VERSION "created by canmatrix"

NS_ :

BS_:

BU_: Matrix

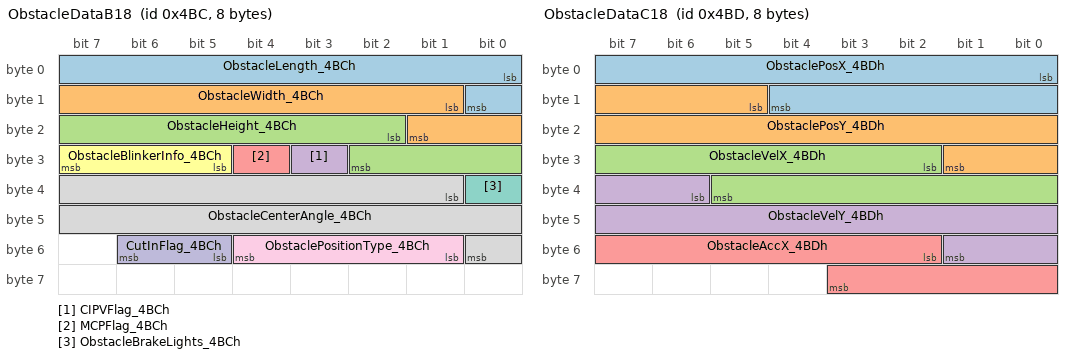
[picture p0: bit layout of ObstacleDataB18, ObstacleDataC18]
BO_ 1212 ObstacleDataB18: 8 Matrix
 SG_ ObstacleLength_4BCh : 0|9@1+ (0.05,0) [0.0|25.6] "m" Vector__XXX
 SG_ ObstacleWidth_4BCh : 9|9@1+ (0.02,0) [0.0|10.24] "m" Vector__XXX
 SG_ ObstacleHeight_4BCh : 18|9@1+ (0.02,0) [0.0|10.24] "m" Vector__XXX
 SG_ CIPVFlag_4BCh : 27|1@1+ (1,0) [0.0|1.0] "bool" Vector__XXX
 SG_ MCPFlag_4BCh : 28|1@1+ (1,0) [0.0|1.0] "bool" Vector__XXX
 SG_ ObstacleBlinkerInfo_4BCh : 29|3@1+ (1,0) [0.0|7.0] "enum" Vector__XXX
 SG_ ObstacleBrakeLights_4BCh : 32|1@1+ (1,0) [0.0|1.0] "bool" Vector__XXX
 SG_ ObstacleCenterAngle_4BCh : 33|16@1+ (0.01,-327.68) [-327.68|327.67] "degree" Vector__XXX
 SG_ ObstaclePositionType_4BCh : 49|4@1+ (1,0) [0.0|15.0] "enum" Vector__XXX
 SG_ CutInFlag_4BCh : 53|2@1+ (1,0) [0.0|3.0] "bool" Vector__XXX

BO_ 1213 ObstacleDataC18: 8 Matrix
 SG_ ObstaclePosX_4BDh : 0|13@1+ (0.0625,-250) [-250.0|250.0] "m" Vector__XXX
 SG_ ObstaclePosY_4BDh : 13|13@1+ (0.0625,-250) [-250.0|250.0] "m" Vector__XXX
 SG_ ObstacleVelX_4BDh : 26|12@1+ (0.05,-102.4) [-102.4|102.35] "m/sec" Vector__XXX
 SG_ ObstacleVelY_4BDh : 38|12@1+ (0.05,-50) [-50.0|50.0] "m/sec" Vector__XXX
 SG_ ObstacleAccX_4BDh : 50|10@1+ (0.03,-14.97) [-14.97|14.97] "m/s^2" Vector__XXX

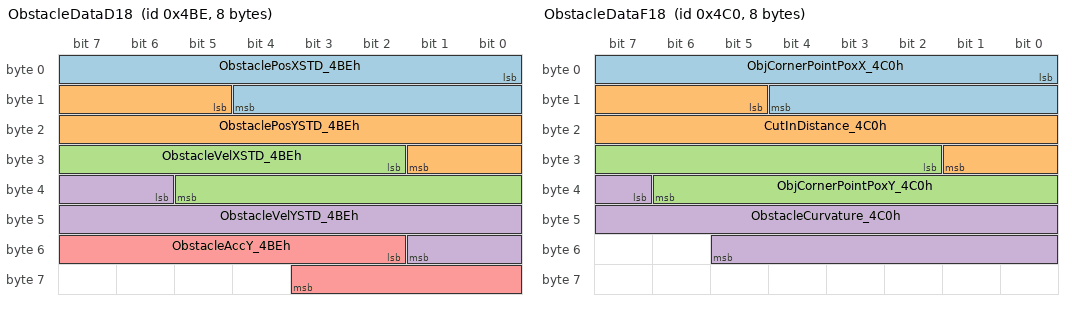
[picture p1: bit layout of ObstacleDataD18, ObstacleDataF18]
BO_ 1214 ObstacleDataD18: 8 Matrix
 SG_ ObstaclePosXSTD_4BEh : 0|13@1+ (0.0625,0) [0.0|250.0] "m" Vector__XXX
 SG_ ObstaclePosYSTD_4BEh : 13|13@1+ (0.0625,0) [0.0|250.0] "m" Vector__XXX
 SG_ ObstacleVelXSTD_4BEh : 26|12@1+ (0.05,0) [0.0|102.35] "m/sec" Vector__XXX
 SG_ ObstacleVelYSTD_4BEh : 38|12@1+ (0.05,0) [0.0|50.0] "m/sec" Vector__XXX
 SG_ ObstacleAccY_4BEh : 50|10@1+ (0.03,-14.97) [-14.97|14.97] "m/s^2" Vector__XXX

BO_ 1215 ObstacleDataE18: 8 Matrix
 SG_ ObstacleAngle_4BFh : 0|16@1+ (0.01,-327.68) [-327.68|327.67] "degree" Vector__XXX
 SG_ ObstacleAngleStd_4BFh : 16|16@1+ (0.01,0) [0.0|327.67] "degree" Vector__XXX
 SG_ ObstacleVelXAbs_4BFh : 32|12@1+ (0.05,-102.4) [-102.4|102.35] "m/sec" Vector__XXX
 SG_ ObstacleVelYAbs_4BFh : 44|12@1+ (0.05,-50) [-50.0|50.0] "m/sec" Vector__XXX

BO_ 1216 ObstacleDataF18: 8 Matrix
 SG_ ObjCornerPointPoxX_4C0h : 0|13@1+ (0.0625,-250) [-250.0|250.0] "m" Vector__XXX
 SG_ CutInDistance_4C0h : 13|13@1+ (0.0625,-250) [-250.0|250.0] "m" Vector__XXX
 SG_ ObjCornerPointPoxY_4C0h : 26|13@1+ (0.0625,-250) [-250.0|250.0] "m" Vector__XXX
 SG_ ObstacleCurvature_4C0h : 39|15@1+ (1,-9999) [-9999.0|9999.0] "m" Vector__XXX

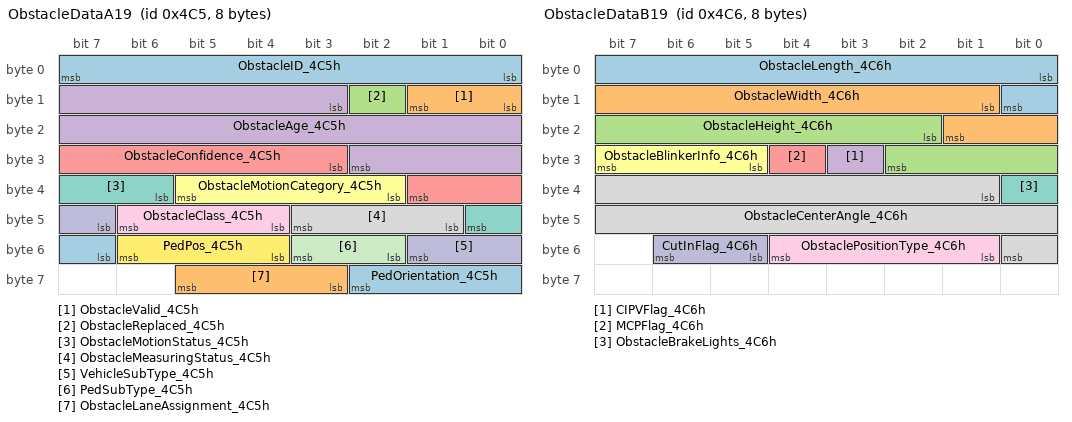
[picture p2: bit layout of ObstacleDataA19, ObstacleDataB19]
BO_ 1221 ObstacleDataA19: 8 Matrix
 SG_ ObstacleID_4C5h : 0|8@1+ (1,0) [0.0|255.0] "NA" Vector__XXX
 SG_ ObstacleValid_4C5h : 8|2@1+ (1,0) [0.0|3.0] "bool" Vector__XXX
 SG_ ObstacleReplaced_4C5h : 10|1@1+ (1,0) [0.0|1.0] "bool" Vector__XXX
 SG_ ObstacleAge_4C5h : 11|16@1+ (1,0) [0.0|65535.0] "NA" Vector__XXX
 SG_ ObstacleConfidence_4C5h : 27|7@1+ (1,0) [0.0|100.0] "NA" Vector__XXX
 SG_ ObstacleMotionCategory_4C5h : 34|4@1+ (1,0) [0.0|15.0] "enum" Vector__XXX
 SG_ ObstacleMotionStatus_4C5h : 38|3@1+ (1,0) [0.0|7.0] "enum" Vector__XXX
 SG_ ObstacleMeasuringStatus_4C5h : 41|3@1+ (1,0) [0.0|7.0] "enum" Vector__XXX
 SG_ ObstacleClass_4C5h : 44|3@1+ (1,0) [0.0|7.0] "enum" Vector__XXX
 SG_ VehicleSubType_4C5h : 47|3@1+ (1,0) [0.0|7.0] "enum" Vector__XXX
 SG_ PedSubType_4C5h : 50|2@1+ (1,0) [0.0|3.0] "enum" Vector__XXX
 SG_ PedPos_4C5h : 52|3@1+ (1,0) [0.0|7.0] "enum" Vector__XXX
 SG_ PedOrientation_4C5h : 55|4@1+ (1,0) [0.0|15.0] "enum" Vector__XXX
 SG_ ObstacleLaneAssignment_4C5h : 59|3@1+ (1,0) [0.0|7.0] "enum" Vector__XXX

BO_ 1222 ObstacleDataB19: 8 Matrix
 SG_ ObstacleLength_4C6h : 0|9@1+ (0.05,0) [0.0|25.6] "m" Vector__XXX
 SG_ ObstacleWidth_4C6h : 9|9@1+ (0.02,0) [0.0|10.24] "m" Vector__XXX
 SG_ ObstacleHeight_4C6h : 18|9@1+ (0.02,0) [0.0|10.24] "m" Vector__XXX
 SG_ CIPVFlag_4C6h : 27|1@1+ (1,0) [0.0|1.0] "bool" Vector__XXX
 SG_ MCPFlag_4C6h : 28|1@1+ (1,0) [0.0|1.0] "bool" Vector__XXX
 SG_ ObstacleBlinkerInfo_4C6h : 29|3@1+ (1,0) [0.0|7.0] "enum" Vector__XXX
 SG_ ObstacleBrakeLights_4C6h : 32|1@1+ (1,0) [0.0|1.0] "bool" Vector__XXX
 SG_ ObstacleCenterAngle_4C6h : 33|16@1+ (0.01,-327.68) [-327.68|327.67] "degree" Vector__XXX
 SG_ ObstaclePositionType_4C6h : 49|4@1+ (1,0) [0.0|15.0] "enum" Vector__XXX
 SG_ CutInFlag_4C6h : 53|2@1+ (1,0) [0.0|3.0] "bool" Vector__XXX

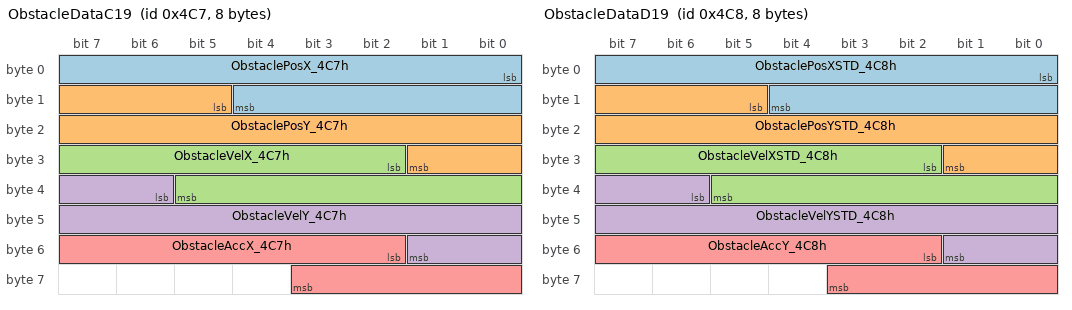
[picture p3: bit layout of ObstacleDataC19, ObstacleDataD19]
BO_ 1223 ObstacleDataC19: 8 Matrix
 SG_ ObstaclePosX_4C7h : 0|13@1+ (0.0625,-250) [-250.0|250.0] "m" Vector__XXX
 SG_ ObstaclePosY_4C7h : 13|13@1+ (0.0625,-250) [-250.0|250.0] "m" Vector__XXX
 SG_ ObstacleVelX_4C7h : 26|12@1+ (0.05,-102.4) [-102.4|102.35] "m/sec" Vector__XXX
 SG_ ObstacleVelY_4C7h : 38|12@1+ (0.05,-50) [-50.0|50.0] "m/sec" Vector__XXX
 SG_ ObstacleAccX_4C7h : 50|10@1+ (0.03,-14.97) [-14.97|14.97] "m/s^2" Vector__XXX

BO_ 1224 ObstacleDataD19: 8 Matrix
 SG_ ObstaclePosXSTD_4C8h : 0|13@1+ (0.0625,0) [0.0|250.0] "m" Vector__XXX
 SG_ ObstaclePosYSTD_4C8h : 13|13@1+ (0.0625,0) [0.0|250.0] "m" Vector__XXX
 SG_ ObstacleVelXSTD_4C8h : 26|12@1+ (0.05,0) [0.0|102.35] "m/sec" Vector__XXX
 SG_ ObstacleVelYSTD_4C8h : 38|12@1+ (0.05,0) [0.0|50.0] "m/sec" Vector__XXX
 SG_ ObstacleAccY_4C8h : 50|10@1+ (0.03,-14.97) [-14.97|14.97] "m/s^2" Vector__XXX

BO_ 1225 ObstacleDataE19: 8 Matrix
 SG_ ObstacleAngle_4C9h : 0|16@1+ (0.01,-327.68) [-327.68|327.67] "degree" Vector__XXX
 SG_ ObstacleAngleStd_4C9h : 16|16@1+ (0.01,0) [0.0|327.67] "degree" Vector__XXX
 SG_ ObstacleVelXAbs_4C9h : 32|12@1+ (0.05,-102.4) [-102.4|102.35] "m/sec" Vector__XXX
 SG_ ObstacleVelYAbs_4C9h : 44|12@1+ (0.05,-50) [-50.0|50.0] "m/sec" Vector__XXX

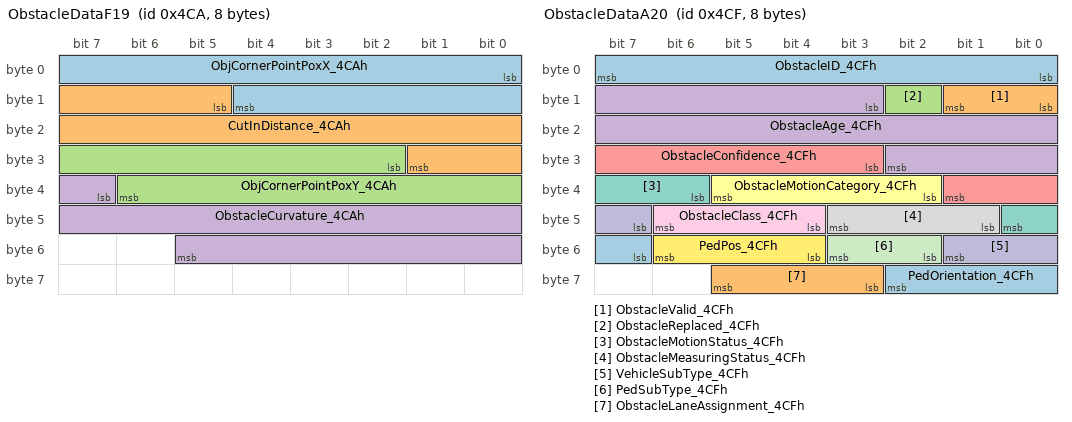
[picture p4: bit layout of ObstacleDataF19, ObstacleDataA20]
BO_ 1226 ObstacleDataF19: 8 Matrix
 SG_ ObjCornerPointPoxX_4CAh : 0|13@1+ (0.0625,-250) [-250.0|250.0] "m" Vector__XXX
 SG_ CutInDistance_4CAh : 13|13@1+ (0.0625,-250) [-250.0|250.0] "m" Vector__XXX
 SG_ ObjCornerPointPoxY_4CAh : 26|13@1+ (0.0625,-250) [-250.0|250.0] "m" Vector__XXX
 SG_ ObstacleCurvature_4CAh : 39|15@1+ (1,-9999) [-9999.0|9999.0] "m" Vector__XXX

BO_ 1231 ObstacleDataA20: 8 Matrix
 SG_ ObstacleID_4CFh : 0|8@1+ (1,0) [0.0|255.0] "NA" Vector__XXX
 SG_ ObstacleValid_4CFh : 8|2@1+ (1,0) [0.0|3.0] "bool" Vector__XXX
 SG_ ObstacleReplaced_4CFh : 10|1@1+ (1,0) [0.0|1.0] "bool" Vector__XXX
 SG_ ObstacleAge_4CFh : 11|16@1+ (1,0) [0.0|65535.0] "NA" Vector__XXX
 SG_ ObstacleConfidence_4CFh : 27|7@1+ (1,0) [0.0|100.0] "NA" Vector__XXX
 SG_ ObstacleMotionCategory_4CFh : 34|4@1+ (1,0) [0.0|15.0] "enum" Vector__XXX
 SG_ ObstacleMotionStatus_4CFh : 38|3@1+ (1,0) [0.0|7.0] "enum" Vector__XXX
 SG_ ObstacleMeasuringStatus_4CFh : 41|3@1+ (1,0) [0.0|7.0] "enum" Vector__XXX
 SG_ ObstacleClass_4CFh : 44|3@1+ (1,0) [0.0|7.0] "enum" Vector__XXX
 SG_ VehicleSubType_4CFh : 47|3@1+ (1,0) [0.0|7.0] "enum" Vector__XXX
 SG_ PedSubType_4CFh : 50|2@1+ (1,0) [0.0|3.0] "enum" Vector__XXX
 SG_ PedPos_4CFh : 52|3@1+ (1,0) [0.0|7.0] "enum" Vector__XXX
 SG_ PedOrientation_4CFh : 55|4@1+ (1,0) [0.0|15.0] "enum" Vector__XXX
 SG_ ObstacleLaneAssignment_4CFh : 59|3@1+ (1,0) [0.0|7.0] "enum" Vector__XXX

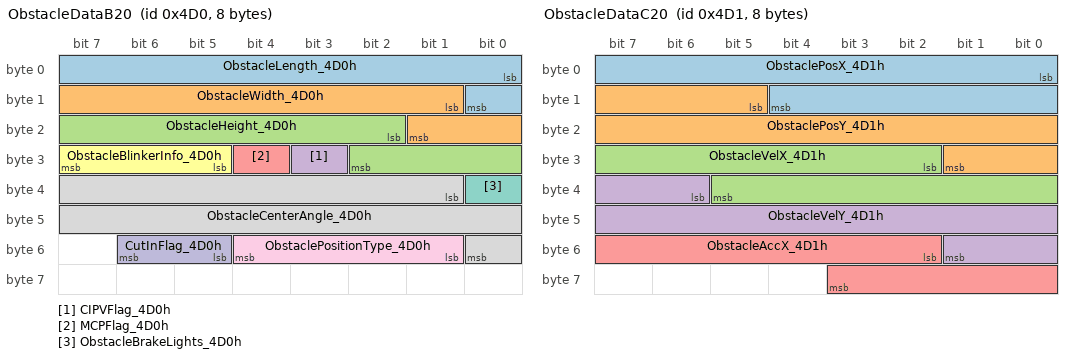
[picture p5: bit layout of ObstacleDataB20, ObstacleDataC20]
BO_ 1232 ObstacleDataB20: 8 Matrix
 SG_ ObstacleLength_4D0h : 0|9@1+ (0.05,0) [0.0|25.6] "m" Vector__XXX
 SG_ ObstacleWidth_4D0h : 9|9@1+ (0.02,0) [0.0|10.24] "m" Vector__XXX
 SG_ ObstacleHeight_4D0h : 18|9@1+ (0.02,0) [0.0|10.24] "m" Vector__XXX
 SG_ CIPVFlag_4D0h : 27|1@1+ (1,0) [0.0|1.0] "bool" Vector__XXX
 SG_ MCPFlag_4D0h : 28|1@1+ (1,0) [0.0|1.0] "bool" Vector__XXX
 SG_ ObstacleBlinkerInfo_4D0h : 29|3@1+ (1,0) [0.0|7.0] "enum" Vector__XXX
 SG_ ObstacleBrakeLights_4D0h : 32|1@1+ (1,0) [0.0|1.0] "bool" Vector__XXX
 SG_ ObstacleCenterAngle_4D0h : 33|16@1+ (0.01,-327.68) [-327.68|327.67] "degree" Vector__XXX
 SG_ ObstaclePositionType_4D0h : 49|4@1+ (1,0) [0.0|15.0] "enum" Vector__XXX
 SG_ CutInFlag_4D0h : 53|2@1+ (1,0) [0.0|3.0] "bool" Vector__XXX

BO_ 1233 ObstacleDataC20: 8 Matrix
 SG_ ObstaclePosX_4D1h : 0|13@1+ (0.0625,-250) [-250.0|250.0] "m" Vector__XXX
 SG_ ObstaclePosY_4D1h : 13|13@1+ (0.0625,-250) [-250.0|250.0] "m" Vector__XXX
 SG_ ObstacleVelX_4D1h : 26|12@1+ (0.05,-102.4) [-102.4|102.35] "m/sec" Vector__XXX
 SG_ ObstacleVelY_4D1h : 38|12@1+ (0.05,-50) [-50.0|50.0] "m/sec" Vector__XXX
 SG_ ObstacleAccX_4D1h : 50|10@1+ (0.03,-14.97) [-14.97|14.97] "m/s^2" Vector__XXX

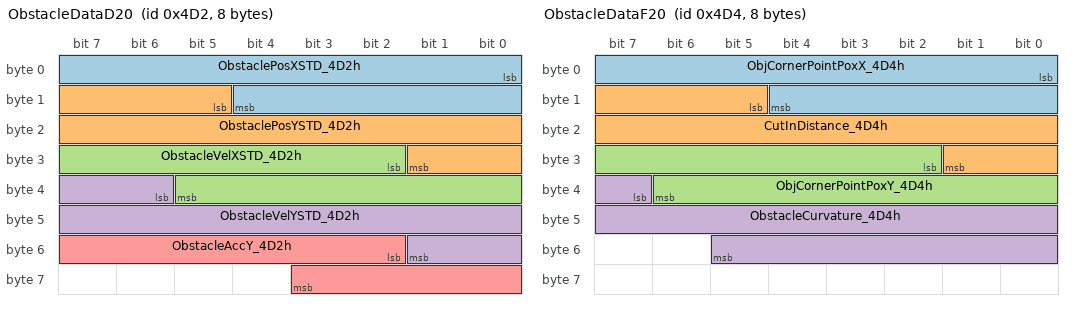
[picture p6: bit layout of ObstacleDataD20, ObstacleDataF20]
BO_ 1234 ObstacleDataD20: 8 Matrix
 SG_ ObstaclePosXSTD_4D2h : 0|13@1+ (0.0625,0) [0.0|250.0] "m" Vector__XXX
 SG_ ObstaclePosYSTD_4D2h : 13|13@1+ (0.0625,0) [0.0|250.0] "m" Vector__XXX
 SG_ ObstacleVelXSTD_4D2h : 26|12@1+ (0.05,0) [0.0|102.35] "m/sec" Vector__XXX
 SG_ ObstacleVelYSTD_4D2h : 38|12@1+ (0.05,0) [0.0|50.0] "m/sec" Vector__XXX
 SG_ ObstacleAccY_4D2h : 50|10@1+ (0.03,-14.97) [-14.97|14.97] "m/s^2" Vector__XXX

BO_ 1235 ObstacleDataE20: 8 Matrix
 SG_ ObstacleAngle_4D3h : 0|16@1+ (0.01,-327.68) [-327.68|327.67] "degree" Vector__XXX
 SG_ ObstacleAngleStd_4D3h : 16|16@1+ (0.01,0) [0.0|327.67] "degree" Vector__XXX
 SG_ ObstacleVelXAbs_4D3h : 32|12@1+ (0.05,-102.4) [-102.4|102.35] "m/sec" Vector__XXX
 SG_ ObstacleVelYAbs_4D3h : 44|12@1+ (0.05,-50) [-50.0|50.0] "m/sec" Vector__XXX

BO_ 1236 ObstacleDataF20: 8 Matrix
 SG_ ObjCornerPointPoxX_4D4h : 0|13@1+ (0.0625,-250) [-250.0|250.0] "m" Vector__XXX
 SG_ CutInDistance_4D4h : 13|13@1+ (0.0625,-250) [-250.0|250.0] "m" Vector__XXX
 SG_ ObjCornerPointPoxY_4D4h : 26|13@1+ (0.0625,-250) [-250.0|250.0] "m" Vector__XXX
 SG_ ObstacleCurvature_4D4h : 39|15@1+ (1,-9999) [-9999.0|9999.0] "m" Vector__XXX

BO_ 1241 ObstacleInternalID12: 8 Matrix
 SG_ Obstacle_Internal_ID1_4D9h : 0|32@1+ (1,0) [0.0|4294970000.0] "NA" Vector__XXX
 SG_ Obstacle_Internal_ID2_4D9h : 32|32@1+ (1,0) [0.0|4294970000.0] "NA" Vector__XXX

BO_ 1242 ObstacleInternalID34: 8 Matrix
 SG_ Obstacle_Internal_ID3_4DAh : 0|32@1+ (1,0) [0.0|4294970000.0] "NA" Vector__XXX
 SG_ Obstacle_Internal_ID4_4DAh : 32|32@1+ (1,0) [0.0|4294970000.0] "NA" Vector__XXX

BO_ 1243 ObstacleInternalID56: 8 Matrix
 SG_ Obstacle_Internal_ID5_4DBh : 0|32@1+ (1,0) [0.0|4294970000.0] "NA" Vector__XXX
 SG_ Obstacle_Internal_ID6_4DBh : 32|32@1+ (1,0) [0.0|4294970000.0] "NA" Vector__XXX

BO_ 1244 ObstacleInternalID78: 8 Matrix
 SG_ Obstacle_Internal_ID7_4DCh : 0|32@1+ (1,0) [0.0|4294970000.0] "NA" Vector__XXX
 SG_ Obstacle_Internal_ID8_4DCh : 32|32@1+ (1,0) [0.0|4294970000.0] "NA" Vector__XXX

BO_ 1245 ObstacleInternalID90: 8 Matrix
 SG_ Obstacle_Internal_ID9_4DDh : 0|32@1+ (1,0) [0.0|4294970000.0] "NA" Vector__XXX
 SG_ Obstacle_Internal_ID10_4DDh : 32|32@1+ (1,0) [0.0|4294970000.0] "NA" Vector__XXX

BO_ 1246 ObstacleInternalID1112: 8 Matrix
 SG_ Obstacle_Internal_ID11_4DEh : 0|32@1+ (1,0) [0.0|4294970000.0] "NA" Vector__XXX
 SG_ Obstacle_Internal_ID12_4DEh : 32|32@1+ (1,0) [0.0|4294970000.0] "NA" Vector__XXX

BO_ 1247 ObstacleInternalID1314: 8 Matrix
 SG_ Obstacle_Internal_ID13_4DFh : 0|32@1+ (1,0) [0.0|4294970000.0] "NA" Vector__XXX
 SG_ Obstacle_Internal_ID14_4DFh : 32|32@1+ (1,0) [0.0|4294970000.0] "NA" Vector__XXX

BO_ 1248 ObstacleInternalID1516: 8 Matrix
 SG_ Obstacle_Internal_ID15_4E0h : 0|32@1+ (1,0) [0.0|4294970000.0] "NA" Vector__XXX
 SG_ Obstacle_Internal_ID16_4E0h : 32|32@1+ (1,0) [0.0|4294970000.0] "NA" Vector__XXX

BO_ 1249 ObstacleInternalID1718: 8 Matrix
 SG_ Obstacle_Internal_ID17_4E1h : 0|32@1+ (1,0) [0.0|4294970000.0] "NA" Vector__XXX
 SG_ Obstacle_Internal_ID18_4E1h : 32|32@1+ (1,0) [0.0|4294970000.0] "NA" Vector__XXX

BO_ 1250 ObstacleInternalID1920: 8 Matrix
 SG_ Obstacle_Internal_ID19_4E2h : 0|32@1+ (1,0) [0.0|4294970000.0] "NA" Vector__XXX
 SG_ Obstacle_Internal_ID20_4E2h : 32|32@1+ (1,0) [0.0|4294970000.0] "NA" Vector__XXX

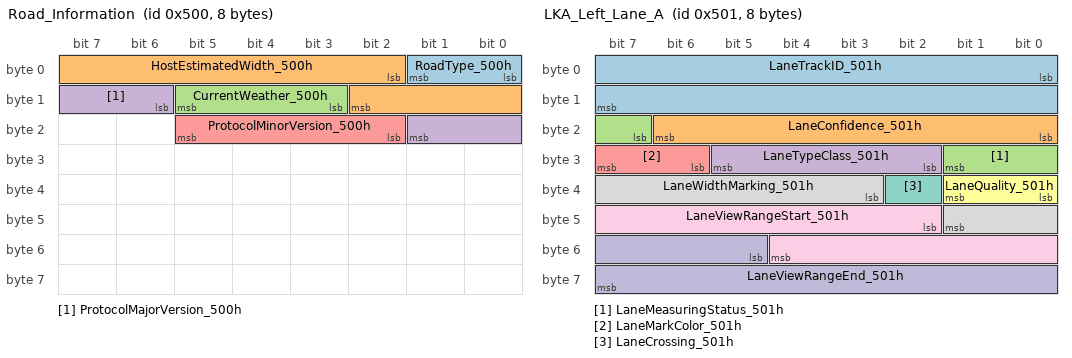
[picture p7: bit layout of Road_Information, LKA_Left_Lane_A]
BO_ 1280 Road_Information: 8 Matrix
 SG_ RoadType_500h : 0|2@1+ (1,0) [0.0|3.0] "Enum" Vector__XXX
 SG_ HostEstimatedWidth_500h : 2|9@1+ (1,0) [0.0|4.0] "meter" Vector__XXX
 SG_ CurrentWeather_500h : 11|3@1+ (1,0) [0.0|7.0] "Enum" Vector__XXX
 SG_ ProtocolMajorVersion_500h : 14|4@1+ (1,0) [0.0|15.0] "NA" Vector__XXX
 SG_ ProtocolMinorVersion_500h : 18|4@1+ (1,0) [0.0|15.0] "NA" Vector__XXX

BO_ 1281 LKA_Left_Lane_A: 8 Matrix
 SG_ LaneTrackID_501h : 0|16@1+ (1,0) [0.0|65535.0] "NA" Vector__XXX
 SG_ LaneConfidence_501h : 16|7@1+ (1,0) [0.0|100.0] "prob" Vector__XXX
 SG_ LaneMeasuringStatus_501h : 23|3@1+ (1,0) [0.0|7.0] "enum" Vector__XXX
 SG_ LaneTypeClass_501h : 26|4@1+ (1,0) [0.0|15.0] "Enum" Vector__XXX
 SG_ LaneMarkColor_501h : 30|2@1+ (1,0) [0.0|3.0] "Enum" Vector__XXX
 SG_ LaneQuality_501h : 32|2@1+ (1,0) [0.0|3.0] "Enum" Vector__XXX
 SG_ LaneCrossing_501h : 34|1@1+ (1,0) [0.0|1.0] "NA" Vector__XXX
 SG_ LaneWidthMarking_501h : 35|7@1+ (0.01,0) [0.0|127.0] "m" Vector__XXX
 SG_ LaneViewRangeStart_501h : 42|11@1+ (0.1,0) [0.0|200.0] "meter" Vector__XXX
 SG_ LaneViewRangeEnd_501h : 53|11@1+ (0.1,0) [0.0|200.0] "meter" Vector__XXX

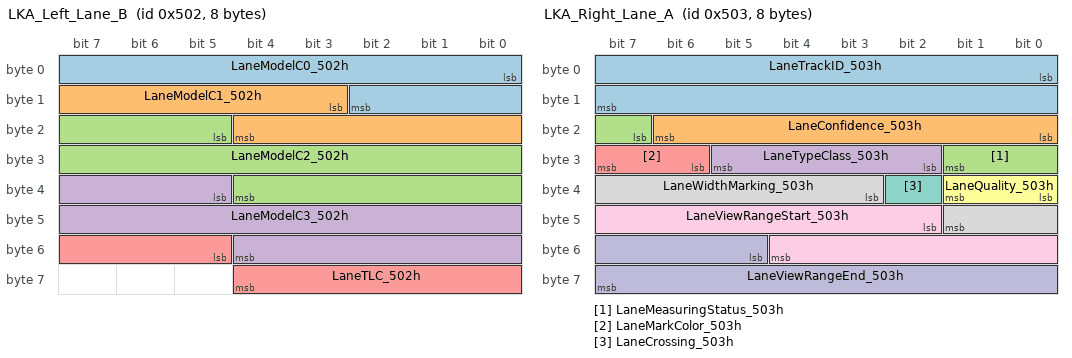
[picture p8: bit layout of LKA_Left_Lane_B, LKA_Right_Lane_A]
BO_ 1282 LKA_Left_Lane_B: 8 Matrix
 SG_ LaneModelC0_502h : 0|11@1+ (0.01,-10) [-10.0|10.0] "meter" Vector__XXX
 SG_ LaneModelC1_502h : 11|10@1+ (0.000976562,-0.357) [-0.357|0.357] "rad" Vector__XXX
 SG_ LaneModelC2_502h : 21|16@1+ (9.77e-07,-0.032) [-0.032|0.032] "1/meter" Vector__XXX
 SG_ LaneModelC3_502h : 37|16@1+ (3.72529e-09,-0.000122) [-0.000122|0.000122] "1/meter^2" Vector__XXX
 SG_ LaneTLC_502h : 53|8@1+ (0.01,0) [0.0|2.0] "s" Vector__XXX

BO_ 1283 LKA_Right_Lane_A: 8 Matrix
 SG_ LaneTrackID_503h : 0|16@1+ (1,0) [0.0|65535.0] "NA" Vector__XXX
 SG_ LaneConfidence_503h : 16|7@1+ (1,0) [0.0|100.0] "prob" Vector__XXX
 SG_ LaneMeasuringStatus_503h : 23|3@1+ (1,0) [0.0|7.0] "enum" Vector__XXX
 SG_ LaneTypeClass_503h : 26|4@1+ (1,0) [0.0|15.0] "Enum" Vector__XXX
 SG_ LaneMarkColor_503h : 30|2@1+ (1,0) [0.0|3.0] "Enum" Vector__XXX
 SG_ LaneQuality_503h : 32|2@1+ (1,0) [0.0|3.0] "Enum" Vector__XXX
 SG_ LaneCrossing_503h : 34|1@1+ (1,0) [0.0|1.0] "NA" Vector__XXX
 SG_ LaneWidthMarking_503h : 35|7@1+ (0.01,0) [0.0|127.0] "m" Vector__XXX
 SG_ LaneViewRangeStart_503h : 42|11@1+ (0.1,0) [0.0|200.0] "meter" Vector__XXX
 SG_ LaneViewRangeEnd_503h : 53|11@1+ (0.1,0) [0.0|200.0] "meter" Vector__XXX

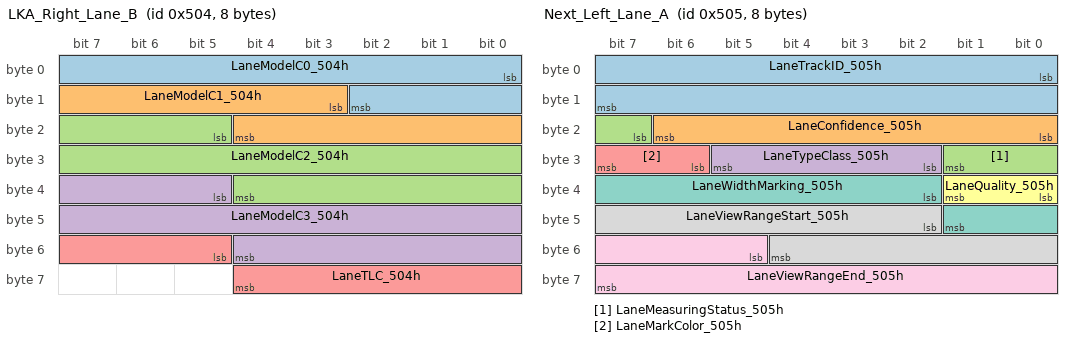
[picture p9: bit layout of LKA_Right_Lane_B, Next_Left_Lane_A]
BO_ 1284 LKA_Right_Lane_B: 8 Matrix
 SG_ LaneModelC0_504h : 0|11@1+ (0.01,-10) [-10.0|10.0] "meter" Vector__XXX
 SG_ LaneModelC1_504h : 11|10@1+ (0.000976562,-0.357) [-0.357|0.357] "rad" Vector__XXX
 SG_ LaneModelC2_504h : 21|16@1+ (9.77e-07,-0.032) [-0.032|0.032] "1/meter" Vector__XXX
 SG_ LaneModelC3_504h : 37|16@1+ (3.72529e-09,-0.000122) [-0.000122|0.000122] "1/meter^2" Vector__XXX
 SG_ LaneTLC_504h : 53|8@1+ (0.01,0) [0.0|2.0] "s" Vector__XXX

BO_ 1285 Next_Left_Lane_A: 8 Matrix
 SG_ LaneTrackID_505h : 0|16@1+ (1,0) [0.0|65535.0] "NA" Vector__XXX
 SG_ LaneConfidence_505h : 16|7@1+ (1,0) [0.0|100.0] "prob" Vector__XXX
 SG_ LaneMeasuringStatus_505h : 23|3@1+ (1,0) [0.0|7.0] "enum" Vector__XXX
 SG_ LaneTypeClass_505h : 26|4@1+ (1,0) [0.0|15.0] "Enum" Vector__XXX
 SG_ LaneMarkColor_505h : 30|2@1+ (1,0) [0.0|3.0] "Enum" Vector__XXX
 SG_ LaneQuality_505h : 32|2@1+ (1,0) [0.0|3.0] "Enum" Vector__XXX
 SG_ LaneWidthMarking_505h : 34|8@1+ (0.01,0) [0.0|255.0] "m" Vector__XXX
 SG_ LaneViewRangeStart_505h : 42|11@1+ (0.1,0) [0.0|200.0] "meter" Vector__XXX
 SG_ LaneViewRangeEnd_505h : 53|11@1+ (0.1,0) [0.0|200.0] "meter" Vector__XXX

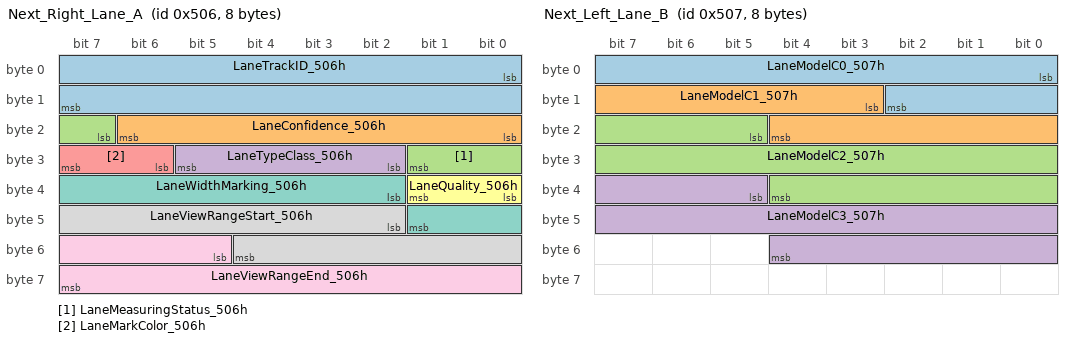
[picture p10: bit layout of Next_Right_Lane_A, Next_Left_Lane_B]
BO_ 1286 Next_Right_Lane_A: 8 Matrix
 SG_ LaneTrackID_506h : 0|16@1+ (1,0) [0.0|65535.0] "NA" Vector__XXX
 SG_ LaneConfidence_506h : 16|7@1+ (1,0) [0.0|100.0] "prob" Vector__XXX
 SG_ LaneMeasuringStatus_506h : 23|3@1+ (1,0) [0.0|7.0] "enum" Vector__XXX
 SG_ LaneTypeClass_506h : 26|4@1+ (1,0) [0.0|15.0] "Enum" Vector__XXX
 SG_ LaneMarkColor_506h : 30|2@1+ (1,0) [0.0|3.0] "Enum" Vector__XXX
 SG_ LaneQuality_506h : 32|2@1+ (1,0) [0.0|3.0] "Enum" Vector__XXX
 SG_ LaneWidthMarking_506h : 34|8@1+ (0.01,0) [0.0|255.0] "m" Vector__XXX
 SG_ LaneViewRangeStart_506h : 42|11@1+ (0.1,0) [0.0|200.0] "meter" Vector__XXX
 SG_ LaneViewRangeEnd_506h : 53|11@1+ (0.1,0) [0.0|200.0] "meter" Vector__XXX

BO_ 1287 Next_Left_Lane_B: 8 Matrix
 SG_ LaneModelC0_507h : 0|11@1+ (0.01,-10) [-10.0|10.0] "meter" Vector__XXX
 SG_ LaneModelC1_507h : 11|10@1+ (0.000976562,-0.357) [-0.357|0.357] "rad" Vector__XXX
 SG_ LaneModelC2_507h : 21|16@1+ (9.77e-07,-0.032) [-0.032|0.032] "1/meter" Vector__XXX
 SG_ LaneModelC3_507h : 37|16@1+ (3.72529e-09,-0.000122) [-0.000122|0.000122] "1/meter^2" Vector__XXX

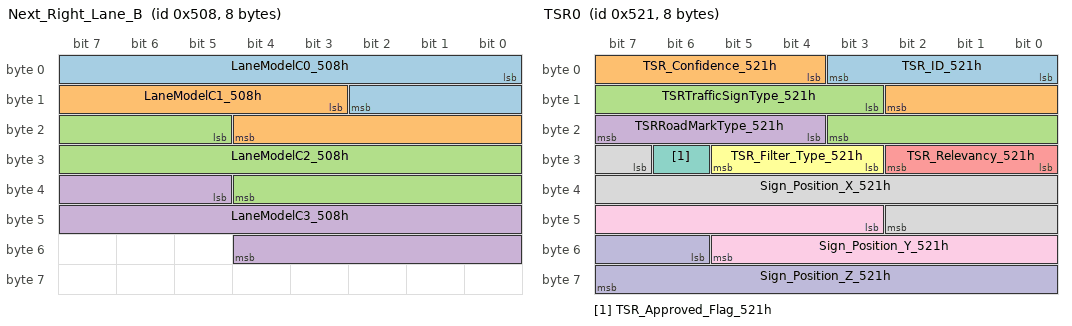
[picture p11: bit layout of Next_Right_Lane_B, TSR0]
BO_ 1288 Next_Right_Lane_B: 8 Matrix
 SG_ LaneModelC0_508h : 0|11@1+ (0.01,-10) [-10.0|10.0] "meter" Vector__XXX
 SG_ LaneModelC1_508h : 11|10@1+ (0.000976562,-0.357) [-0.357|0.357] "rad" Vector__XXX
 SG_ LaneModelC2_508h : 21|16@1+ (9.77e-07,-0.032) [-0.032|0.032] "1/meter" Vector__XXX
 SG_ LaneModelC3_508h : 37|16@1+ (3.72529e-09,-0.000122) [-0.000122|0.000122] "1/meter^2" Vector__XXX

BO_ 1312 TSR_Header: 8 Matrix
 SG_ TSRObjectsNumber_520h : 0|4@1+ (1,0) [0.0|8.0] "uint" Vector__XXX
 SG_ ProtocolMajorVersion_520h : 4|4@1+ (1,0) [0.0|15.0] "NA" Vector__XXX
 SG_ ProtocolMinorVersion_520h : 8|4@1+ (1,0) [0.0|15.0] "NA" Vector__XXX

BO_ 1313 TSR0: 8 Matrix
 SG_ TSR_ID_521h : 0|4@1+ (1,0) [0.0|15.0] "NA" Vector__XXX
 SG_ TSR_Confidence_521h : 4|7@1+ (1,0) [0.0|100.0] "NA" Vector__XXX
 SG_ TSRTrafficSignType_521h : 11|9@1+ (1,0) [0.0|511.0] "ENUM" Vector__XXX
 SG_ TSRRoadMarkType_521h : 20|4@1+ (1,0) [0.0|15.0] "ENUM" Vector__XXX
 SG_ TSR_Relevancy_521h : 24|3@1+ (1,0) [0.0|7.0] "ENUM" Vector__XXX
 SG_ TSR_Filter_Type_521h : 27|3@1+ (1,0) [0.0|7.0] "ENUM" Vector__XXX
 SG_ TSR_Approved_Flag_521h : 30|1@1+ (1,0) [0.0|1.0] "bool" Vector__XXX
 SG_ Sign_Position_X_521h : 31|12@1+ (0.05,0) [0.0|200.0] "meters" Vector__XXX
 SG_ Sign_Position_Y_521h : 43|11@1+ (0.05,-32) [-32.0|32.0] "meters" Vector__XXX
 SG_ Sign_Position_Z_521h : 54|10@1+ (0.05,0) [0.0|40.0] "meters" Vector__XXX

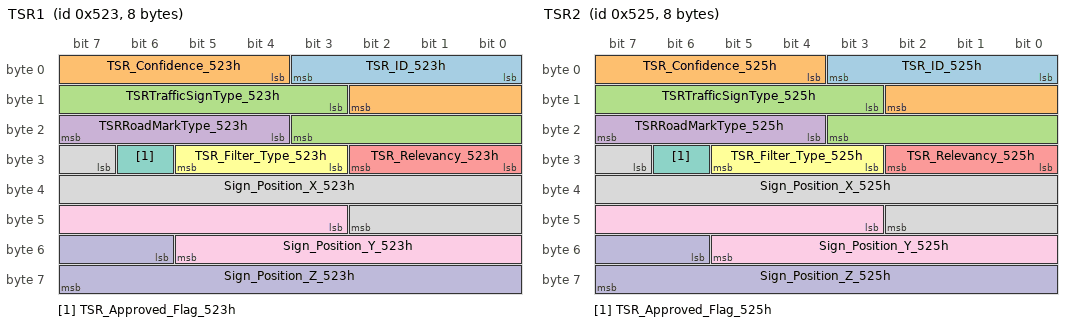
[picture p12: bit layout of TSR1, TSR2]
BO_ 1315 TSR1: 8 Matrix
 SG_ TSR_ID_523h : 0|4@1+ (1,0) [0.0|15.0] "NA" Vector__XXX
 SG_ TSR_Confidence_523h : 4|7@1+ (1,0) [0.0|100.0] "NA" Vector__XXX
 SG_ TSRTrafficSignType_523h : 11|9@1+ (1,0) [0.0|511.0] "ENUM" Vector__XXX
 SG_ TSRRoadMarkType_523h : 20|4@1+ (1,0) [0.0|15.0] "ENUM" Vector__XXX
 SG_ TSR_Relevancy_523h : 24|3@1+ (1,0) [0.0|7.0] "ENUM" Vector__XXX
 SG_ TSR_Filter_Type_523h : 27|3@1+ (1,0) [0.0|7.0] "ENUM" Vector__XXX
 SG_ TSR_Approved_Flag_523h : 30|1@1+ (1,0) [0.0|1.0] "bool" Vector__XXX
 SG_ Sign_Position_X_523h : 31|12@1+ (0.05,0) [0.0|200.0] "meters" Vector__XXX
 SG_ Sign_Position_Y_523h : 43|11@1+ (0.05,-32) [-32.0|32.0] "meters" Vector__XXX
 SG_ Sign_Position_Z_523h : 54|10@1+ (0.05,0) [0.0|40.0] "meters" Vector__XXX

BO_ 1317 TSR2: 8 Matrix
 SG_ TSR_ID_525h : 0|4@1+ (1,0) [0.0|15.0] "NA" Vector__XXX
 SG_ TSR_Confidence_525h : 4|7@1+ (1,0) [0.0|100.0] "NA" Vector__XXX
 SG_ TSRTrafficSignType_525h : 11|9@1+ (1,0) [0.0|511.0] "ENUM" Vector__XXX
 SG_ TSRRoadMarkType_525h : 20|4@1+ (1,0) [0.0|15.0] "ENUM" Vector__XXX
 SG_ TSR_Relevancy_525h : 24|3@1+ (1,0) [0.0|7.0] "ENUM" Vector__XXX
 SG_ TSR_Filter_Type_525h : 27|3@1+ (1,0) [0.0|7.0] "ENUM" Vector__XXX
 SG_ TSR_Approved_Flag_525h : 30|1@1+ (1,0) [0.0|1.0] "bool" Vector__XXX
 SG_ Sign_Position_X_525h : 31|12@1+ (0.05,0) [0.0|200.0] "meters" Vector__XXX
 SG_ Sign_Position_Y_525h : 43|11@1+ (0.05,-32) [-32.0|32.0] "meters" Vector__XXX
 SG_ Sign_Position_Z_525h : 54|10@1+ (0.05,0) [0.0|40.0] "meters" Vector__XXX

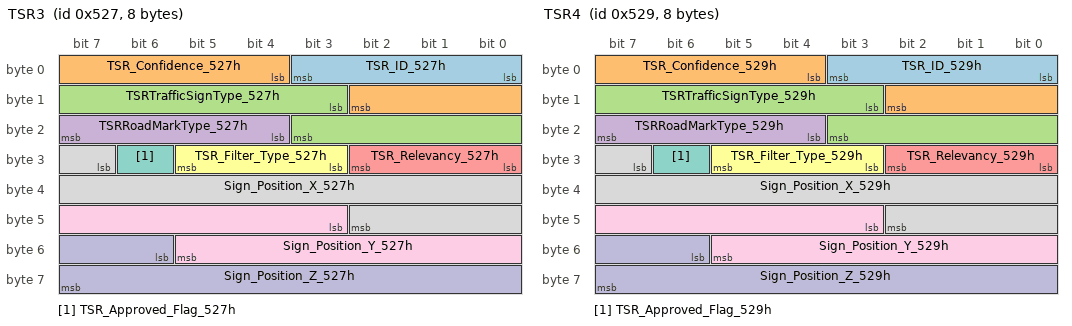
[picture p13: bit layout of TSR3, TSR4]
BO_ 1319 TSR3: 8 Matrix
 SG_ TSR_ID_527h : 0|4@1+ (1,0) [0.0|15.0] "NA" Vector__XXX
 SG_ TSR_Confidence_527h : 4|7@1+ (1,0) [0.0|100.0] "NA" Vector__XXX
 SG_ TSRTrafficSignType_527h : 11|9@1+ (1,0) [0.0|511.0] "ENUM" Vector__XXX
 SG_ TSRRoadMarkType_527h : 20|4@1+ (1,0) [0.0|15.0] "ENUM" Vector__XXX
 SG_ TSR_Relevancy_527h : 24|3@1+ (1,0) [0.0|7.0] "ENUM" Vector__XXX
 SG_ TSR_Filter_Type_527h : 27|3@1+ (1,0) [0.0|7.0] "ENUM" Vector__XXX
 SG_ TSR_Approved_Flag_527h : 30|1@1+ (1,0) [0.0|1.0] "bool" Vector__XXX
 SG_ Sign_Position_X_527h : 31|12@1+ (0.05,0) [0.0|200.0] "meters" Vector__XXX
 SG_ Sign_Position_Y_527h : 43|11@1+ (0.05,-32) [-32.0|32.0] "meters" Vector__XXX
 SG_ Sign_Position_Z_527h : 54|10@1+ (0.05,0) [0.0|40.0] "meters" Vector__XXX

BO_ 1321 TSR4: 8 Matrix
 SG_ TSR_ID_529h : 0|4@1+ (1,0) [0.0|15.0] "NA" Vector__XXX
 SG_ TSR_Confidence_529h : 4|7@1+ (1,0) [0.0|100.0] "NA" Vector__XXX
 SG_ TSRTrafficSignType_529h : 11|9@1+ (1,0) [0.0|511.0] "ENUM" Vector__XXX
 SG_ TSRRoadMarkType_529h : 20|4@1+ (1,0) [0.0|15.0] "ENUM" Vector__XXX
 SG_ TSR_Relevancy_529h : 24|3@1+ (1,0) [0.0|7.0] "ENUM" Vector__XXX
 SG_ TSR_Filter_Type_529h : 27|3@1+ (1,0) [0.0|7.0] "ENUM" Vector__XXX
 SG_ TSR_Approved_Flag_529h : 30|1@1+ (1,0) [0.0|1.0] "bool" Vector__XXX
 SG_ Sign_Position_X_529h : 31|12@1+ (0.05,0) [0.0|200.0] "meters" Vector__XXX
 SG_ Sign_Position_Y_529h : 43|11@1+ (0.05,-32) [-32.0|32.0] "meters" Vector__XXX
 SG_ Sign_Position_Z_529h : 54|10@1+ (0.05,0) [0.0|40.0] "meters" Vector__XXX

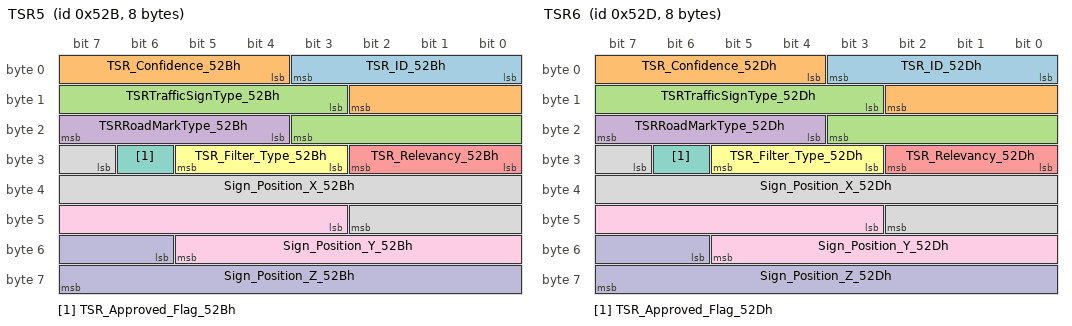
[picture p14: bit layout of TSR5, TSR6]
BO_ 1323 TSR5: 8 Matrix
 SG_ TSR_ID_52Bh : 0|4@1+ (1,0) [0.0|15.0] "NA" Vector__XXX
 SG_ TSR_Confidence_52Bh : 4|7@1+ (1,0) [0.0|100.0] "NA" Vector__XXX
 SG_ TSRTrafficSignType_52Bh : 11|9@1+ (1,0) [0.0|511.0] "ENUM" Vector__XXX
 SG_ TSRRoadMarkType_52Bh : 20|4@1+ (1,0) [0.0|15.0] "ENUM" Vector__XXX
 SG_ TSR_Relevancy_52Bh : 24|3@1+ (1,0) [0.0|7.0] "ENUM" Vector__XXX
 SG_ TSR_Filter_Type_52Bh : 27|3@1+ (1,0) [0.0|7.0] "ENUM" Vector__XXX
 SG_ TSR_Approved_Flag_52Bh : 30|1@1+ (1,0) [0.0|1.0] "bool" Vector__XXX
 SG_ Sign_Position_X_52Bh : 31|12@1+ (0.05,0) [0.0|200.0] "meters" Vector__XXX
 SG_ Sign_Position_Y_52Bh : 43|11@1+ (0.05,-32) [-32.0|32.0] "meters" Vector__XXX
 SG_ Sign_Position_Z_52Bh : 54|10@1+ (0.05,0) [0.0|40.0] "meters" Vector__XXX

BO_ 1325 TSR6: 8 Matrix
 SG_ TSR_ID_52Dh : 0|4@1+ (1,0) [0.0|15.0] "NA" Vector__XXX
 SG_ TSR_Confidence_52Dh : 4|7@1+ (1,0) [0.0|100.0] "NA" Vector__XXX
 SG_ TSRTrafficSignType_52Dh : 11|9@1+ (1,0) [0.0|511.0] "ENUM" Vector__XXX
 SG_ TSRRoadMarkType_52Dh : 20|4@1+ (1,0) [0.0|15.0] "ENUM" Vector__XXX
 SG_ TSR_Relevancy_52Dh : 24|3@1+ (1,0) [0.0|7.0] "ENUM" Vector__XXX
 SG_ TSR_Filter_Type_52Dh : 27|3@1+ (1,0) [0.0|7.0] "ENUM" Vector__XXX
 SG_ TSR_Approved_Flag_52Dh : 30|1@1+ (1,0) [0.0|1.0] "bool" Vector__XXX
 SG_ Sign_Position_X_52Dh : 31|12@1+ (0.05,0) [0.0|200.0] "meters" Vector__XXX
 SG_ Sign_Position_Y_52Dh : 43|11@1+ (0.05,-32) [-32.0|32.0] "meters" Vector__XXX
 SG_ Sign_Position_Z_52Dh : 54|10@1+ (0.05,0) [0.0|40.0] "meters" Vector__XXX

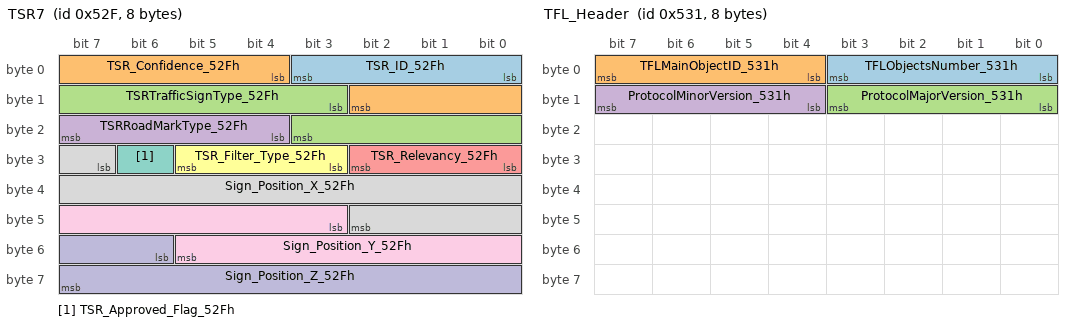
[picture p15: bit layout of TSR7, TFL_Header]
BO_ 1327 TSR7: 8 Matrix
 SG_ TSR_ID_52Fh : 0|4@1+ (1,0) [0.0|15.0] "NA" Vector__XXX
 SG_ TSR_Confidence_52Fh : 4|7@1+ (1,0) [0.0|100.0] "NA" Vector__XXX
 SG_ TSRTrafficSignType_52Fh : 11|9@1+ (1,0) [0.0|511.0] "ENUM" Vector__XXX
 SG_ TSRRoadMarkType_52Fh : 20|4@1+ (1,0) [0.0|15.0] "ENUM" Vector__XXX
 SG_ TSR_Relevancy_52Fh : 24|3@1+ (1,0) [0.0|7.0] "ENUM" Vector__XXX
 SG_ TSR_Filter_Type_52Fh : 27|3@1+ (1,0) [0.0|7.0] "ENUM" Vector__XXX
 SG_ TSR_Approved_Flag_52Fh : 30|1@1+ (1,0) [0.0|1.0] "bool" Vector__XXX
 SG_ Sign_Position_X_52Fh : 31|12@1+ (0.05,0) [0.0|200.0] "meters" Vector__XXX
 SG_ Sign_Position_Y_52Fh : 43|11@1+ (0.05,-32) [-32.0|32.0] "meters" Vector__XXX
 SG_ Sign_Position_Z_52Fh : 54|10@1+ (0.05,0) [0.0|40.0] "meters" Vector__XXX

BO_ 1329 TFL_Header: 8 Matrix
 SG_ TFLObjectsNumber_531h : 0|4@1+ (1,0) [0.0|8.0] "NA" Vector__XXX
 SG_ TFLMainObjectID_531h : 4|4@1+ (1,0) [0.0|8.0] "NA" Vector__XXX
 SG_ ProtocolMajorVersion_531h : 8|4@1+ (1,0) [0.0|15.0] "NA" Vector__XXX
 SG_ ProtocolMinorVersion_531h : 12|4@1+ (1,0) [0.0|15.0] "NA" Vector__XXX

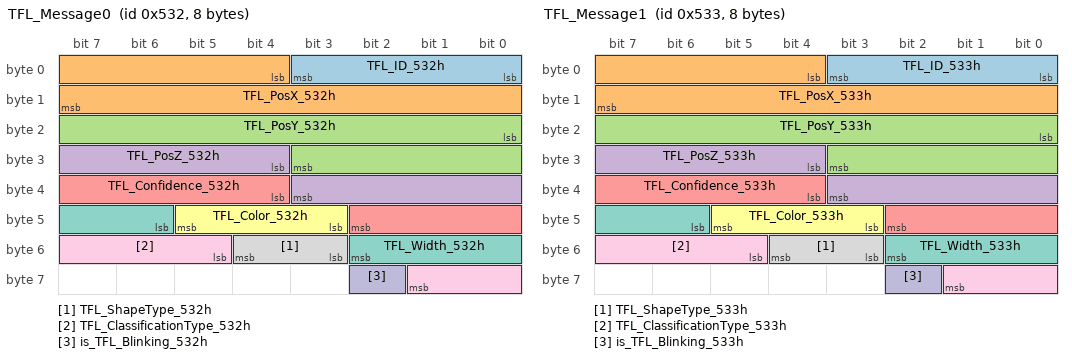
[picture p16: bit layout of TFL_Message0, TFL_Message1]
BO_ 1330 TFL_Message0: 8 Matrix
 SG_ TFL_ID_532h : 0|4@1+ (1,0) [0.0|15.0] "NA" Vector__XXX
 SG_ TFL_PosX_532h : 4|12@1+ (0.0625,0) [0.0|255.938] "m" Vector__XXX
 SG_ TFL_PosY_532h : 16|12@1+ (0.125,-256) [-256.0|255.875] "m" Vector__XXX
 SG_ TFL_PosZ_532h : 28|8@1+ (0.125,0) [0.0|31.875] "m" Vector__XXX
 SG_ TFL_Confidence_532h : 36|7@1+ (1,0) [0.0|100.0] "NA" Vector__XXX
 SG_ TFL_Color_532h : 43|3@1+ (1,0) [0.0|7.0] "Enum" Vector__XXX
 SG_ TFL_Width_532h : 46|5@1+ (0.03125,0) [0.0|0.96875] "m" Vector__XXX
 SG_ TFL_ShapeType_532h : 51|2@1+ (1,0) [0.0|3.0] "Enum" Vector__XXX
 SG_ TFL_ClassificationType_532h : 53|5@1+ (1,0) [0.0|31.0] "Enum" Vector__XXX
 SG_ is_TFL_Blinking_532h : 58|1@1+ (1,0) [0.0|1.0] "boolean" Vector__XXX

BO_ 1331 TFL_Message1: 8 Matrix
 SG_ TFL_ID_533h : 0|4@1+ (1,0) [0.0|15.0] "NA" Vector__XXX
 SG_ TFL_PosX_533h : 4|12@1+ (0.0625,0) [0.0|255.938] "m" Vector__XXX
 SG_ TFL_PosY_533h : 16|12@1+ (0.125,-256) [-256.0|255.875] "m" Vector__XXX
 SG_ TFL_PosZ_533h : 28|8@1+ (0.125,0) [0.0|31.875] "m" Vector__XXX
 SG_ TFL_Confidence_533h : 36|7@1+ (1,0) [0.0|100.0] "NA" Vector__XXX
 SG_ TFL_Color_533h : 43|3@1+ (1,0) [0.0|7.0] "Enum" Vector__XXX
 SG_ TFL_Width_533h : 46|5@1+ (0.03125,0) [0.0|0.96875] "m" Vector__XXX
 SG_ TFL_ShapeType_533h : 51|2@1+ (1,0) [0.0|3.0] "Enum" Vector__XXX
 SG_ TFL_ClassificationType_533h : 53|5@1+ (1,0) [0.0|31.0] "Enum" Vector__XXX
 SG_ is_TFL_Blinking_533h : 58|1@1+ (1,0) [0.0|1.0] "boolean" Vector__XXX

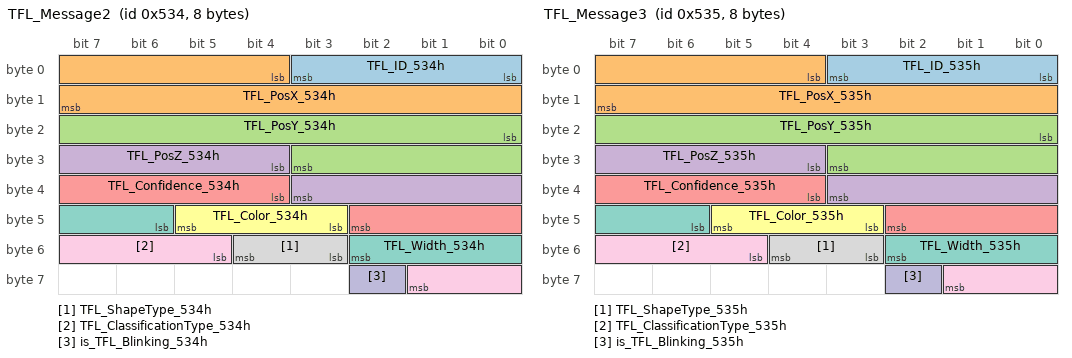
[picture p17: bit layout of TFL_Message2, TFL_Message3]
BO_ 1332 TFL_Message2: 8 Matrix
 SG_ TFL_ID_534h : 0|4@1+ (1,0) [0.0|15.0] "NA" Vector__XXX
 SG_ TFL_PosX_534h : 4|12@1+ (0.0625,0) [0.0|255.938] "m" Vector__XXX
 SG_ TFL_PosY_534h : 16|12@1+ (0.125,-256) [-256.0|255.875] "m" Vector__XXX
 SG_ TFL_PosZ_534h : 28|8@1+ (0.125,0) [0.0|31.875] "m" Vector__XXX
 SG_ TFL_Confidence_534h : 36|7@1+ (1,0) [0.0|100.0] "NA" Vector__XXX
 SG_ TFL_Color_534h : 43|3@1+ (1,0) [0.0|7.0] "Enum" Vector__XXX
 SG_ TFL_Width_534h : 46|5@1+ (0.03125,0) [0.0|0.96875] "m" Vector__XXX
 SG_ TFL_ShapeType_534h : 51|2@1+ (1,0) [0.0|3.0] "Enum" Vector__XXX
 SG_ TFL_ClassificationType_534h : 53|5@1+ (1,0) [0.0|31.0] "Enum" Vector__XXX
 SG_ is_TFL_Blinking_534h : 58|1@1+ (1,0) [0.0|1.0] "boolean" Vector__XXX

BO_ 1333 TFL_Message3: 8 Matrix
 SG_ TFL_ID_535h : 0|4@1+ (1,0) [0.0|15.0] "NA" Vector__XXX
 SG_ TFL_PosX_535h : 4|12@1+ (0.0625,0) [0.0|255.938] "m" Vector__XXX
 SG_ TFL_PosY_535h : 16|12@1+ (0.125,-256) [-256.0|255.875] "m" Vector__XXX
 SG_ TFL_PosZ_535h : 28|8@1+ (0.125,0) [0.0|31.875] "m" Vector__XXX
 SG_ TFL_Confidence_535h : 36|7@1+ (1,0) [0.0|100.0] "NA" Vector__XXX
 SG_ TFL_Color_535h : 43|3@1+ (1,0) [0.0|7.0] "Enum" Vector__XXX
 SG_ TFL_Width_535h : 46|5@1+ (0.03125,0) [0.0|0.96875] "m" Vector__XXX
 SG_ TFL_ShapeType_535h : 51|2@1+ (1,0) [0.0|3.0] "Enum" Vector__XXX
 SG_ TFL_ClassificationType_535h : 53|5@1+ (1,0) [0.0|31.0] "Enum" Vector__XXX
 SG_ is_TFL_Blinking_535h : 58|1@1+ (1,0) [0.0|1.0] "boolean" Vector__XXX

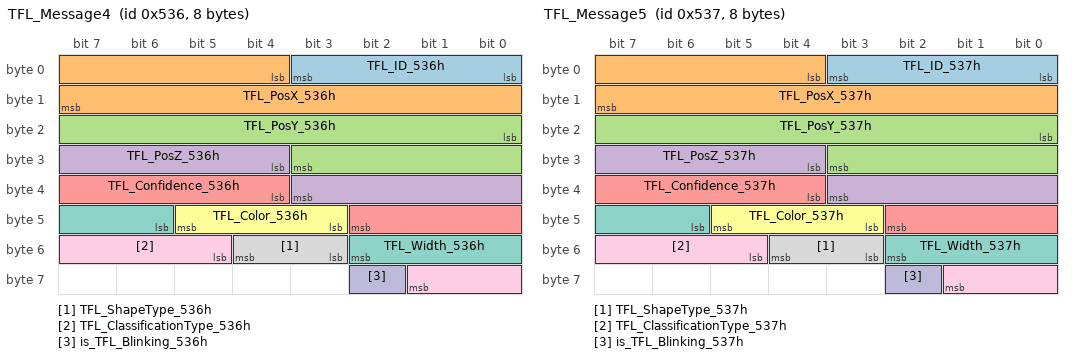
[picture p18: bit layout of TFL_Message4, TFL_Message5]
BO_ 1334 TFL_Message4: 8 Matrix
 SG_ TFL_ID_536h : 0|4@1+ (1,0) [0.0|15.0] "NA" Vector__XXX
 SG_ TFL_PosX_536h : 4|12@1+ (0.0625,0) [0.0|255.938] "m" Vector__XXX
 SG_ TFL_PosY_536h : 16|12@1+ (0.125,-256) [-256.0|255.875] "m" Vector__XXX
 SG_ TFL_PosZ_536h : 28|8@1+ (0.125,0) [0.0|31.875] "m" Vector__XXX
 SG_ TFL_Confidence_536h : 36|7@1+ (1,0) [0.0|100.0] "NA" Vector__XXX
 SG_ TFL_Color_536h : 43|3@1+ (1,0) [0.0|7.0] "Enum" Vector__XXX
 SG_ TFL_Width_536h : 46|5@1+ (0.03125,0) [0.0|0.96875] "m" Vector__XXX
 SG_ TFL_ShapeType_536h : 51|2@1+ (1,0) [0.0|3.0] "Enum" Vector__XXX
 SG_ TFL_ClassificationType_536h : 53|5@1+ (1,0) [0.0|31.0] "Enum" Vector__XXX
 SG_ is_TFL_Blinking_536h : 58|1@1+ (1,0) [0.0|1.0] "boolean" Vector__XXX

BO_ 1335 TFL_Message5: 8 Matrix
 SG_ TFL_ID_537h : 0|4@1+ (1,0) [0.0|15.0] "NA" Vector__XXX
 SG_ TFL_PosX_537h : 4|12@1+ (0.0625,0) [0.0|255.938] "m" Vector__XXX
 SG_ TFL_PosY_537h : 16|12@1+ (0.125,-256) [-256.0|255.875] "m" Vector__XXX
 SG_ TFL_PosZ_537h : 28|8@1+ (0.125,0) [0.0|31.875] "m" Vector__XXX
 SG_ TFL_Confidence_537h : 36|7@1+ (1,0) [0.0|100.0] "NA" Vector__XXX
 SG_ TFL_Color_537h : 43|3@1+ (1,0) [0.0|7.0] "Enum" Vector__XXX
 SG_ TFL_Width_537h : 46|5@1+ (0.03125,0) [0.0|0.96875] "m" Vector__XXX
 SG_ TFL_ShapeType_537h : 51|2@1+ (1,0) [0.0|3.0] "Enum" Vector__XXX
 SG_ TFL_ClassificationType_537h : 53|5@1+ (1,0) [0.0|31.0] "Enum" Vector__XXX
 SG_ is_TFL_Blinking_537h : 58|1@1+ (1,0) [0.0|1.0] "boolean" Vector__XXX

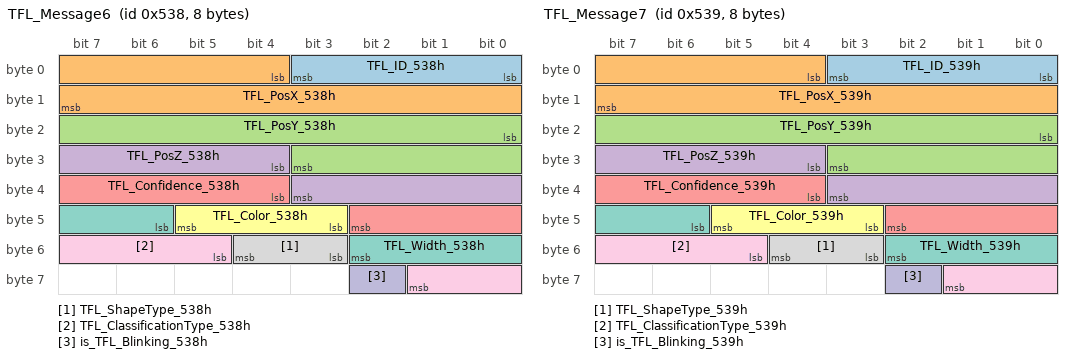
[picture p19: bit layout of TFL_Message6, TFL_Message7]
BO_ 1336 TFL_Message6: 8 Matrix
 SG_ TFL_ID_538h : 0|4@1+ (1,0) [0.0|15.0] "NA" Vector__XXX
 SG_ TFL_PosX_538h : 4|12@1+ (0.0625,0) [0.0|255.938] "m" Vector__XXX
 SG_ TFL_PosY_538h : 16|12@1+ (0.125,-256) [-256.0|255.875] "m" Vector__XXX
 SG_ TFL_PosZ_538h : 28|8@1+ (0.125,0) [0.0|31.875] "m" Vector__XXX
 SG_ TFL_Confidence_538h : 36|7@1+ (1,0) [0.0|100.0] "NA" Vector__XXX
 SG_ TFL_Color_538h : 43|3@1+ (1,0) [0.0|7.0] "Enum" Vector__XXX
 SG_ TFL_Width_538h : 46|5@1+ (0.03125,0) [0.0|0.96875] "m" Vector__XXX
 SG_ TFL_ShapeType_538h : 51|2@1+ (1,0) [0.0|3.0] "Enum" Vector__XXX
 SG_ TFL_ClassificationType_538h : 53|5@1+ (1,0) [0.0|31.0] "Enum" Vector__XXX
 SG_ is_TFL_Blinking_538h : 58|1@1+ (1,0) [0.0|1.0] "boolean" Vector__XXX

BO_ 1337 TFL_Message7: 8 Matrix
 SG_ TFL_ID_539h : 0|4@1+ (1,0) [0.0|15.0] "NA" Vector__XXX
 SG_ TFL_PosX_539h : 4|12@1+ (0.0625,0) [0.0|255.938] "m" Vector__XXX
 SG_ TFL_PosY_539h : 16|12@1+ (0.125,-256) [-256.0|255.875] "m" Vector__XXX
 SG_ TFL_PosZ_539h : 28|8@1+ (0.125,0) [0.0|31.875] "m" Vector__XXX
 SG_ TFL_Confidence_539h : 36|7@1+ (1,0) [0.0|100.0] "NA" Vector__XXX
 SG_ TFL_Color_539h : 43|3@1+ (1,0) [0.0|7.0] "Enum" Vector__XXX
 SG_ TFL_Width_539h : 46|5@1+ (0.03125,0) [0.0|0.96875] "m" Vector__XXX
 SG_ TFL_ShapeType_539h : 51|2@1+ (1,0) [0.0|3.0] "Enum" Vector__XXX
 SG_ TFL_ClassificationType_539h : 53|5@1+ (1,0) [0.0|31.0] "Enum" Vector__XXX
 SG_ is_TFL_Blinking_539h : 58|1@1+ (1,0) [0.0|1.0] "boolean" Vector__XXX

BO_ 1344 TFL_ID01: 8 Matrix
 SG_ TFL_Internal_ID0_540h : 0|32@1+ (1,0) [0.0|4294970000.0] "NA" Vector__XXX
 SG_ TFL_Internal_ID1_540h : 32|32@1+ (1,0) [0.0|4294970000.0] "NA" Vector__XXX

BO_ 1345 TFL_ID23: 8 Matrix
 SG_ TFL_Internal_ID2_541h : 0|32@1+ (1,0) [0.0|4294970000.0] "NA" Vector__XXX
 SG_ TFL_Internal_ID3_541h : 32|32@1+ (1,0) [0.0|4294970000.0] "NA" Vector__XXX

BO_ 1346 TFL_ID45: 8 Matrix
 SG_ TFL_Internal_ID4_542h : 0|32@1+ (1,0) [0.0|4294970000.0] "NA" Vector__XXX
 SG_ TFL_Internal_ID5_542h : 32|32@1+ (1,0) [0.0|4294970000.0] "NA" Vector__XXX

BO_ 1347 TFL_ID67: 8 Matrix
 SG_ TFL_Internal_ID6_543h : 0|32@1+ (1,0) [0.0|4294970000.0] "NA" Vector__XXX
 SG_ TFL_Internal_ID7_543h : 32|32@1+ (1,0) [0.0|4294970000.0] "NA" Vector__XXX

BO_ 1348 TSR_ID01: 8 Matrix
 SG_ TSR_Internal_ID0_544h : 0|32@1+ (1,0) [0.0|4294970000.0] "NA" Vector__XXX
 SG_ TSR_Internal_ID1_544h : 32|32@1+ (1,0) [0.0|4294970000.0] "NA" Vector__XXX

BO_ 1349 TSR_ID23: 8 Matrix
 SG_ TSR_Internal_ID2_545h : 0|32@1+ (1,0) [0.0|4294970000.0] "NA" Vector__XXX
 SG_ TSR_Internal_ID3_545h : 32|32@1+ (1,0) [0.0|4294970000.0] "NA" Vector__XXX

BO_ 1350 TSR_ID45: 8 Matrix
 SG_ TSR_Internal_ID4_546h : 0|32@1+ (1,0) [0.0|4294970000.0] "NA" Vector__XXX
 SG_ TSR_Internal_ID5_546h : 32|32@1+ (1,0) [0.0|4294970000.0] "NA" Vector__XXX

BO_ 1351 TSR_ID67: 8 Matrix
 SG_ TSR_Internal_ID6_547h : 0|32@1+ (1,0) [0.0|4294970000.0] "NA" Vector__XXX
 SG_ TSR_Internal_ID7_547h : 32|32@1+ (1,0) [0.0|4294970000.0] "NA" Vector__XXX

BO_ 1073741824 VECTOR__INDEPENDENT_SIG_MSG: 8 Vector__XXX
 SG_ CutInDistance_40000000h : 0|13@1+ (0.0625,-250) [-250.0|250.0] "m" Vector__XXX
 SG_ ObjCornerPointPoxX_40000000h : 0|13@1+ (0.0625,-250) [-250.0|250.0] "m" Vector__XXX
 SG_ ObstacleAccX_40000000h : 0|10@1+ (0.03,-14.97) [-14.97|14.97] "m/s^2" Vector__XXX
 SG_ ObstacleVelX_40000000h : 0|12@1+ (0.05,-102.4) [-102.4|102.35] "m/sec" Vector__XXX
 SG_ ObstacleVelY_40000000h : 0|12@1+ (0.05,-50) [-50.0|50.0] "m/sec" Vector__XXX

CM_ SG_ 1212 ObstacleLength_4BCh "Length";
CM_ SG_ 1212 ObstacleWidth_4BCh "Width";
CM_ SG_ 1212 ObstacleHeight_4BCh "Height";
CM_ SG_ 1212 CIPVFlag_4BCh "0 - not CIPV 1 - CIPV";
CM_ SG_ 1212 MCPFlag_4BCh "0 - not MCP 1 - MCP";
CM_ SG_ 1212 ObstacleBlinkerInfo_4BCh "Blinker Info";
CM_ SG_ 1212 ObstacleBrakeLights_4BCh "BrakeLightInfo";
CM_ SG_ 1212 ObstacleCenterAngle_4BCh "The Angle Between the orientation of Host Vehicle and the orientation from the front center of Host Vehicle  to the Reference Point of the target";
CM_ SG_ 1212 ObstaclePositionType_4BCh "Were measurements predicted, old, or not valid";
CM_ SG_ 1212 CutInFlag_4BCh "0 - not CIPV 1 - CIPV";
CM_ SG_ 1213 ObstaclePosX_4BDh "The longitudinal distance to the middle of the RL and RR corners";
CM_ SG_ 1213 ObstaclePosY_4BDh "The lateral distance to the middle of the RL and RR corners";
CM_ SG_ 1213 ObstacleVelX_4BDh "The relative longitude velocity of the obstacle.";
CM_ SG_ 1213 ObstacleVelY_4BDh "The relative lateral velocity of the obstacle.";
CM_ SG_ 1213 ObstacleAccX_4BDh "The longitude relative acceleration of the object.";
CM_ SG_ 1214 ObstaclePosXSTD_4BEh "the standard deviation of longitudinal distance to the middle of the RL and RR corners";
CM_ SG_ 1214 ObstaclePosYSTD_4BEh "the standard deviation of lateral distance to the middle of the RL and RR corners";
CM_ SG_ 1214 ObstacleVelXSTD_4BEh "the standard deviation of longitude velocity of the obstacle.";
CM_ SG_ 1214 ObstacleVelYSTD_4BEh "the standard deviation of  lateral velocity of the obstacle.";
CM_ SG_ 1214 ObstacleAccY_4BEh "The lateral relative acceleration of the object.";
CM_ SG_ 1215 ObstacleAngle_4BFh "the heading angle of vehicle";
CM_ SG_ 1215 ObstacleAngleStd_4BFh "the standard deviation of heading angle of vehicle";
CM_ SG_ 1215 ObstacleVelXAbs_4BFh "the absolute longitude velocity of the obstacle.";
CM_ SG_ 1215 ObstacleVelYAbs_4BFh "the absolute lateral velocity of the obstacle.";
CM_ SG_ 1216 ObjCornerPointPoxX_4C0h "The longitudinal distance to the middle of the RL and RR corners";
CM_ SG_ 1216 CutInDistance_4C0h "The lateral distance to the middle of the RL and RR corners";
CM_ SG_ 1216 ObjCornerPointPoxY_4C0h "The longitudinal distance to the middle of the RL and RR corners";
CM_ SG_ 1216 ObstacleCurvature_4C0h "The lateral distance to the middle of the RL and RR corners";
CM_ SG_ 1221 ObstacleID_4C5h "The detected OBJ ID";
CM_ SG_ 1221 ObstacleValid_4C5h "Obstacle Valid info";
CM_ SG_ 1221 ObstacleReplaced_4C5h "Reserved";
CM_ SG_ 1221 ObstacleAge_4C5h "Frame age of obstacle";
CM_ SG_ 1221 ObstacleConfidence_4C5h "Existence probability of Obstacle";
CM_ SG_ 1221 ObstacleMotionCategory_4C5h "The signal is based on our estimation of where the target is now relatively to the lanes, its rate of change, and our estimation of where it is going to be within one second.";
CM_ SG_ 1221 ObstacleMotionStatus_4C5h "The target is moving or stopped";
CM_ SG_ 1221 ObstacleMeasuringStatus_4C5h "Were measurements predicted, old, or not valid";
CM_ SG_ 1221 ObstacleClass_4C5h "Kind of object.";
CM_ SG_ 1221 VehicleSubType_4C5h "Vehicle Sub type";
CM_ SG_ 1221 PedSubType_4C5h "Pedestrian Sub type";
CM_ SG_ 1221 PedPos_4C5h "Pedestrian Position";
CM_ SG_ 1221 PedOrientation_4C5h "Pedestrian Orientation";
CM_ SG_ 1221 ObstacleLaneAssignment_4C5h "Obstacle Lane Assignment £¨Which lane a vehicle belongs to£©";
CM_ SG_ 1222 ObstacleLength_4C6h "Length";
CM_ SG_ 1222 ObstacleWidth_4C6h "Width";
CM_ SG_ 1222 ObstacleHeight_4C6h "Height";
CM_ SG_ 1222 CIPVFlag_4C6h "0 - not CIPV 1 - CIPV";
CM_ SG_ 1222 MCPFlag_4C6h "0 - not MCP 1 - MCP";
CM_ SG_ 1222 ObstacleBlinkerInfo_4C6h "Blinker Info";
CM_ SG_ 1222 ObstacleBrakeLights_4C6h "BrakeLightInfo";
CM_ SG_ 1222 ObstacleCenterAngle_4C6h "The Angle Between the orientation of Host Vehicle and the orientation from the front center of Host Vehicle  to the Reference Point of the target";
CM_ SG_ 1222 ObstaclePositionType_4C6h "Were measurements predicted, old, or not valid";
CM_ SG_ 1222 CutInFlag_4C6h "0 - not CIPV 1 - CIPV";
CM_ SG_ 1223 ObstaclePosX_4C7h "The longitudinal distance to the middle of the RL and RR corners";
CM_ SG_ 1223 ObstaclePosY_4C7h "The lateral distance to the middle of the RL and RR corners";
CM_ SG_ 1223 ObstacleVelX_4C7h "The relative longitude velocity of the obstacle.";
CM_ SG_ 1223 ObstacleVelY_4C7h "The relative lateral velocity of the obstacle.";
CM_ SG_ 1223 ObstacleAccX_4C7h "The longitude relative acceleration of the object.";
CM_ SG_ 1224 ObstaclePosXSTD_4C8h "the standard deviation of longitudinal distance to the middle of the RL and RR corners";
CM_ SG_ 1224 ObstaclePosYSTD_4C8h "the standard deviation of lateral distance to the middle of the RL and RR corners";
CM_ SG_ 1224 ObstacleVelXSTD_4C8h "the standard deviation of longitude velocity of the obstacle.";
CM_ SG_ 1224 ObstacleVelYSTD_4C8h "the standard deviation of  lateral velocity of the obstacle.";
CM_ SG_ 1224 ObstacleAccY_4C8h "The lateral relative acceleration of the object.";
CM_ SG_ 1225 ObstacleAngle_4C9h "the heading angle of vehicle";
CM_ SG_ 1225 ObstacleAngleStd_4C9h "the standard deviation of heading angle of vehicle";
CM_ SG_ 1225 ObstacleVelXAbs_4C9h "the absolute longitude velocity of the obstacle.";
CM_ SG_ 1225 ObstacleVelYAbs_4C9h "the absolute lateral velocity of the obstacle.";
CM_ SG_ 1226 ObjCornerPointPoxX_4CAh "The longitudinal distance to the middle of the RL and RR corners";
CM_ SG_ 1226 CutInDistance_4CAh "The lateral distance to the middle of the RL and RR corners";
CM_ SG_ 1226 ObjCornerPointPoxY_4CAh "The longitudinal distance to the middle of the RL and RR corners";
CM_ SG_ 1226 ObstacleCurvature_4CAh "The lateral distance to the middle of the RL and RR corners";
CM_ SG_ 1231 ObstacleID_4CFh "The detected OBJ ID";
CM_ SG_ 1231 ObstacleValid_4CFh "Obstacle Valid info";
CM_ SG_ 1231 ObstacleReplaced_4CFh "Reserved";
CM_ SG_ 1231 ObstacleAge_4CFh "Frame age of obstacle";
CM_ SG_ 1231 ObstacleConfidence_4CFh "Existence probability of Obstacle";
CM_ SG_ 1231 ObstacleMotionCategory_4CFh "The signal is based on our estimation of where the target is now relatively to the lanes, its rate of change, and our estimation of where it is going to be within one second.";
CM_ SG_ 1231 ObstacleMotionStatus_4CFh "The target is moving or stopped";
CM_ SG_ 1231 ObstacleMeasuringStatus_4CFh "Were measurements predicted, old, or not valid";
CM_ SG_ 1231 ObstacleClass_4CFh "Kind of object.";
CM_ SG_ 1231 VehicleSubType_4CFh "Vehicle Sub type";
CM_ SG_ 1231 PedSubType_4CFh "Pedestrian Sub type";
CM_ SG_ 1231 PedPos_4CFh "Pedestrian Position";
CM_ SG_ 1231 PedOrientation_4CFh "Pedestrian Orientation";
CM_ SG_ 1231 ObstacleLaneAssignment_4CFh "Obstacle Lane Assignment £¨Which lane a vehicle belongs to£©";
CM_ SG_ 1232 ObstacleLength_4D0h "Length";
CM_ SG_ 1232 ObstacleWidth_4D0h "Width";
CM_ SG_ 1232 ObstacleHeight_4D0h "Height";
CM_ SG_ 1232 CIPVFlag_4D0h "0 - not CIPV 1 - CIPV";
CM_ SG_ 1232 MCPFlag_4D0h "0 - not MCP 1 - MCP";
CM_ SG_ 1232 ObstacleBlinkerInfo_4D0h "Blinker Info";
CM_ SG_ 1232 ObstacleBrakeLights_4D0h "BrakeLightInfo";
CM_ SG_ 1232 ObstacleCenterAngle_4D0h "The Angle Between the orientation of Host Vehicle and the orientation from the front center of Host Vehicle  to the Reference Point of the target";
CM_ SG_ 1232 ObstaclePositionType_4D0h "Were measurements predicted, old, or not valid";
CM_ SG_ 1232 CutInFlag_4D0h "0 - not CIPV 1 - CIPV";
CM_ SG_ 1233 ObstaclePosX_4D1h "The longitudinal distance to the middle of the RL and RR corners";
CM_ SG_ 1233 ObstaclePosY_4D1h "The lateral distance to the middle of the RL and RR corners";
CM_ SG_ 1233 ObstacleVelX_4D1h "The relative longitude velocity of the obstacle.";
CM_ SG_ 1233 ObstacleVelY_4D1h "The relative lateral velocity of the obstacle.";
CM_ SG_ 1233 ObstacleAccX_4D1h "The longitude relative acceleration of the object.";
CM_ SG_ 1234 ObstaclePosXSTD_4D2h "the standard deviation of longitudinal distance to the middle of the RL and RR corners";
CM_ SG_ 1234 ObstaclePosYSTD_4D2h "the standard deviation of lateral distance to the middle of the RL and RR corners";
CM_ SG_ 1234 ObstacleVelXSTD_4D2h "the standard deviation of longitude velocity of the obstacle.";
CM_ SG_ 1234 ObstacleVelYSTD_4D2h "the standard deviation of  lateral velocity of the obstacle.";
CM_ SG_ 1234 ObstacleAccY_4D2h "The lateral relative acceleration of the object.";
CM_ SG_ 1235 ObstacleAngle_4D3h "the heading angle of vehicle";
CM_ SG_ 1235 ObstacleAngleStd_4D3h "the standard deviation of heading angle of vehicle";
CM_ SG_ 1235 ObstacleVelXAbs_4D3h "the absolute longitude velocity of the obstacle.";
CM_ SG_ 1235 ObstacleVelYAbs_4D3h "the absolute lateral velocity of the obstacle.";
CM_ SG_ 1236 ObjCornerPointPoxX_4D4h "The longitudinal distance to the middle of the RL and RR corners";
CM_ SG_ 1236 CutInDistance_4D4h "The lateral distance to the middle of the RL and RR corners";
CM_ SG_ 1236 ObjCornerPointPoxY_4D4h "The longitudinal distance to the middle of the RL and RR corners";
CM_ SG_ 1236 ObstacleCurvature_4D4h "The lateral distance to the middle of the RL and RR corners";
CM_ SG_ 1241 Obstacle_Internal_ID1_4D9h "Obstacle_Internal ID mapping to Framework protocol";
CM_ SG_ 1241 Obstacle_Internal_ID2_4D9h "Obstacle_Internal ID mapping to Framework protocol";
CM_ SG_ 1242 Obstacle_Internal_ID3_4DAh "Obstacle_Internal ID mapping to Framework protocol";
CM_ SG_ 1242 Obstacle_Internal_ID4_4DAh "Obstacle_Internal ID mapping to Framework protocol";
CM_ SG_ 1243 Obstacle_Internal_ID5_4DBh "Obstacle_Internal ID mapping to Framework protocol";
CM_ SG_ 1243 Obstacle_Internal_ID6_4DBh "Obstacle_Internal ID mapping to Framework protocol";
CM_ SG_ 1244 Obstacle_Internal_ID7_4DCh "Obstacle_Internal ID mapping to Framework protocol";
CM_ SG_ 1244 Obstacle_Internal_ID8_4DCh "Obstacle_Internal ID mapping to Framework protocol";
CM_ SG_ 1245 Obstacle_Internal_ID9_4DDh "Obstacle_Internal ID mapping to Framework protocol";
CM_ SG_ 1245 Obstacle_Internal_ID10_4DDh "Obstacle_Internal ID mapping to Framework protocol";
CM_ SG_ 1246 Obstacle_Internal_ID11_4DEh "Obstacle_Internal ID mapping to Framework protocol";
CM_ SG_ 1246 Obstacle_Internal_ID12_4DEh "Obstacle_Internal ID mapping to Framework protocol";
CM_ SG_ 1247 Obstacle_Internal_ID13_4DFh "Obstacle_Internal ID mapping to Framework protocol";
CM_ SG_ 1247 Obstacle_Internal_ID14_4DFh "Obstacle_Internal ID mapping to Framework protocol";
CM_ SG_ 1248 Obstacle_Internal_ID15_4E0h "Obstacle_Internal ID mapping to Framework protocol";
CM_ SG_ 1248 Obstacle_Internal_ID16_4E0h "Obstacle_Internal ID mapping to Framework protocol";
CM_ SG_ 1249 Obstacle_Internal_ID17_4E1h "Obstacle_Internal ID mapping to Framework protocol";
CM_ SG_ 1249 Obstacle_Internal_ID18_4E1h "Obstacle_Internal ID mapping to Framework protocol";
CM_ SG_ 1250 Obstacle_Internal_ID19_4E2h "Obstacle_Internal ID mapping to Framework protocol";
CM_ SG_ 1250 Obstacle_Internal_ID20_4E2h "Obstacle_Internal ID mapping to Framework protocol";
CM_ SG_ 1280 RoadType_500h "RoadType from Scene Model";
CM_ SG_ 1280 HostEstimatedWidth_500h "Multi-frame estimation of host lane width to be used for prediction or another driving cue/ scene cue";
CM_ SG_ 1280 CurrentWeather_500h "Weather from Scene Model";
CM_ SG_ 1280 ProtocolMajorVersion_500h "hb_Lanes: Major Version of Protocol";
CM_ SG_ 1280 ProtocolMinorVersion_500h "hb_Lanes: Minor Version of Protocol";
CM_ SG_ 1281 LaneTrackID_501h "Lane Track ID";
CM_ SG_ 1281 LaneConfidence_501h "Confidence of lane mark";
CM_ SG_ 1281 LaneMeasuringStatus_501h "Were measurements predicted, old, or not valid";
CM_ SG_ 1281 LaneTypeClass_501h "Reserved. Double line ENUM of Lane Mark Type Classification";
CM_ SG_ 1281 LaneMarkColor_501h "ENUM lane mark color";
CM_ SG_ 1281 LaneQuality_501h "Lane Quality";
CM_ SG_ 1281 LaneCrossing_501h "Lane Crossing Event
0 = No Cross Event
1 = Crossing";
CM_ SG_ 1281 LaneWidthMarking_501h "Lane line width";
CM_ SG_ 1281 LaneViewRangeStart_501h "near point position";
CM_ SG_ 1281 LaneViewRangeEnd_501h "far point position";
CM_ SG_ 1282 LaneModelC0_502h "Ci is coefficient corresponding to variable with power of 'i'";
CM_ SG_ 1282 LaneModelC1_502h "Ci is coefficient corresponding to variable with power of 'i'";
CM_ SG_ 1282 LaneModelC2_502h "Ci is coefficient corresponding to variable with power of 'i'";
CM_ SG_ 1282 LaneModelC3_502h "Ci is coefficient corresponding to variable with power of 'i'";
CM_ SG_ 1282 LaneTLC_502h "Lane Time to Lane Crossing";
CM_ SG_ 1283 LaneTrackID_503h "Lane Track ID";
CM_ SG_ 1283 LaneConfidence_503h "Confidence of lane mark";
CM_ SG_ 1283 LaneMeasuringStatus_503h "Were measurements predicted, old, or not valid";
CM_ SG_ 1283 LaneTypeClass_503h "Reserved. Double line ENUM of Lane Mark Type Classification";
CM_ SG_ 1283 LaneMarkColor_503h "ENUM lane mark color";
CM_ SG_ 1283 LaneQuality_503h "Lane Quality";
CM_ SG_ 1283 LaneCrossing_503h "Lane Crossing Event
0 = No Cross Event
1 = Crossing";
CM_ SG_ 1283 LaneWidthMarking_503h "Lane line width";
CM_ SG_ 1283 LaneViewRangeStart_503h "near point position";
CM_ SG_ 1283 LaneViewRangeEnd_503h "far point position";
CM_ SG_ 1284 LaneModelC0_504h "Ci is coefficient corresponding to variable with power of 'i'";
CM_ SG_ 1284 LaneModelC1_504h "Ci is coefficient corresponding to variable with power of 'i'";
CM_ SG_ 1284 LaneModelC2_504h "Ci is coefficient corresponding to variable with power of 'i'";
CM_ SG_ 1284 LaneModelC3_504h "Ci is coefficient corresponding to variable with power of 'i'";
CM_ SG_ 1284 LaneTLC_504h "Lane Time to Lane Crossing";
CM_ SG_ 1285 LaneTrackID_505h "Lane Track ID";
CM_ SG_ 1285 LaneConfidence_505h "Confidence of lane mark";
CM_ SG_ 1285 LaneMeasuringStatus_505h "Were measurements predicted, old, or not valid";
CM_ SG_ 1285 LaneTypeClass_505h "Reserved. Double line ENUM of Lane Mark Type Classification";
CM_ SG_ 1285 LaneMarkColor_505h "ENUM lane mark color";
CM_ SG_ 1285 LaneQuality_505h "Lane Quality";
CM_ SG_ 1285 LaneWidthMarking_505h "Lane line width";
CM_ SG_ 1285 LaneViewRangeStart_505h "Lane Start point distance";
CM_ SG_ 1285 LaneViewRangeEnd_505h "Lane End point distance";
CM_ SG_ 1286 LaneTrackID_506h "Lane Track ID";
CM_ SG_ 1286 LaneConfidence_506h "Confidence of lane mark";
CM_ SG_ 1286 LaneMeasuringStatus_506h "Were measurements predicted, old, or not valid";
CM_ SG_ 1286 LaneTypeClass_506h "Reserved. Double line ENUM of Lane Mark Type Classification";
CM_ SG_ 1286 LaneMarkColor_506h "ENUM lane mark color";
CM_ SG_ 1286 LaneQuality_506h "Lane Quality";
CM_ SG_ 1286 LaneWidthMarking_506h "Lane line width";
CM_ SG_ 1286 LaneViewRangeStart_506h "Lane Start point distance";
CM_ SG_ 1286 LaneViewRangeEnd_506h "Lane End point distance";
CM_ SG_ 1287 LaneModelC0_507h "Ci is coefficient corresponding to variable with power of 'i'";
CM_ SG_ 1287 LaneModelC1_507h "Ci is coefficient corresponding to variable with power of 'i'";
CM_ SG_ 1287 LaneModelC2_507h "Ci is coefficient corresponding to variable with power of 'i'";
CM_ SG_ 1287 LaneModelC3_507h "Ci is coefficient corresponding to variable with power of 'i'";
CM_ SG_ 1288 LaneModelC0_508h "Ci is coefficient corresponding to variable with power of 'i'";
CM_ SG_ 1288 LaneModelC1_508h "Ci is coefficient corresponding to variable with power of 'i'";
CM_ SG_ 1288 LaneModelC2_508h "Ci is coefficient corresponding to variable with power of 'i'";
CM_ SG_ 1288 LaneModelC3_508h "Ci is coefficient corresponding to variable with power of 'i'";
CM_ SG_ 1312 TSRObjectsNumber_520h "Number of TSR Objects";
CM_ SG_ 1312 ProtocolMajorVersion_520h "Protocol Major Version, example: V0.3, 0: Major Version";
CM_ SG_ 1312 ProtocolMinorVersion_520h "Protocol Minor Version:  example: V0.3, 3: Minor Version";
CM_ SG_ 1313 TSR_ID_521h "TSR ID";
CM_ SG_ 1313 TSR_Confidence_521h "TSR Confidence";
CM_ SG_ 1313 TSRTrafficSignType_521h "TSR Signs ENUM";
CM_ SG_ 1313 TSRRoadMarkType_521h "Reserved. Not Plan in J2 TSR RoadMark Signs ENUM";
CM_ SG_ 1313 TSR_Relevancy_521h "Reserved. Not Implement.  LANE_ASSIGNMENT_SIGN£ºHost Lane";
CM_ SG_ 1313 TSR_Filter_Type_521h "The reason for filtering the sign.  Reserved. Not Implement.";
CM_ SG_ 1313 TSR_Approved_Flag_521h "Approved is true after  confirm the detection of this sign";
CM_ SG_ 1313 Sign_Position_X_521h "longitudinal distance to sign, repect to to the middle of the RL and RR corners";
CM_ SG_ 1313 Sign_Position_Y_521h "lateral distance to sign, repect to to the middle of the RL and RR corners";
CM_ SG_ 1313 Sign_Position_Z_521h "Sign height in meters";
CM_ SG_ 1315 TSR_ID_523h "TSR ID";
CM_ SG_ 1315 TSR_Confidence_523h "TSR Confidence";
CM_ SG_ 1315 TSRTrafficSignType_523h "TSR Signs ENUM";
CM_ SG_ 1315 TSRRoadMarkType_523h "Reserved. Not Plan in J2 TSR RoadMark Signs ENUM";
CM_ SG_ 1315 TSR_Relevancy_523h "Reserved. Not Implement.  LANE_ASSIGNMENT_SIGN£ºHost Lane";
CM_ SG_ 1315 TSR_Filter_Type_523h "The reason for filtering the sign.  Reserved. Not Implement.";
CM_ SG_ 1315 TSR_Approved_Flag_523h "Approved is true after  confirm the detection of this sign";
CM_ SG_ 1315 Sign_Position_X_523h "longitudinal distance to sign, repect to to the middle of the RL and RR corners";
CM_ SG_ 1315 Sign_Position_Y_523h "lateral distance to sign, repect to to the middle of the RL and RR corners";
CM_ SG_ 1315 Sign_Position_Z_523h "Sign height in meters";
CM_ SG_ 1317 TSR_ID_525h "TSR ID";
CM_ SG_ 1317 TSR_Confidence_525h "TSR Confidence";
CM_ SG_ 1317 TSRTrafficSignType_525h "TSR Signs ENUM";
CM_ SG_ 1317 TSRRoadMarkType_525h "Reserved. Not Plan in J2 TSR RoadMark Signs ENUM";
CM_ SG_ 1317 TSR_Relevancy_525h "Reserved. Not Implement.  LANE_ASSIGNMENT_SIGN£ºHost Lane";
CM_ SG_ 1317 TSR_Filter_Type_525h "The reason for filtering the sign.  Reserved. Not Implement.";
CM_ SG_ 1317 TSR_Approved_Flag_525h "Approved is true after  confirm the detection of this sign";
CM_ SG_ 1317 Sign_Position_X_525h "longitudinal distance to sign, repect to to the middle of the RL and RR corners";
CM_ SG_ 1317 Sign_Position_Y_525h "lateral distance to sign, repect to to the middle of the RL and RR corners";
CM_ SG_ 1317 Sign_Position_Z_525h "Sign height in meters";
CM_ SG_ 1319 TSR_ID_527h "TSR ID";
CM_ SG_ 1319 TSR_Confidence_527h "TSR Confidence";
CM_ SG_ 1319 TSRTrafficSignType_527h "TSR Signs ENUM";
CM_ SG_ 1319 TSRRoadMarkType_527h "Reserved. Not Plan in J2 TSR RoadMark Signs ENUM";
CM_ SG_ 1319 TSR_Relevancy_527h "Reserved. Not Implement.  LANE_ASSIGNMENT_SIGN£ºHost Lane";
CM_ SG_ 1319 TSR_Filter_Type_527h "The reason for filtering the sign.  Reserved. Not Implement.";
CM_ SG_ 1319 TSR_Approved_Flag_527h "Approved is true after  confirm the detection of this sign";
CM_ SG_ 1319 Sign_Position_X_527h "longitudinal distance to sign, repect to to the middle of the RL and RR corners";
CM_ SG_ 1319 Sign_Position_Y_527h "lateral distance to sign, repect to to the middle of the RL and RR corners";
CM_ SG_ 1319 Sign_Position_Z_527h "Sign height in meters";
CM_ SG_ 1321 TSR_ID_529h "TSR ID";
CM_ SG_ 1321 TSR_Confidence_529h "TSR Confidence";
CM_ SG_ 1321 TSRTrafficSignType_529h "TSR Signs ENUM";
CM_ SG_ 1321 TSRRoadMarkType_529h "Reserved. Not Plan in J2 TSR RoadMark Signs ENUM";
CM_ SG_ 1321 TSR_Relevancy_529h "Reserved. Not Implement.  LANE_ASSIGNMENT_SIGN£ºHost Lane";
CM_ SG_ 1321 TSR_Filter_Type_529h "The reason for filtering the sign.  Reserved. Not Implement.";
CM_ SG_ 1321 TSR_Approved_Flag_529h "Approved is true after  confirm the detection of this sign";
CM_ SG_ 1321 Sign_Position_X_529h "longitudinal distance to sign, repect to to the middle of the RL and RR corners";
CM_ SG_ 1321 Sign_Position_Y_529h "lateral distance to sign, repect to to the middle of the RL and RR corners";
CM_ SG_ 1321 Sign_Position_Z_529h "Sign height in meters";
CM_ SG_ 1323 TSR_ID_52Bh "TSR ID";
CM_ SG_ 1323 TSR_Confidence_52Bh "TSR Confidence";
CM_ SG_ 1323 TSRTrafficSignType_52Bh "TSR Signs ENUM";
CM_ SG_ 1323 TSRRoadMarkType_52Bh "Reserved. Not Plan in J2 TSR RoadMark Signs ENUM";
CM_ SG_ 1323 TSR_Relevancy_52Bh "Reserved. Not Implement.  LANE_ASSIGNMENT_SIGN£ºHost Lane";
CM_ SG_ 1323 TSR_Filter_Type_52Bh "The reason for filtering the sign.  Reserved. Not Implement.";
CM_ SG_ 1323 TSR_Approved_Flag_52Bh "Approved is true after  confirm the detection of this sign";
CM_ SG_ 1323 Sign_Position_X_52Bh "longitudinal distance to sign, repect to to the middle of the RL and RR corners";
CM_ SG_ 1323 Sign_Position_Y_52Bh "lateral distance to sign, repect to to the middle of the RL and RR corners";
CM_ SG_ 1323 Sign_Position_Z_52Bh "Sign height in meters";
CM_ SG_ 1325 TSR_ID_52Dh "TSR ID";
CM_ SG_ 1325 TSR_Confidence_52Dh "TSR Confidence";
CM_ SG_ 1325 TSRTrafficSignType_52Dh "TSR Signs ENUM";
CM_ SG_ 1325 TSRRoadMarkType_52Dh "Reserved. Not Plan in J2 TSR RoadMark Signs ENUM";
CM_ SG_ 1325 TSR_Relevancy_52Dh "Reserved. Not Implement.  LANE_ASSIGNMENT_SIGN£ºHost Lane";
CM_ SG_ 1325 TSR_Filter_Type_52Dh "The reason for filtering the sign.  Reserved. Not Implement.";
CM_ SG_ 1325 TSR_Approved_Flag_52Dh "Approved is true after  confirm the detection of this sign";
CM_ SG_ 1325 Sign_Position_X_52Dh "longitudinal distance to sign, repect to to the middle of the RL and RR corners";
CM_ SG_ 1325 Sign_Position_Y_52Dh "lateral distance to sign, repect to to the middle of the RL and RR corners";
CM_ SG_ 1325 Sign_Position_Z_52Dh "Sign height in meters";
CM_ SG_ 1327 TSR_ID_52Fh "TSR ID";
CM_ SG_ 1327 TSR_Confidence_52Fh "TSR Confidence";
CM_ SG_ 1327 TSRTrafficSignType_52Fh "TSR Signs ENUM";
CM_ SG_ 1327 TSRRoadMarkType_52Fh "Reserved. Not Plan in J2 TSR RoadMark Signs ENUM";
CM_ SG_ 1327 TSR_Relevancy_52Fh "Reserved. Not Implement.  LANE_ASSIGNMENT_SIGN£ºHost Lane";
CM_ SG_ 1327 TSR_Filter_Type_52Fh "The reason for filtering the sign.  Reserved. Not Implement.";
CM_ SG_ 1327 TSR_Approved_Flag_52Fh "Approved is true after  confirm the detection of this sign";
CM_ SG_ 1327 Sign_Position_X_52Fh "longitudinal distance to sign, repect to to the middle of the RL and RR corners";
CM_ SG_ 1327 Sign_Position_Y_52Fh "lateral distance to sign, repect to to the middle of the RL and RR corners";
CM_ SG_ 1327 Sign_Position_Z_52Fh "Sign height in meters";
CM_ SG_ 1329 TFLObjectsNumber_531h "Number of TFL Objects";
CM_ SG_ 1329 TFLMainObjectID_531h "Reserved - Not Implemented. The ID that represents the TFL which is the most relevant for the host vehicle";
CM_ SG_ 1329 ProtocolMajorVersion_531h "Protocol Major Version, example: V0.3, 0: Major Version";
CM_ SG_ 1329 ProtocolMinorVersion_531h "Protocol Minor Version:  example: V0.3, 3: Minor Version";
CM_ SG_ 1330 TFL_ID_532h "TFL ID, range 1-8";
CM_ SG_ 1330 TFL_PosX_532h "Longitudinal distance to sign (on the ground ) in meters, repect to to the middle of the RL and RR corners";
CM_ SG_ 1330 TFL_PosY_532h "Lateral distance with respect to camera. Positive values for detections left of the camera.";
CM_ SG_ 1330 TFL_PosZ_532h "Height of TFL with respect to ground";
CM_ SG_ 1330 TFL_Confidence_532h "Traffic light confidence";
CM_ SG_ 1330 TFL_Width_532h "Reserved. Not Plan in J2 default value: 0 - 0m";
CM_ SG_ 1330 TFL_ShapeType_532h "Reserved. Not Plan in J2 default value: 0 - Unknown/Unsupported";
CM_ SG_ 1330 is_TFL_Blinking_532h "Reserved. Not Plan in J2 default value: 0";
CM_ SG_ 1331 TFL_ID_533h "TFL ID, range 1-8";
CM_ SG_ 1331 TFL_PosX_533h "Longitudinal distance to sign (on the ground ) in meters, repect to to the middle of the RL and RR corners";
CM_ SG_ 1331 TFL_PosY_533h "Lateral distance with respect to camera. Positive values for detections left of the camera.";
CM_ SG_ 1331 TFL_PosZ_533h "Height of TFL with respect to ground";
CM_ SG_ 1331 TFL_Confidence_533h "Traffic light confidence";
CM_ SG_ 1331 TFL_Width_533h "Reserved. Not Plan in J2 default value: 0 - 0m";
CM_ SG_ 1331 TFL_ShapeType_533h "Reserved. Not Plan in J2 default value: 0 - Unknown/Unsupported";
CM_ SG_ 1331 is_TFL_Blinking_533h "Reserved. Not Plan in J2 default value: 0";
CM_ SG_ 1332 TFL_ID_534h "TFL ID, range 1-8";
CM_ SG_ 1332 TFL_PosX_534h "Longitudinal distance to sign (on the ground ) in meters, repect to to the middle of the RL and RR corners";
CM_ SG_ 1332 TFL_PosY_534h "Lateral distance with respect to camera. Positive values for detections left of the camera.";
CM_ SG_ 1332 TFL_PosZ_534h "Height of TFL with respect to ground";
CM_ SG_ 1332 TFL_Confidence_534h "Traffic light confidence";
CM_ SG_ 1332 TFL_Width_534h "Reserved. Not Implement. default value: 0 - 0m";
CM_ SG_ 1332 TFL_ShapeType_534h "Reserved. Not Implement. default value: 0 - Unknown/Unsupported";
CM_ SG_ 1332 is_TFL_Blinking_534h "Reserved. Not Implement. default value: 0";
CM_ SG_ 1333 TFL_ID_535h "TFL ID, range 1-8";
CM_ SG_ 1333 TFL_PosX_535h "Longitudinal distance to sign (on the ground ) in meters, repect to to the middle of the RL and RR corners";
CM_ SG_ 1333 TFL_PosY_535h "Lateral distance with respect to camera. Positive values for detections left of the camera.";
CM_ SG_ 1333 TFL_PosZ_535h "Height of TFL with respect to ground";
CM_ SG_ 1333 TFL_Confidence_535h "Traffic light confidence";
CM_ SG_ 1333 TFL_Width_535h "Reserved. Not Plan in J2 default value: 0 - 0m";
CM_ SG_ 1333 TFL_ShapeType_535h "Reserved. Not Plan in J2 default value: 0 - Unknown/Unsupported";
CM_ SG_ 1333 is_TFL_Blinking_535h "Reserved. Not Plan in J2 default value: 0";
CM_ SG_ 1334 TFL_ID_536h "TFL ID, range 1-8";
CM_ SG_ 1334 TFL_PosX_536h "Longitudinal distance to sign (on the ground ) in meters, repect to to the middle of the RL and RR corners";
CM_ SG_ 1334 TFL_PosY_536h "Lateral distance with respect to camera. Positive values for detections left of the camera.";
CM_ SG_ 1334 TFL_PosZ_536h "Height of TFL with respect to ground";
CM_ SG_ 1334 TFL_Confidence_536h "Traffic light confidence";
CM_ SG_ 1334 TFL_Width_536h "Reserved. Not Plan in J2 default value: 0 - 0m";
CM_ SG_ 1334 TFL_ShapeType_536h "Reserved. Not Plan in J2 default value: 0 - Unknown/Unsupported";
CM_ SG_ 1334 is_TFL_Blinking_536h "Reserved. Not Plan in J2 default value: 0";
CM_ SG_ 1335 TFL_ID_537h "TFL ID, range 1-8";
CM_ SG_ 1335 TFL_PosX_537h "Longitudinal distance to sign (on the ground ) in meters, repect to to the middle of the RL and RR corners";
CM_ SG_ 1335 TFL_PosY_537h "Lateral distance with respect to camera. Positive values for detections left of the camera.";
CM_ SG_ 1335 TFL_PosZ_537h "Height of TFL with respect to ground";
CM_ SG_ 1335 TFL_Confidence_537h "Traffic light confidence";
CM_ SG_ 1335 TFL_Width_537h "Reserved. Not Plan in J2 default value: 0 - 0m";
CM_ SG_ 1335 TFL_ShapeType_537h "Reserved. Not Plan in J2 default value: 0 - Unknown/Unsupported";
CM_ SG_ 1335 is_TFL_Blinking_537h "Reserved. Not Plan in J2 default value: 0";
CM_ SG_ 1336 TFL_ID_538h "TFL ID, range 1-8";
CM_ SG_ 1336 TFL_PosX_538h "Longitudinal distance to sign (on the ground ) in meters, repect to to the middle of the RL and RR corners";
CM_ SG_ 1336 TFL_PosY_538h "Lateral distance with respect to camera. Positive values for detections left of the camera.";
CM_ SG_ 1336 TFL_PosZ_538h "Height of TFL with respect to ground";
CM_ SG_ 1336 TFL_Confidence_538h "Traffic light confidence";
CM_ SG_ 1336 TFL_Width_538h "Reserved. Not Plan in J2 default value: 0 - 0m";
CM_ SG_ 1336 TFL_ShapeType_538h "Reserved. Not Plan in J2 default value: 0 - Unknown/Unsupported";
CM_ SG_ 1336 is_TFL_Blinking_538h "Reserved. Not Plan in J2 default value: 0";
CM_ SG_ 1337 TFL_ID_539h "TFL ID, range 1-8";
CM_ SG_ 1337 TFL_PosX_539h "Longitudinal distance to sign (on the ground ) in meters, repect to to the middle of the RL and RR corners";
CM_ SG_ 1337 TFL_PosY_539h "Lateral distance with respect to camera. Positive values for detections left of the camera.";
CM_ SG_ 1337 TFL_PosZ_539h "Height of TFL with respect to ground";
CM_ SG_ 1337 TFL_Confidence_539h "Traffic light confidence";
CM_ SG_ 1337 TFL_Width_539h "Reserved. Not Plan in J2 default value: 0 - 0m";
CM_ SG_ 1337 TFL_ShapeType_539h "Reserved. Not Plan in J2 default value: 0 - Unknown/Unsupported";
CM_ SG_ 1337 is_TFL_Blinking_539h "Reserved. Not Plan in J2 default value: 0";
CM_ SG_ 1344 TFL_Internal_ID0_540h "relevant internal ID inside software";
CM_ SG_ 1344 TFL_Internal_ID1_540h "relevant internal ID inside software";
CM_ SG_ 1345 TFL_Internal_ID2_541h "relevant internal ID inside software";
CM_ SG_ 1345 TFL_Internal_ID3_541h "relevant internal ID inside software";
CM_ SG_ 1346 TFL_Internal_ID4_542h "relevant internal ID inside software";
CM_ SG_ 1346 TFL_Internal_ID5_542h "relevant internal ID inside software";
CM_ SG_ 1347 TFL_Internal_ID6_543h "relevant internal ID inside software";
CM_ SG_ 1347 TFL_Internal_ID7_543h "relevant internal ID inside software";
CM_ SG_ 1348 TSR_Internal_ID0_544h "relevant uint32 internal ID inside software";
CM_ SG_ 1348 TSR_Internal_ID1_544h "relevant uint32 internal ID inside software";
CM_ SG_ 1349 TSR_Internal_ID2_545h "relevant uint32 internal ID inside software";
CM_ SG_ 1349 TSR_Internal_ID3_545h "relevant uint32 internal ID inside software";
CM_ SG_ 1350 TSR_Internal_ID4_546h "relevant uint32 internal ID inside software";
CM_ SG_ 1350 TSR_Internal_ID5_546h "relevant uint32 internal ID inside software";
CM_ SG_ 1351 TSR_Internal_ID6_547h "relevant uint32 internal ID inside software";
CM_ SG_ 1351 TSR_Internal_ID7_547h "relevant uint32 internal ID inside software";
CM_ SG_ 1073741824 CutInDistance_40000000h "The lateral distance to the middle of the RL and RR corners";
CM_ SG_ 1073741824 ObjCornerPointPoxX_40000000h "The longitudinal distance to the middle of the RL and RR corners";
CM_ SG_ 1073741824 ObstacleAccX_40000000h "The longitude relative acceleration of the object.";
CM_ SG_ 1073741824 ObstacleVelX_40000000h "The relative longitude velocity of the obstacle.";
CM_ SG_ 1073741824 ObstacleVelY_40000000h "The relative lateral velocity of the obstacle.";

BA_DEF_ BO_ "GenMsgCycleTime" INT 0 65535;
BA_DEF_ BO_ "VFrameFormat" ENUM  "StandardCAN","ExtendedCAN","reserved","reserved","reserved","reserved","reserved","reserved","reserved","reserved","reserved","reserved","reserved","reserved","StandardCAN_FD","ExtendedCAN_FD";
BA_ "GenMsgCycleTime" BO_ 1212 0;
BA_ "VFrameFormat" BO_ 1212 14;
BA_ "GenMsgCycleTime" BO_ 1213 0;
BA_ "VFrameFormat" BO_ 1213 14;
BA_ "GenMsgCycleTime" BO_ 1214 0;
BA_ "VFrameFormat" BO_ 1214 14;
BA_ "GenMsgCycleTime" BO_ 1215 0;
BA_ "VFrameFormat" BO_ 1215 14;
BA_ "GenMsgCycleTime" BO_ 1216 0;
BA_ "VFrameFormat" BO_ 1216 14;
BA_ "GenMsgCycleTime" BO_ 1221 0;
BA_ "VFrameFormat" BO_ 1221 14;
BA_ "GenMsgCycleTime" BO_ 1222 0;
BA_ "VFrameFormat" BO_ 1222 14;
BA_ "GenMsgCycleTime" BO_ 1223 0;
BA_ "VFrameFormat" BO_ 1223 14;
BA_ "GenMsgCycleTime" BO_ 1224 0;
BA_ "VFrameFormat" BO_ 1224 14;
BA_ "GenMsgCycleTime" BO_ 1225 0;
BA_ "VFrameFormat" BO_ 1225 14;
BA_ "GenMsgCycleTime" BO_ 1226 0;
BA_ "VFrameFormat" BO_ 1226 14;
BA_ "GenMsgCycleTime" BO_ 1231 0;
BA_ "VFrameFormat" BO_ 1231 14;
BA_ "GenMsgCycleTime" BO_ 1232 0;
BA_ "VFrameFormat" BO_ 1232 14;
BA_ "GenMsgCycleTime" BO_ 1233 0;
BA_ "VFrameFormat" BO_ 1233 14;
BA_ "GenMsgCycleTime" BO_ 1234 0;
BA_ "VFrameFormat" BO_ 1234 14;
BA_ "GenMsgCycleTime" BO_ 1235 0;
BA_ "VFrameFormat" BO_ 1235 14;
BA_ "GenMsgCycleTime" BO_ 1236 0;
BA_ "VFrameFormat" BO_ 1236 14;
BA_ "GenMsgCycleTime" BO_ 1241 0;
BA_ "VFrameFormat" BO_ 1241 14;
BA_ "GenMsgCycleTime" BO_ 1242 0;
BA_ "VFrameFormat" BO_ 1242 14;
BA_ "GenMsgCycleTime" BO_ 1243 0;
BA_ "VFrameFormat" BO_ 1243 14;
BA_ "GenMsgCycleTime" BO_ 1244 0;
BA_ "VFrameFormat" BO_ 1244 14;
BA_ "GenMsgCycleTime" BO_ 1245 0;
BA_ "VFrameFormat" BO_ 1245 14;
BA_ "GenMsgCycleTime" BO_ 1246 0;
BA_ "VFrameFormat" BO_ 1246 14;
BA_ "GenMsgCycleTime" BO_ 1247 0;
BA_ "VFrameFormat" BO_ 1247 14;
BA_ "GenMsgCycleTime" BO_ 1248 0;
BA_ "VFrameFormat" BO_ 1248 14;
BA_ "GenMsgCycleTime" BO_ 1249 0;
BA_ "VFrameFormat" BO_ 1249 14;
BA_ "GenMsgCycleTime" BO_ 1250 0;
BA_ "VFrameFormat" BO_ 1250 14;
BA_ "GenMsgCycleTime" BO_ 1280 0;
BA_ "VFrameFormat" BO_ 1280 14;
BA_ "GenMsgCycleTime" BO_ 1281 0;
BA_ "VFrameFormat" BO_ 1281 14;
BA_ "GenMsgCycleTime" BO_ 1282 0;
BA_ "VFrameFormat" BO_ 1282 14;
BA_ "GenMsgCycleTime" BO_ 1283 0;
BA_ "VFrameFormat" BO_ 1283 14;
BA_ "GenMsgCycleTime" BO_ 1284 0;
BA_ "VFrameFormat" BO_ 1284 14;
BA_ "GenMsgCycleTime" BO_ 1285 0;
BA_ "VFrameFormat" BO_ 1285 14;
BA_ "GenMsgCycleTime" BO_ 1286 0;
BA_ "VFrameFormat" BO_ 1286 14;
BA_ "GenMsgCycleTime" BO_ 1287 0;
BA_ "VFrameFormat" BO_ 1287 14;
BA_ "GenMsgCycleTime" BO_ 1288 0;
BA_ "VFrameFormat" BO_ 1288 14;
BA_ "GenMsgCycleTime" BO_ 1312 0;
BA_ "VFrameFormat" BO_ 1312 14;
BA_ "GenMsgCycleTime" BO_ 1313 0;
BA_ "VFrameFormat" BO_ 1313 14;
BA_ "GenMsgCycleTime" BO_ 1315 0;
BA_ "VFrameFormat" BO_ 1315 14;
BA_ "GenMsgCycleTime" BO_ 1317 0;
BA_ "VFrameFormat" BO_ 1317 14;
BA_ "GenMsgCycleTime" BO_ 1319 0;
BA_ "VFrameFormat" BO_ 1319 14;
BA_ "GenMsgCycleTime" BO_ 1321 0;
BA_ "VFrameFormat" BO_ 1321 14;
BA_ "GenMsgCycleTime" BO_ 1323 0;
BA_ "VFrameFormat" BO_ 1323 14;
BA_ "GenMsgCycleTime" BO_ 1325 0;
BA_ "VFrameFormat" BO_ 1325 14;
BA_ "GenMsgCycleTime" BO_ 1327 0;
BA_ "VFrameFormat" BO_ 1327 14;
BA_ "GenMsgCycleTime" BO_ 1329 0;
BA_ "VFrameFormat" BO_ 1329 14;
BA_ "GenMsgCycleTime" BO_ 1330 0;
BA_ "VFrameFormat" BO_ 1330 14;
BA_ "GenMsgCycleTime" BO_ 1331 0;
BA_ "VFrameFormat" BO_ 1331 14;
BA_ "GenMsgCycleTime" BO_ 1332 0;
BA_ "VFrameFormat" BO_ 1332 14;
BA_ "GenMsgCycleTime" BO_ 1333 0;
BA_ "VFrameFormat" BO_ 1333 14;
BA_ "GenMsgCycleTime" BO_ 1334 0;
BA_ "VFrameFormat" BO_ 1334 14;
BA_ "GenMsgCycleTime" BO_ 1335 0;
BA_ "VFrameFormat" BO_ 1335 14;
BA_ "GenMsgCycleTime" BO_ 1336 0;
BA_ "VFrameFormat" BO_ 1336 14;
BA_ "GenMsgCycleTime" BO_ 1337 0;
BA_ "VFrameFormat" BO_ 1337 14;
BA_ "GenMsgCycleTime" BO_ 1344 0;
BA_ "VFrameFormat" BO_ 1344 14;
BA_ "GenMsgCycleTime" BO_ 1345 0;
BA_ "VFrameFormat" BO_ 1345 14;
BA_ "GenMsgCycleTime" BO_ 1346 0;
BA_ "VFrameFormat" BO_ 1346 14;
BA_ "GenMsgCycleTime" BO_ 1347 0;
BA_ "VFrameFormat" BO_ 1347 14;
BA_ "GenMsgCycleTime" BO_ 1348 0;
BA_ "VFrameFormat" BO_ 1348 14;
BA_ "GenMsgCycleTime" BO_ 1349 0;
BA_ "VFrameFormat" BO_ 1349 14;
BA_ "GenMsgCycleTime" BO_ 1350 0;
BA_ "VFrameFormat" BO_ 1350 14;
BA_ "GenMsgCycleTime" BO_ 1351 0;
BA_ "VFrameFormat" BO_ 1351 14;
BA_ "GenMsgCycleTime" BO_ 1073741824 0;
BA_ "VFrameFormat" BO_ 1073741824 14;
VAL_ 1212 CIPVFlag_4BCh 0 "not CIPV" 1 "CIPV";
VAL_ 1212 MCPFlag_4BCh 0 "not MCP" 1 "MCP";
VAL_ 1212 ObstacleBlinkerInfo_4BCh 0 "Unavailable" 1 "Off" 2 "Left" 3 "Right" 4 "Both";
VAL_ 1212 ObstacleBrakeLights_4BCh 0 "OFF" 1 "ON";
VAL_ 1212 ObstaclePositionType_4BCh 0 "Unknown" 1 "RearLeft" 2 "RearCenter" 3 "RearRight" 4 "FrontLeft" 5 "FrontCenter" 6 "FrontRight" 7 "LeftCenter" 8 "RightCenter" 9 "Center";
VAL_ 1212 CutInFlag_4BCh 0 "not Cut In" 1 "Cut In" 2 "Close Cut In";
VAL_ 1221 ObstacleValid_4C5h 0 "invalid Obstacle(default value)" 1 "new valid (detected this frame)" 2 "older valid";
VAL_ 1221 ObstacleReplaced_4C5h 0 "not replaced in this frame" 1 "replaced in this frame";
VAL_ 1221 ObstacleMotionCategory_4C5h 0 "INVALID" 1 "UNDEFINED" 2 "PASSING" 3 "PASSING_IN" 4 "PASSING_OUT" 5 "CLOSE_CUT_IN" 6 "MOVING_IN" 7 "MOVING_OUT" 8 "CROSSING" 9 "LTAP" 10 "RTAP" 11 "MOVING" 12 "PRECEEDING" 13 "ONCOMING";
VAL_ 1221 ObstacleMotionStatus_4C5h 0 "INVALID" 1 "UNKNOWN" 2 "MOVING" 3 "STATIONARY" 4 "STOPPED" 5 "MOVING SLOWLY";
VAL_ 1221 ObstacleMeasuringStatus_4C5h 0 "INVALID" 1 "MEASURED" 2 "PREDICTED";
VAL_ 1221 ObstacleClass_4C5h 0 "INVALID" 1 "VEHICLE" 2 "PEDESTRIAN" 3 "CYCLIST" 4 "GENERAL_OBJECT";
VAL_ 1221 VehicleSubType_4C5h 0 "Unknown" 1 "Bus" 2 "Small_Medium_Car" 3 "Trucks" 4 "Motors(Tri-cycle)" 5 "Special_vehicle" 6 "Tiny_car" 7 "Lorry";
VAL_ 1221 PedSubType_4C5h 0 "Unknown" 1 "Adult" 2 "Child";
VAL_ 1221 PedPos_4C5h 0 "Unknown" 1 "Bended" 2 "Cyclist" 3 "Lier" 4 "Pedestrian" 5 "Sitter";
VAL_ 1221 PedOrientation_4C5h 0 "Unknown" 1 "back" 2 "front" 3 "left" 4 "left_anterior" 5 "left_back" 6 "right" 7 "right_front" 8 "right_back";
VAL_ 1221 ObstacleLaneAssignment_4C5h 0 "UNKNOWN" 1 "LEFT_LEFT" 2 "LEFT" 3 "HOST" 4 "RIGHT" 5 "RIGHT_RIGHT";
VAL_ 1222 CIPVFlag_4C6h 0 "not CIPV" 1 "CIPV";
VAL_ 1222 MCPFlag_4C6h 0 "not MCP" 1 "MCP";
VAL_ 1222 ObstacleBlinkerInfo_4C6h 0 "Unavailable" 1 "Off" 2 "Left" 3 "Right" 4 "Both";
VAL_ 1222 ObstacleBrakeLights_4C6h 0 "OFF" 1 "ON";
VAL_ 1222 ObstaclePositionType_4C6h 0 "Unknown" 1 "RearLeft" 2 "RearCenter" 3 "RearRight" 4 "FrontLeft" 5 "FrontCenter" 6 "FrontRight" 7 "LeftCenter" 8 "RightCenter" 9 "Center";
VAL_ 1222 CutInFlag_4C6h 0 "not Cut In" 1 "Cut In" 2 "Close Cut In";
VAL_ 1231 ObstacleValid_4CFh 0 "invalid Obstacle(default value)" 1 "new valid (detected this frame)" 2 "older valid";
VAL_ 1231 ObstacleReplaced_4CFh 0 "not replaced in this frame" 1 "replaced in this frame";
VAL_ 1231 ObstacleMotionCategory_4CFh 0 "INVALID" 1 "UNDEFINED" 2 "PASSING" 3 "PASSING_IN" 4 "PASSING_OUT" 5 "CLOSE_CUT_IN" 6 "MOVING_IN" 7 "MOVING_OUT" 8 "CROSSING" 9 "LTAP" 10 "RTAP" 11 "MOVING" 12 "PRECEEDING" 13 "ONCOMING";
VAL_ 1231 ObstacleMotionStatus_4CFh 0 "INVALID" 1 "UNKNOWN" 2 "MOVING" 3 "STATIONARY" 4 "STOPPED" 5 "MOVING SLOWLY";
VAL_ 1231 ObstacleMeasuringStatus_4CFh 0 "INVALID" 1 "MEASURED" 2 "PREDICTED";
VAL_ 1231 ObstacleClass_4CFh 0 "INVALID" 1 "VEHICLE" 2 "PEDESTRIAN" 3 "CYCLIST" 4 "GENERAL_OBJECT";
VAL_ 1231 VehicleSubType_4CFh 0 "Unknown" 1 "Bus" 2 "Small_Medium_Car" 3 "Trucks" 4 "Motors(Tri-cycle)" 5 "Special_vehicle" 6 "Tiny_car" 7 "Lorry";
VAL_ 1231 PedSubType_4CFh 0 "Unknown" 1 "Adult" 2 "Child";
VAL_ 1231 PedPos_4CFh 0 "Unknown" 1 "Bended" 2 "Cyclist" 3 "Lier" 4 "Pedestrian" 5 "Sitter";
VAL_ 1231 PedOrientation_4CFh 0 "Unknown" 1 "back" 2 "front" 3 "left" 4 "left_anterior" 5 "left_back" 6 "right" 7 "right_front" 8 "right_back";
VAL_ 1231 ObstacleLaneAssignment_4CFh 0 "UNKNOWN" 1 "LEFT_LEFT" 2 "LEFT" 3 "HOST" 4 "RIGHT" 5 "RIGHT_RIGHT";
VAL_ 1232 CIPVFlag_4D0h 0 "not CIPV" 1 "CIPV";
VAL_ 1232 MCPFlag_4D0h 0 "not MCP" 1 "MCP";
VAL_ 1232 ObstacleBlinkerInfo_4D0h 0 "Unavailable" 1 "Off" 2 "Left" 3 "Right" 4 "Both";
VAL_ 1232 ObstacleBrakeLights_4D0h 0 "OFF" 1 "ON";
VAL_ 1232 ObstaclePositionType_4D0h 0 "Unknown" 1 "RearLeft" 2 "RearCenter" 3 "RearRight" 4 "FrontLeft" 5 "FrontCenter" 6 "FrontRight" 7 "LeftCenter" 8 "RightCenter" 9 "Center";
VAL_ 1232 CutInFlag_4D0h 0 "not Cut In" 1 "Cut In" 2 "Close Cut In";
VAL_ 1280 RoadType_500h 0 "Unknown" 1 "Highway" 2 "Urban" 3 "Rural";
VAL_ 1280 CurrentWeather_500h 0 "Unknown" 1 "Sunny_Cloudy" 2 "Rainy_HeavyRainy" 3 "Snow" 4 "Foggy(Reserved)";
VAL_ 1281 LaneMeasuringStatus_501h 0 "UNKNOWN" 1 "NEW" 2 "MEASURED" 3 "PREDICTED" 4 "NOT_VALID";
VAL_ 1281 LaneTypeClass_501h 0 "Unknown" 1 "Solid" 2 "Road Edge" 3 "Dashed" 4 "Double Lane(Left Dashed, Right Solid)" 5 "Double Lane(Left Solid, Right Dashed)" 6 "Double Lane(Double Dashed)" 7 "Double Lane(Double Solid)" 8 "Barrier" 15 "Invalid";
VAL_ 1281 LaneMarkColor_501h 0 "Unknown" 1 "White" 2 "Yellow_Orange_Red" 3 "Blue_Green";
VAL_ 1281 LaneQuality_501h 0 "Unknown" 1 "Low quality" 2 "High quality" 3 "Very High quality";
VAL_ 1281 LaneCrossing_501h 0 "FALSE" 1 "TRUE";
VAL_ 1283 LaneMeasuringStatus_503h 0 "UNKNOWN" 1 "NEW" 2 "MEASURED" 3 "PREDICTED" 4 "NOT_VALID";
VAL_ 1283 LaneTypeClass_503h 0 "Unknown" 1 "Solid" 2 "Road Edge" 3 "Dashed" 4 "Double Lane(Left Dashed, Right Solid)" 5 "Double Lane(Left Solid, Right Dashed)" 6 "Double Lane(Double Dashed)" 7 "Double Lane(Double Solid)" 8 "Barrier" 15 "Invalid";
VAL_ 1283 LaneMarkColor_503h 0 "Unknown" 1 "White" 2 "Yellow_Orange_Red" 3 "Blue_Green";
VAL_ 1283 LaneQuality_503h 0 "Unknown" 1 "Low quality" 2 "High quality" 3 "Very High quality";
VAL_ 1283 LaneCrossing_503h 0 "FALSE" 1 "TRUE";
VAL_ 1285 LaneMeasuringStatus_505h 0 "UNKNOWN" 1 "NEW" 2 "MEASURED" 3 "PREDICTED" 4 "NOT_VALID";
VAL_ 1285 LaneTypeClass_505h 0 "Unknown" 1 "Solid" 2 "Road Edge" 3 "Dashed" 4 "Double Lane(Left Dashed, Right Solid)" 5 "Double Lane(Left Solid, Right Dashed)" 6 "Double Lane(Double Dashed)" 7 "Double Lane(Double Solid)" 8 "Barrier" 15 "Invalid";
VAL_ 1285 LaneMarkColor_505h 0 "Unknown" 1 "White" 2 "Yellow_Orange_Red" 3 "Blue_Green";
VAL_ 1285 LaneQuality_505h 0 "Unknown" 1 "Low quality" 2 "High quality" 3 "Very High quality";
VAL_ 1286 LaneMeasuringStatus_506h 0 "UNKNOWN" 1 "NEW" 2 "MEASURED" 3 "PREDICTED" 4 "NOT_VALID";
VAL_ 1286 LaneTypeClass_506h 0 "Unknown" 1 "Solid" 2 "Road Edge" 3 "Dashed" 4 "Double Lane(Left Dashed, Right Solid)" 5 "Double Lane(Left Solid, Right Dashed)" 6 "Double Lane(Double Dashed)" 7 "Double Lane(Double Solid)" 8 "Barrier" 15 "Invalid";
VAL_ 1286 LaneMarkColor_506h 0 "Unknown" 1 "White" 2 "Yellow_Orange_Red" 3 "Blue_Green";
VAL_ 1286 LaneQuality_506h 0 "Unknown" 1 "Low quality" 2 "High quality" 3 "Very High quality";
VAL_ 1313 TSRTrafficSignType_521h 0 "C_Other" 1 "C_Unknown" 2 "Construction" 3 "FP_Accessory_Arrow" 4 "FP_Building" 5 "FP_Circular_Marker" 6 "FP_Head" 7 "FP_Light_Arrow" 8 "FP_Light_Circle" 9 "FP_Light_Shell" 10 "FP_Mirror" 11 "FP_Other" 12 "FP_Polygon_Marker" 13 "FP_Route_Number" 14 "FP_Twig" 15 "FP_Unknown" 16 "FP_Vehicle_Wheel" 17 "GSGW_Misc" 18 "GSGW_Other" 19 "GSGW_Unknown" 20 "GSWB_Misc" 21 "GSWB_Other" 22 "GSWB_Unknown" 23 "G_GuideSign_GreenWhite" 24 "G_GuideSign_WhiteBlack" 25 "GuideSign_MultiMisc" 26 "IR_AccidentPronePoint" 27 "IR_Accommodation" 28 "IR_AdministrativeBoundary" 29 "IR_Airport" 30 "IR_Area" 31 "IR_AvoidLine" 32 "IR_BifurcationMark" 33 "IR_BigCarRight" 34 "IR_Blocked" 35 "IR_BusStation" 36 "IR_CarRepair" 37 "IR_CarWash" 38 "IR_CateringServices" 39 "IR_CombinationAuxiliary" 40 "IR_ContinuousDownhill" 41 "IR_CountryRoadNumMark" 42 "IR_CrossIntersection" 43 "IR_CrossingMarking" 44 "IR_DisabledSpecial" 45 "IR_DistanceArea" 46 "IR_Drink" 47 "IR_DrivingDirection" 48 "IR_ETCLanes" 49 "IR_ElectricalETC" 50 "IR_EmergencyShelter" 51 "IR_FamousPlaceName" 52 "IR_Ferry" 53 "IR_FerryPier" 54 "IR_FirstAidStation" 55 "IR_Foggy" 56 "IR_FootBridge" 57 "IR_GasStation" 58 "IR_HighwayCarDistanceConfirmation" 59 "IR_HighwayClimbingLine" 60 "IR_HighwayDirection" 61 "IR_HighwayETCLanes" 62 "IR_HighwayETCTollStationsNotice" 63 "IR_HighwayEmergencyParkingBelt" 64 "IR_HighwayEmergencyPhone" 65 "IR_HighwayEnd" 66 "IR_HighwayEndNotice" 67 "IR_HighwayEntrance" 68 "IR_HighwayEntranceNotice" 69 "IR_HighwayExit" 70 "IR_HighwayExitNotice" 71 "IR_HighwayGasStation" 72 "IR_HighwayHundredCard" 73 "IR_HighwayLocationDirection" 74 "IR_HighwayLocationDistance" 75 "IR_HighwayMileageCard" 76 "IR_HighwayName" 77 "IR_HighwayNextExitNotice" 78 "IR_HighwayOverloadCheck" 79 "IR_HighwayParkinAreaNotice" 80 "IR_HighwayParkingLotNotice" 81 "IR_HighwayRescueCall" 82 "IR_HighwayRoadTrafficInformation" 83 "IR_HighwayServiceNotice" 84 "IR_HighwaySlowDown" 85 "IR_HighwayStart" 86 "IR_HighwayTicket" 87 "IR_HighwayTollStationsNotice" 88 "IR_Interchange" 89 "IR_IntersectionNotice" 90 "IR_LanesDecrease" 91 "IR_LanesIncrease" 92 "IR_Linearguide" 93 "IR_LocationDistance" 94 "IR_LongDistanceBusStation" 95 "IR_MilePost" 96 "IR_MobileConstruction" 97 "IR_Nameplate" 98 "IR_Parking" 99 "IR_ParkingLot" 100 "IR_PassingTime" 101 "IR_PedestrianTunnel" 102 "IR_PedestrianUnderpass" 103 "IR_PlaceName" 104 "IR_Police" 105 "IR_Port" 106 "IR_ProtectAnimals" 107 "IR_Quarantine" 108 "IR_RailwayStation" 109 "IR_Ramp" 110 "IR_RampArrow" 111 "IR_RestArea" 112 "IR_RoadManageBoundary" 113 "IR_RoadStop" 114 "IR_SlowRoad" 115 "IR_Snack" 116 "IR_SoftFoundation" 117 "IR_SteepSlope" 118 "IR_StreetName" 119 "IR_SubwayStation" 120 "IR_Taxi" 121 "IR_Tcorssing" 122 "IR_TouristAreaDirectionDistance" 123 "IR_TrafficSupervisory" 124 "IR_TransferCenter" 125 "IR_TransverseWind" 126 "IR_TravelSymbols" 127 "IR_Tunnel" 128 "IR_TunnelNextExitNotice" 129 "IR_VehicleType" 130 "IR_ViewingPoint" 131 "IR_WarningReason" 132 "IR_WeightCharge" 133 "IR_Ycorssing" 134 "IR_Zones" 135 "IR_ZonesII" 136 "I_AllowUturn" 137 "I_Circle" 138 "I_FastBusLane" 139 "I_Forward" 140 "I_ForwardLane" 141 "I_ForwardLeft" 142 "I_ForwardLeftLane" 143 "I_ForwardLeftStereo" 144 "I_ForwardRight" 145 "I_ForwardRightLane" 146 "I_ForwardRightStereo" 147 "I_Honk" 148 "I_Left" 149 "I_LeftBusLane" 150 "I_LeftLine" 151 "I_LeftRight" 152 "I_LeftTurn" 153 "I_LeftTurnLane" 154 "I_MinSpeedLim100" 155 "I_MinSpeedLim110" 156 "I_MinSpeedLim40" 157 "I_MinSpeedLim50" 158 "I_MinSpeedLim60" 159 "I_MinSpeedLim70" 160 "I_MinSpeedLim80" 161 "I_MinSpeedLim90" 162 "I_Motors" 163 "I_MotorsLane" 164 "I_MultiOccupantMotorsLane" 165 "I_NonMotors" 166 "I_NonMotorsLane" 167 "I_Other_circle" 168 "I_Other_rectangle" 169 "I_ParkingSpace" 170 "I_Passingfirst" 171 "I_PedestrianCross" 172 "I_PriorityIntereesction" 173 "I_Right" 174 "I_RightLine" 175 "I_RightTurn" 176 "I_RightTurnLane" 177 "I_SplitDriveLine" 178 "I_StraightLine" 179 "I_UTurnAndLeftLane" 180 "I_UTurnLane" 181 "I_Unknown_circle" 182 "I_Unknown_rectangle" 183 "I_Uturn" 184 "I_Walk" 185 "MSL_Other" 186 "MSL_Unknown" 187 "MinSpeedLim100" 188 "MinSpeedLim110" 189 "MinSpeedLim50" 190 "MinSpeedLim60" 191 "MinSpeedLim70" 192 "MinSpeedLim80" 193 "MinSpeedLim90" 194 "NoPassingRev" 195 "O_Other" 196 "Other" 197 "Other_Construction_Sign" 198 "Other_Detfp" 199 "Other_Exit" 200 "Other_GuideSign_BlueWhite" 201 "Other_GuideSign_GreenWhite" 202 "Other_GuideSign_WhiteBlack" 203 "Other_Indications" 204 "Other_LightArrow" 205 "Other_Min_Speed" 206 "Other_Mirror" 207 "Other_NoParking" 208 "Other_Prohibit" 209 "Other_RedCircleLight" 210 "Other_RouteID_RedWhite" 211 "Other_RouteID_YellowBlack" 212 "Other_TravelSign_BrownWhite" 213 "Other_Warning" 214 "PR_Other" 215 "PR_Unknown" 216 "PSL_Other" 217 "PSL_Unknown" 218 "P_Custom" 219 "P_GiveWay" 220 "P_HeightLim" 221 "P_MultiVehicle" 222 "P_NoAnimalVehicle" 223 "P_NoBikeDownSlope" 224 "P_NoBikeUpSlope" 225 "P_NoBus" 226 "P_NoCar" 227 "P_NoCargoTricycle" 228 "P_NoDangerous" 229 "P_NoEntry" 230 "P_NoForward" 231 "P_NoForwardLeft" 232 "P_NoForwardRight" 233 "P_NoHorning" 234 "P_NoHuman" 235 "P_NoHumanCargoTriangle" 236 "P_NoHumanPassengerTriangle" 237 "P_NoHumanVehicle" 238 "P_NoLeftRightTurn" 239 "P_NoLeftTurn" 240 "P_NoLongParking" 241 "P_NoLongParkingRev" 242 "P_NoMinibus" 243 "P_NoMotoTricycle" 244 "P_NoMotor" 245 "P_NoMotorcycle" 246 "P_NoNonMotor" 247 "P_NoParking" 248 "P_NoParkingRev" 249 "P_NoPassing" 250 "P_NoPassingRev" 251 "P_NoReturn" 252 "P_NoRightTurn" 253 "P_NoSpecificLeftTurn" 254 "P_NoSpecificRightTurn" 255 "P_NoTractor" 256 "P_NoTrailer" 257 "P_NoTricycle" 258 "P_NoTruck" 259 "P_Noway" 260 "P_Other1" 261 "P_Other_SpeedLimele" 262 "P_ParkingCheck" 263 "P_SlowFor" 264 "P_SpeedLim10" 265 "P_SpeedLim100" 266 "P_SpeedLim100ele" 267 "P_SpeedLim105" 268 "P_SpeedLim110" 269 "P_SpeedLim110ele" 270 "P_SpeedLim115" 271 "P_SpeedLim120" 272 "P_SpeedLim120ele" 273 "P_SpeedLim15" 274 "P_SpeedLim20" 275 "P_SpeedLim20ele" 276 "P_SpeedLim25" 277 "P_SpeedLim30" 278 "P_SpeedLim30ele" 279 "P_SpeedLim35" 280 "P_SpeedLim40" 281 "P_SpeedLim40ele" 282 "P_SpeedLim45" 283 "P_SpeedLim5" 284 "P_SpeedLim50" 285 "P_SpeedLim50ele" 286 "P_SpeedLim55" 287 "P_SpeedLim60" 288 "P_SpeedLim60ele" 289 "P_SpeedLim65" 290 "P_SpeedLim70" 291 "P_SpeedLim70ele" 292 "P_SpeedLim75" 293 "P_SpeedLim80" 294 "P_SpeedLim80ele" 295 "P_SpeedLim85" 296 "P_SpeedLim90" 297 "P_SpeedLim90ele" 298 "P_SpeedLim95" 299 "P_SpeedLimRev" 300 "P_SpeedLimRev10" 301 "P_SpeedLimRev100" 302 "P_SpeedLimRev105" 303 "P_SpeedLimRev110" 304 "P_SpeedLimRev115" 305 "P_SpeedLimRev120" 306 "P_SpeedLimRev15" 307 "P_SpeedLimRev20" 308 "P_SpeedLimRev25" 309 "P_SpeedLimRev30" 310 "P_SpeedLimRev35" 311 "P_SpeedLimRev40" 312 "P_SpeedLimRev45" 313 "P_SpeedLimRev5" 314 "P_SpeedLimRev50" 315 "P_SpeedLimRev55" 316 "P_SpeedLimRev60" 317 "P_SpeedLimRev65" 318 "P_SpeedLimRev70" 319 "P_SpeedLimRev75" 320 "P_SpeedLimRev80" 321 "P_SpeedLimRev85" 322 "P_SpeedLimRev90" 323 "P_SpeedLimRev95" 324 "P_StopFor" 325 "P_Unknow_SpeedLimele" 326 "P_Unknown1" 327 "P_VehicleOther" 328 "P_WeightLim" 329 "P_WeightLimWheel" 330 "P_WidthLim" 331 "RSBW_Misc" 332 "RSBW_Other" 333 "RSBW_Unknown" 334 "R_CircularIntersection" 335 "R_RoadSign_BlueWhite" 336 "RouteID_HighwayMark" 337 "RouteID_Other" 338 "RouteID_RedWhite" 339 "RouteID_TownRoadMark" 340 "RouteID_Unknown" 341 "RouteID_YellowBlack" 342 "SpeedLim10" 343 "SpeedLim100" 344 "SpeedLim100_electric" 345 "SpeedLim110" 346 "SpeedLim110_electric" 347 "SpeedLim120" 348 "SpeedLim120_electric" 349 "SpeedLim15" 350 "SpeedLim20" 351 "SpeedLim25" 352 "SpeedLim30" 353 "SpeedLim30_electric" 354 "SpeedLim35" 355 "SpeedLim40" 356 "SpeedLim40_electric" 357 "SpeedLim5" 358 "SpeedLim50" 359 "SpeedLim50_electric" 360 "SpeedLim55" 361 "SpeedLim5_electric" 362 "SpeedLim60" 363 "SpeedLim60_electric" 364 "SpeedLim65" 365 "SpeedLim70" 366 "SpeedLim70_electric" 367 "SpeedLim80" 368 "SpeedLim80_electric" 369 "SpeedLim90" 370 "SpeedLim90_electric" 371 "SpeedLimRev" 372 "TSBW_Other" 373 "TSBW_Unknown" 374 "T_TravelSign_BrownWhite" 375 "U_Unknown" 376 "W_AccidentProne" 377 "W_Animal" 378 "W_BadWeather" 379 "W_Bump" 380 "W_Bumpy" 381 "W_Children" 382 "W_Circle" 383 "W_ContinuousDown" 384 "W_ContinuousTurn" 385 "W_Cross" 386 "W_CrossIntersection" 387 "W_CrossLaneRail" 388 "W_Cycle" 389 "W_DamLeft" 390 "W_DamRight" 391 "W_Danger" 392 "W_DetourAround" 393 "W_DetourLeft" 394 "W_DetourRight" 395 "W_Disabled" 396 "W_Domestic" 397 "W_Down" 398 "W_EmergencyLane" 399 "W_Ferry" 400 "W_Fog" 401 "W_Ford" 402 "W_GuardedRailway" 403 "W_HumpBridge" 404 "W_Ice" 405 "W_KeepDistance" 406 "W_LRNarrow" 407 "W_LRTurn" 408 "W_LeftFalling" 409 "W_LeftNarrow" 410 "W_LeftTurn" 411 "W_LowLying" 412 "W_MergeLeft" 413 "W_MergeRight" 414 "W_MountLeft" 415 "W_MountRight" 416 "W_NarrowBridge" 417 "W_Other" 418 "W_Pedestrian" 419 "W_RLTurn" 420 "W_Railway" 421 "W_Rain" 422 "W_RightFalling" 423 "W_RightNarrow" 424 "W_RightTurn" 425 "W_SideWind" 426 "W_Side_Wind" 427 "W_Slash" 428 "W_Slip" 429 "W_Slow" 430 "W_SlowDown" 431 "W_SplitLeft" 432 "W_SplitRight" 433 "W_TIntersection" 434 "W_TShap" 435 "W_TShapLeft" 436 "W_TShapRight" 437 "W_Tidal" 438 "W_TrafficLight" 439 "W_Tripod" 440 "W_Tshape" 441 "W_Tshaps" 442 "W_Tunnel" 443 "W_TunnelHeadlight" 444 "W_TwoWay" 445 "W_Unknown" 446 "W_Up" 447 "W_VehicleQueue" 448 "W_Village" 449 "W_Working" 450 "W_YBLeft" 451 "W_YBRight" 452 "W_YB_Left" 453 "W_YB_Right" 454 "W_YLeft" 455 "W_YRight" 456 "W_Y_Left" 457 "W_Y_Right" 458 "sign_back" 459 "Other_IndicationsCircle" 460 "Other_IndicationsRectangle" 461 "Other_Circular_Marker" 462 "False_Positive" 463 "FP_Light_Time" 464 "RouteSign_Misc" 465 "Multi_Misc";
VAL_ 1313 TSR_Relevancy_521h 0 "Undefined" 1 "IN_HOSTLANE_SIGN" 2 "NOT_IN_HOSTLANE" 3 "HIGHWAY_EXIT_SIGN (Reserved)" 4 "SIGN_ON_TURN (Reserved)" 5 "FAR_IRRELEVANT_SIGN (Reserved)";
VAL_ 1313 TSR_Filter_Type_521h 0 "Not filtered" 1 "Irrelevant to the host driver" 2 "On vehicle/truck" 3 "Embedded(Reserved)" 4 "RESERVED" 5 "RESERVED" 6 "RESERVED" 7 "RESERVED";
VAL_ 1313 TSR_Approved_Flag_521h 0 "Not Approved" 1 "Approved";
VAL_ 1315 TSRTrafficSignType_523h 0 "C_Other" 1 "C_Unknown" 2 "Construction" 3 "FP_Accessory_Arrow" 4 "FP_Building" 5 "FP_Circular_Marker" 6 "FP_Head" 7 "FP_Light_Arrow" 8 "FP_Light_Circle" 9 "FP_Light_Shell" 10 "FP_Mirror" 11 "FP_Other" 12 "FP_Polygon_Marker" 13 "FP_Route_Number" 14 "FP_Twig" 15 "FP_Unknown" 16 "FP_Vehicle_Wheel" 17 "GSGW_Misc" 18 "GSGW_Other" 19 "GSGW_Unknown" 20 "GSWB_Misc" 21 "GSWB_Other" 22 "GSWB_Unknown" 23 "G_GuideSign_GreenWhite" 24 "G_GuideSign_WhiteBlack" 25 "GuideSign_MultiMisc" 26 "IR_AccidentPronePoint" 27 "IR_Accommodation" 28 "IR_AdministrativeBoundary" 29 "IR_Airport" 30 "IR_Area" 31 "IR_AvoidLine" 32 "IR_BifurcationMark" 33 "IR_BigCarRight" 34 "IR_Blocked" 35 "IR_BusStation" 36 "IR_CarRepair" 37 "IR_CarWash" 38 "IR_CateringServices" 39 "IR_CombinationAuxiliary" 40 "IR_ContinuousDownhill" 41 "IR_CountryRoadNumMark" 42 "IR_CrossIntersection" 43 "IR_CrossingMarking" 44 "IR_DisabledSpecial" 45 "IR_DistanceArea" 46 "IR_Drink" 47 "IR_DrivingDirection" 48 "IR_ETCLanes" 49 "IR_ElectricalETC" 50 "IR_EmergencyShelter" 51 "IR_FamousPlaceName" 52 "IR_Ferry" 53 "IR_FerryPier" 54 "IR_FirstAidStation" 55 "IR_Foggy" 56 "IR_FootBridge" 57 "IR_GasStation" 58 "IR_HighwayCarDistanceConfirmation" 59 "IR_HighwayClimbingLine" 60 "IR_HighwayDirection" 61 "IR_HighwayETCLanes" 62 "IR_HighwayETCTollStationsNotice" 63 "IR_HighwayEmergencyParkingBelt" 64 "IR_HighwayEmergencyPhone" 65 "IR_HighwayEnd" 66 "IR_HighwayEndNotice" 67 "IR_HighwayEntrance" 68 "IR_HighwayEntranceNotice" 69 "IR_HighwayExit" 70 "IR_HighwayExitNotice" 71 "IR_HighwayGasStation" 72 "IR_HighwayHundredCard" 73 "IR_HighwayLocationDirection" 74 "IR_HighwayLocationDistance" 75 "IR_HighwayMileageCard" 76 "IR_HighwayName" 77 "IR_HighwayNextExitNotice" 78 "IR_HighwayOverloadCheck" 79 "IR_HighwayParkinAreaNotice" 80 "IR_HighwayParkingLotNotice" 81 "IR_HighwayRescueCall" 82 "IR_HighwayRoadTrafficInformation" 83 "IR_HighwayServiceNotice" 84 "IR_HighwaySlowDown" 85 "IR_HighwayStart" 86 "IR_HighwayTicket" 87 "IR_HighwayTollStationsNotice" 88 "IR_Interchange" 89 "IR_IntersectionNotice" 90 "IR_LanesDecrease" 91 "IR_LanesIncrease" 92 "IR_Linearguide" 93 "IR_LocationDistance" 94 "IR_LongDistanceBusStation" 95 "IR_MilePost" 96 "IR_MobileConstruction" 97 "IR_Nameplate" 98 "IR_Parking" 99 "IR_ParkingLot" 100 "IR_PassingTime" 101 "IR_PedestrianTunnel" 102 "IR_PedestrianUnderpass" 103 "IR_PlaceName" 104 "IR_Police" 105 "IR_Port" 106 "IR_ProtectAnimals" 107 "IR_Quarantine" 108 "IR_RailwayStation" 109 "IR_Ramp" 110 "IR_RampArrow" 111 "IR_RestArea" 112 "IR_RoadManageBoundary" 113 "IR_RoadStop" 114 "IR_SlowRoad" 115 "IR_Snack" 116 "IR_SoftFoundation" 117 "IR_SteepSlope" 118 "IR_StreetName" 119 "IR_SubwayStation" 120 "IR_Taxi" 121 "IR_Tcorssing" 122 "IR_TouristAreaDirectionDistance" 123 "IR_TrafficSupervisory" 124 "IR_TransferCenter" 125 "IR_TransverseWind" 126 "IR_TravelSymbols" 127 "IR_Tunnel" 128 "IR_TunnelNextExitNotice" 129 "IR_VehicleType" 130 "IR_ViewingPoint" 131 "IR_WarningReason" 132 "IR_WeightCharge" 133 "IR_Ycorssing" 134 "IR_Zones" 135 "IR_ZonesII" 136 "I_AllowUturn" 137 "I_Circle" 138 "I_FastBusLane" 139 "I_Forward" 140 "I_ForwardLane" 141 "I_ForwardLeft" 142 "I_ForwardLeftLane" 143 "I_ForwardLeftStereo" 144 "I_ForwardRight" 145 "I_ForwardRightLane" 146 "I_ForwardRightStereo" 147 "I_Honk" 148 "I_Left" 149 "I_LeftBusLane" 150 "I_LeftLine" 151 "I_LeftRight" 152 "I_LeftTurn" 153 "I_LeftTurnLane" 154 "I_MinSpeedLim100" 155 "I_MinSpeedLim110" 156 "I_MinSpeedLim40" 157 "I_MinSpeedLim50" 158 "I_MinSpeedLim60" 159 "I_MinSpeedLim70" 160 "I_MinSpeedLim80" 161 "I_MinSpeedLim90" 162 "I_Motors" 163 "I_MotorsLane" 164 "I_MultiOccupantMotorsLane" 165 "I_NonMotors" 166 "I_NonMotorsLane" 167 "I_Other_circle" 168 "I_Other_rectangle" 169 "I_ParkingSpace" 170 "I_Passingfirst" 171 "I_PedestrianCross" 172 "I_PriorityIntereesction" 173 "I_Right" 174 "I_RightLine" 175 "I_RightTurn" 176 "I_RightTurnLane" 177 "I_SplitDriveLine" 178 "I_StraightLine" 179 "I_UTurnAndLeftLane" 180 "I_UTurnLane" 181 "I_Unknown_circle" 182 "I_Unknown_rectangle" 183 "I_Uturn" 184 "I_Walk" 185 "MSL_Other" 186 "MSL_Unknown" 187 "MinSpeedLim100" 188 "MinSpeedLim110" 189 "MinSpeedLim50" 190 "MinSpeedLim60" 191 "MinSpeedLim70" 192 "MinSpeedLim80" 193 "MinSpeedLim90" 194 "NoPassingRev" 195 "O_Other" 196 "Other" 197 "Other_Construction_Sign" 198 "Other_Detfp" 199 "Other_Exit" 200 "Other_GuideSign_BlueWhite" 201 "Other_GuideSign_GreenWhite" 202 "Other_GuideSign_WhiteBlack" 203 "Other_Indications" 204 "Other_LightArrow" 205 "Other_Min_Speed" 206 "Other_Mirror" 207 "Other_NoParking" 208 "Other_Prohibit" 209 "Other_RedCircleLight" 210 "Other_RouteID_RedWhite" 211 "Other_RouteID_YellowBlack" 212 "Other_TravelSign_BrownWhite" 213 "Other_Warning" 214 "PR_Other" 215 "PR_Unknown" 216 "PSL_Other" 217 "PSL_Unknown" 218 "P_Custom" 219 "P_GiveWay" 220 "P_HeightLim" 221 "P_MultiVehicle" 222 "P_NoAnimalVehicle" 223 "P_NoBikeDownSlope" 224 "P_NoBikeUpSlope" 225 "P_NoBus" 226 "P_NoCar" 227 "P_NoCargoTricycle" 228 "P_NoDangerous" 229 "P_NoEntry" 230 "P_NoForward" 231 "P_NoForwardLeft" 232 "P_NoForwardRight" 233 "P_NoHorning" 234 "P_NoHuman" 235 "P_NoHumanCargoTriangle" 236 "P_NoHumanPassengerTriangle" 237 "P_NoHumanVehicle" 238 "P_NoLeftRightTurn" 239 "P_NoLeftTurn" 240 "P_NoLongParking" 241 "P_NoLongParkingRev" 242 "P_NoMinibus" 243 "P_NoMotoTricycle" 244 "P_NoMotor" 245 "P_NoMotorcycle" 246 "P_NoNonMotor" 247 "P_NoParking" 248 "P_NoParkingRev" 249 "P_NoPassing" 250 "P_NoPassingRev" 251 "P_NoReturn" 252 "P_NoRightTurn" 253 "P_NoSpecificLeftTurn" 254 "P_NoSpecificRightTurn" 255 "P_NoTractor" 256 "P_NoTrailer" 257 "P_NoTricycle" 258 "P_NoTruck" 259 "P_Noway" 260 "P_Other1" 261 "P_Other_SpeedLimele" 262 "P_ParkingCheck" 263 "P_SlowFor" 264 "P_SpeedLim10" 265 "P_SpeedLim100" 266 "P_SpeedLim100ele" 267 "P_SpeedLim105" 268 "P_SpeedLim110" 269 "P_SpeedLim110ele" 270 "P_SpeedLim115" 271 "P_SpeedLim120" 272 "P_SpeedLim120ele" 273 "P_SpeedLim15" 274 "P_SpeedLim20" 275 "P_SpeedLim20ele" 276 "P_SpeedLim25" 277 "P_SpeedLim30" 278 "P_SpeedLim30ele" 279 "P_SpeedLim35" 280 "P_SpeedLim40" 281 "P_SpeedLim40ele" 282 "P_SpeedLim45" 283 "P_SpeedLim5" 284 "P_SpeedLim50" 285 "P_SpeedLim50ele" 286 "P_SpeedLim55" 287 "P_SpeedLim60" 288 "P_SpeedLim60ele" 289 "P_SpeedLim65" 290 "P_SpeedLim70" 291 "P_SpeedLim70ele" 292 "P_SpeedLim75" 293 "P_SpeedLim80" 294 "P_SpeedLim80ele" 295 "P_SpeedLim85" 296 "P_SpeedLim90" 297 "P_SpeedLim90ele" 298 "P_SpeedLim95" 299 "P_SpeedLimRev" 300 "P_SpeedLimRev10" 301 "P_SpeedLimRev100" 302 "P_SpeedLimRev105" 303 "P_SpeedLimRev110" 304 "P_SpeedLimRev115" 305 "P_SpeedLimRev120" 306 "P_SpeedLimRev15" 307 "P_SpeedLimRev20" 308 "P_SpeedLimRev25" 309 "P_SpeedLimRev30" 310 "P_SpeedLimRev35" 311 "P_SpeedLimRev40" 312 "P_SpeedLimRev45" 313 "P_SpeedLimRev5" 314 "P_SpeedLimRev50" 315 "P_SpeedLimRev55" 316 "P_SpeedLimRev60" 317 "P_SpeedLimRev65" 318 "P_SpeedLimRev70" 319 "P_SpeedLimRev75" 320 "P_SpeedLimRev80" 321 "P_SpeedLimRev85" 322 "P_SpeedLimRev90" 323 "P_SpeedLimRev95" 324 "P_StopFor" 325 "P_Unknow_SpeedLimele" 326 "P_Unknown1" 327 "P_VehicleOther" 328 "P_WeightLim" 329 "P_WeightLimWheel" 330 "P_WidthLim" 331 "RSBW_Misc" 332 "RSBW_Other" 333 "RSBW_Unknown" 334 "R_CircularIntersection" 335 "R_RoadSign_BlueWhite" 336 "RouteID_HighwayMark" 337 "RouteID_Other" 338 "RouteID_RedWhite" 339 "RouteID_TownRoadMark" 340 "RouteID_Unknown" 341 "RouteID_YellowBlack" 342 "SpeedLim10" 343 "SpeedLim100" 344 "SpeedLim100_electric" 345 "SpeedLim110" 346 "SpeedLim110_electric" 347 "SpeedLim120" 348 "SpeedLim120_electric" 349 "SpeedLim15" 350 "SpeedLim20" 351 "SpeedLim25" 352 "SpeedLim30" 353 "SpeedLim30_electric" 354 "SpeedLim35" 355 "SpeedLim40" 356 "SpeedLim40_electric" 357 "SpeedLim5" 358 "SpeedLim50" 359 "SpeedLim50_electric" 360 "SpeedLim55" 361 "SpeedLim5_electric" 362 "SpeedLim60" 363 "SpeedLim60_electric" 364 "SpeedLim65" 365 "SpeedLim70" 366 "SpeedLim70_electric" 367 "SpeedLim80" 368 "SpeedLim80_electric" 369 "SpeedLim90" 370 "SpeedLim90_electric" 371 "SpeedLimRev" 372 "TSBW_Other" 373 "TSBW_Unknown" 374 "T_TravelSign_BrownWhite" 375 "U_Unknown" 376 "W_AccidentProne" 377 "W_Animal" 378 "W_BadWeather" 379 "W_Bump" 380 "W_Bumpy" 381 "W_Children" 382 "W_Circle" 383 "W_ContinuousDown" 384 "W_ContinuousTurn" 385 "W_Cross" 386 "W_CrossIntersection" 387 "W_CrossLaneRail" 388 "W_Cycle" 389 "W_DamLeft" 390 "W_DamRight" 391 "W_Danger" 392 "W_DetourAround" 393 "W_DetourLeft" 394 "W_DetourRight" 395 "W_Disabled" 396 "W_Domestic" 397 "W_Down" 398 "W_EmergencyLane" 399 "W_Ferry" 400 "W_Fog" 401 "W_Ford" 402 "W_GuardedRailway" 403 "W_HumpBridge" 404 "W_Ice" 405 "W_KeepDistance" 406 "W_LRNarrow" 407 "W_LRTurn" 408 "W_LeftFalling" 409 "W_LeftNarrow" 410 "W_LeftTurn" 411 "W_LowLying" 412 "W_MergeLeft" 413 "W_MergeRight" 414 "W_MountLeft" 415 "W_MountRight" 416 "W_NarrowBridge" 417 "W_Other" 418 "W_Pedestrian" 419 "W_RLTurn" 420 "W_Railway" 421 "W_Rain" 422 "W_RightFalling" 423 "W_RightNarrow" 424 "W_RightTurn" 425 "W_SideWind" 426 "W_Side_Wind" 427 "W_Slash" 428 "W_Slip" 429 "W_Slow" 430 "W_SlowDown" 431 "W_SplitLeft" 432 "W_SplitRight" 433 "W_TIntersection" 434 "W_TShap" 435 "W_TShapLeft" 436 "W_TShapRight" 437 "W_Tidal" 438 "W_TrafficLight" 439 "W_Tripod" 440 "W_Tshape" 441 "W_Tshaps" 442 "W_Tunnel" 443 "W_TunnelHeadlight" 444 "W_TwoWay" 445 "W_Unknown" 446 "W_Up" 447 "W_VehicleQueue" 448 "W_Village" 449 "W_Working" 450 "W_YBLeft" 451 "W_YBRight" 452 "W_YB_Left" 453 "W_YB_Right" 454 "W_YLeft" 455 "W_YRight" 456 "W_Y_Left" 457 "W_Y_Right" 458 "sign_back" 459 "Other_IndicationsCircle" 460 "Other_IndicationsRectangle" 461 "Other_Circular_Marker" 462 "False_Positive" 463 "FP_Light_Time" 464 "RouteSign_Misc" 465 "Multi_Misc";
VAL_ 1315 TSR_Relevancy_523h 0 "Undefined" 1 "IN_HOSTLANE_SIGN" 2 "NOT_IN_HOSTLANE" 3 "HIGHWAY_EXIT_SIGN (Reserved)" 4 "SIGN_ON_TURN (Reserved)" 5 "FAR_IRRELEVANT_SIGN (Reserved)";
VAL_ 1315 TSR_Filter_Type_523h 0 "Not filtered" 1 "Irrelevant to the host driver" 2 "On vehicle/truck" 3 "Embedded(Reserved)" 4 "RESERVED" 5 "RESERVED" 6 "RESERVED" 7 "RESERVED";
VAL_ 1315 TSR_Approved_Flag_523h 0 "Not Approved" 1 "Approved";
VAL_ 1317 TSRTrafficSignType_525h 0 "C_Other" 1 "C_Unknown" 2 "Construction" 3 "FP_Accessory_Arrow" 4 "FP_Building" 5 "FP_Circular_Marker" 6 "FP_Head" 7 "FP_Light_Arrow" 8 "FP_Light_Circle" 9 "FP_Light_Shell" 10 "FP_Mirror" 11 "FP_Other" 12 "FP_Polygon_Marker" 13 "FP_Route_Number" 14 "FP_Twig" 15 "FP_Unknown" 16 "FP_Vehicle_Wheel" 17 "GSGW_Misc" 18 "GSGW_Other" 19 "GSGW_Unknown" 20 "GSWB_Misc" 21 "GSWB_Other" 22 "GSWB_Unknown" 23 "G_GuideSign_GreenWhite" 24 "G_GuideSign_WhiteBlack" 25 "GuideSign_MultiMisc" 26 "IR_AccidentPronePoint" 27 "IR_Accommodation" 28 "IR_AdministrativeBoundary" 29 "IR_Airport" 30 "IR_Area" 31 "IR_AvoidLine" 32 "IR_BifurcationMark" 33 "IR_BigCarRight" 34 "IR_Blocked" 35 "IR_BusStation" 36 "IR_CarRepair" 37 "IR_CarWash" 38 "IR_CateringServices" 39 "IR_CombinationAuxiliary" 40 "IR_ContinuousDownhill" 41 "IR_CountryRoadNumMark" 42 "IR_CrossIntersection" 43 "IR_CrossingMarking" 44 "IR_DisabledSpecial" 45 "IR_DistanceArea" 46 "IR_Drink" 47 "IR_DrivingDirection" 48 "IR_ETCLanes" 49 "IR_ElectricalETC" 50 "IR_EmergencyShelter" 51 "IR_FamousPlaceName" 52 "IR_Ferry" 53 "IR_FerryPier" 54 "IR_FirstAidStation" 55 "IR_Foggy" 56 "IR_FootBridge" 57 "IR_GasStation" 58 "IR_HighwayCarDistanceConfirmation" 59 "IR_HighwayClimbingLine" 60 "IR_HighwayDirection" 61 "IR_HighwayETCLanes" 62 "IR_HighwayETCTollStationsNotice" 63 "IR_HighwayEmergencyParkingBelt" 64 "IR_HighwayEmergencyPhone" 65 "IR_HighwayEnd" 66 "IR_HighwayEndNotice" 67 "IR_HighwayEntrance" 68 "IR_HighwayEntranceNotice" 69 "IR_HighwayExit" 70 "IR_HighwayExitNotice" 71 "IR_HighwayGasStation" 72 "IR_HighwayHundredCard" 73 "IR_HighwayLocationDirection" 74 "IR_HighwayLocationDistance" 75 "IR_HighwayMileageCard" 76 "IR_HighwayName" 77 "IR_HighwayNextExitNotice" 78 "IR_HighwayOverloadCheck" 79 "IR_HighwayParkinAreaNotice" 80 "IR_HighwayParkingLotNotice" 81 "IR_HighwayRescueCall" 82 "IR_HighwayRoadTrafficInformation" 83 "IR_HighwayServiceNotice" 84 "IR_HighwaySlowDown" 85 "IR_HighwayStart" 86 "IR_HighwayTicket" 87 "IR_HighwayTollStationsNotice" 88 "IR_Interchange" 89 "IR_IntersectionNotice" 90 "IR_LanesDecrease" 91 "IR_LanesIncrease" 92 "IR_Linearguide" 93 "IR_LocationDistance" 94 "IR_LongDistanceBusStation" 95 "IR_MilePost" 96 "IR_MobileConstruction" 97 "IR_Nameplate" 98 "IR_Parking" 99 "IR_ParkingLot" 100 "IR_PassingTime" 101 "IR_PedestrianTunnel" 102 "IR_PedestrianUnderpass" 103 "IR_PlaceName" 104 "IR_Police" 105 "IR_Port" 106 "IR_ProtectAnimals" 107 "IR_Quarantine" 108 "IR_RailwayStation" 109 "IR_Ramp" 110 "IR_RampArrow" 111 "IR_RestArea" 112 "IR_RoadManageBoundary" 113 "IR_RoadStop" 114 "IR_SlowRoad" 115 "IR_Snack" 116 "IR_SoftFoundation" 117 "IR_SteepSlope" 118 "IR_StreetName" 119 "IR_SubwayStation" 120 "IR_Taxi" 121 "IR_Tcorssing" 122 "IR_TouristAreaDirectionDistance" 123 "IR_TrafficSupervisory" 124 "IR_TransferCenter" 125 "IR_TransverseWind" 126 "IR_TravelSymbols" 127 "IR_Tunnel" 128 "IR_TunnelNextExitNotice" 129 "IR_VehicleType" 130 "IR_ViewingPoint" 131 "IR_WarningReason" 132 "IR_WeightCharge" 133 "IR_Ycorssing" 134 "IR_Zones" 135 "IR_ZonesII" 136 "I_AllowUturn" 137 "I_Circle" 138 "I_FastBusLane" 139 "I_Forward" 140 "I_ForwardLane" 141 "I_ForwardLeft" 142 "I_ForwardLeftLane" 143 "I_ForwardLeftStereo" 144 "I_ForwardRight" 145 "I_ForwardRightLane" 146 "I_ForwardRightStereo" 147 "I_Honk" 148 "I_Left" 149 "I_LeftBusLane" 150 "I_LeftLine" 151 "I_LeftRight" 152 "I_LeftTurn" 153 "I_LeftTurnLane" 154 "I_MinSpeedLim100" 155 "I_MinSpeedLim110" 156 "I_MinSpeedLim40" 157 "I_MinSpeedLim50" 158 "I_MinSpeedLim60" 159 "I_MinSpeedLim70" 160 "I_MinSpeedLim80" 161 "I_MinSpeedLim90" 162 "I_Motors" 163 "I_MotorsLane" 164 "I_MultiOccupantMotorsLane" 165 "I_NonMotors" 166 "I_NonMotorsLane" 167 "I_Other_circle" 168 "I_Other_rectangle" 169 "I_ParkingSpace" 170 "I_Passingfirst" 171 "I_PedestrianCross" 172 "I_PriorityIntereesction" 173 "I_Right" 174 "I_RightLine" 175 "I_RightTurn" 176 "I_RightTurnLane" 177 "I_SplitDriveLine" 178 "I_StraightLine" 179 "I_UTurnAndLeftLane" 180 "I_UTurnLane" 181 "I_Unknown_circle" 182 "I_Unknown_rectangle" 183 "I_Uturn" 184 "I_Walk" 185 "MSL_Other" 186 "MSL_Unknown" 187 "MinSpeedLim100" 188 "MinSpeedLim110" 189 "MinSpeedLim50" 190 "MinSpeedLim60" 191 "MinSpeedLim70" 192 "MinSpeedLim80" 193 "MinSpeedLim90" 194 "NoPassingRev" 195 "O_Other" 196 "Other" 197 "Other_Construction_Sign" 198 "Other_Detfp" 199 "Other_Exit" 200 "Other_GuideSign_BlueWhite" 201 "Other_GuideSign_GreenWhite" 202 "Other_GuideSign_WhiteBlack" 203 "Other_Indications" 204 "Other_LightArrow" 205 "Other_Min_Speed" 206 "Other_Mirror" 207 "Other_NoParking" 208 "Other_Prohibit" 209 "Other_RedCircleLight" 210 "Other_RouteID_RedWhite" 211 "Other_RouteID_YellowBlack" 212 "Other_TravelSign_BrownWhite" 213 "Other_Warning" 214 "PR_Other" 215 "PR_Unknown" 216 "PSL_Other" 217 "PSL_Unknown" 218 "P_Custom" 219 "P_GiveWay" 220 "P_HeightLim" 221 "P_MultiVehicle" 222 "P_NoAnimalVehicle" 223 "P_NoBikeDownSlope" 224 "P_NoBikeUpSlope" 225 "P_NoBus" 226 "P_NoCar" 227 "P_NoCargoTricycle" 228 "P_NoDangerous" 229 "P_NoEntry" 230 "P_NoForward" 231 "P_NoForwardLeft" 232 "P_NoForwardRight" 233 "P_NoHorning" 234 "P_NoHuman" 235 "P_NoHumanCargoTriangle" 236 "P_NoHumanPassengerTriangle" 237 "P_NoHumanVehicle" 238 "P_NoLeftRightTurn" 239 "P_NoLeftTurn" 240 "P_NoLongParking" 241 "P_NoLongParkingRev" 242 "P_NoMinibus" 243 "P_NoMotoTricycle" 244 "P_NoMotor" 245 "P_NoMotorcycle" 246 "P_NoNonMotor" 247 "P_NoParking" 248 "P_NoParkingRev" 249 "P_NoPassing" 250 "P_NoPassingRev" 251 "P_NoReturn" 252 "P_NoRightTurn" 253 "P_NoSpecificLeftTurn" 254 "P_NoSpecificRightTurn" 255 "P_NoTractor" 256 "P_NoTrailer" 257 "P_NoTricycle" 258 "P_NoTruck" 259 "P_Noway" 260 "P_Other1" 261 "P_Other_SpeedLimele" 262 "P_ParkingCheck" 263 "P_SlowFor" 264 "P_SpeedLim10" 265 "P_SpeedLim100" 266 "P_SpeedLim100ele" 267 "P_SpeedLim105" 268 "P_SpeedLim110" 269 "P_SpeedLim110ele" 270 "P_SpeedLim115" 271 "P_SpeedLim120" 272 "P_SpeedLim120ele" 273 "P_SpeedLim15" 274 "P_SpeedLim20" 275 "P_SpeedLim20ele" 276 "P_SpeedLim25" 277 "P_SpeedLim30" 278 "P_SpeedLim30ele" 279 "P_SpeedLim35" 280 "P_SpeedLim40" 281 "P_SpeedLim40ele" 282 "P_SpeedLim45" 283 "P_SpeedLim5" 284 "P_SpeedLim50" 285 "P_SpeedLim50ele" 286 "P_SpeedLim55" 287 "P_SpeedLim60" 288 "P_SpeedLim60ele" 289 "P_SpeedLim65" 290 "P_SpeedLim70" 291 "P_SpeedLim70ele" 292 "P_SpeedLim75" 293 "P_SpeedLim80" 294 "P_SpeedLim80ele" 295 "P_SpeedLim85" 296 "P_SpeedLim90" 297 "P_SpeedLim90ele" 298 "P_SpeedLim95" 299 "P_SpeedLimRev" 300 "P_SpeedLimRev10" 301 "P_SpeedLimRev100" 302 "P_SpeedLimRev105" 303 "P_SpeedLimRev110" 304 "P_SpeedLimRev115" 305 "P_SpeedLimRev120" 306 "P_SpeedLimRev15" 307 "P_SpeedLimRev20" 308 "P_SpeedLimRev25" 309 "P_SpeedLimRev30" 310 "P_SpeedLimRev35" 311 "P_SpeedLimRev40" 312 "P_SpeedLimRev45" 313 "P_SpeedLimRev5" 314 "P_SpeedLimRev50" 315 "P_SpeedLimRev55" 316 "P_SpeedLimRev60" 317 "P_SpeedLimRev65" 318 "P_SpeedLimRev70" 319 "P_SpeedLimRev75" 320 "P_SpeedLimRev80" 321 "P_SpeedLimRev85" 322 "P_SpeedLimRev90" 323 "P_SpeedLimRev95" 324 "P_StopFor" 325 "P_Unknow_SpeedLimele" 326 "P_Unknown1" 327 "P_VehicleOther" 328 "P_WeightLim" 329 "P_WeightLimWheel" 330 "P_WidthLim" 331 "RSBW_Misc" 332 "RSBW_Other" 333 "RSBW_Unknown" 334 "R_CircularIntersection" 335 "R_RoadSign_BlueWhite" 336 "RouteID_HighwayMark" 337 "RouteID_Other" 338 "RouteID_RedWhite" 339 "RouteID_TownRoadMark" 340 "RouteID_Unknown" 341 "RouteID_YellowBlack" 342 "SpeedLim10" 343 "SpeedLim100" 344 "SpeedLim100_electric" 345 "SpeedLim110" 346 "SpeedLim110_electric" 347 "SpeedLim120" 348 "SpeedLim120_electric" 349 "SpeedLim15" 350 "SpeedLim20" 351 "SpeedLim25" 352 "SpeedLim30" 353 "SpeedLim30_electric" 354 "SpeedLim35" 355 "SpeedLim40" 356 "SpeedLim40_electric" 357 "SpeedLim5" 358 "SpeedLim50" 359 "SpeedLim50_electric" 360 "SpeedLim55" 361 "SpeedLim5_electric" 362 "SpeedLim60" 363 "SpeedLim60_electric" 364 "SpeedLim65" 365 "SpeedLim70" 366 "SpeedLim70_electric" 367 "SpeedLim80" 368 "SpeedLim80_electric" 369 "SpeedLim90" 370 "SpeedLim90_electric" 371 "SpeedLimRev" 372 "TSBW_Other" 373 "TSBW_Unknown" 374 "T_TravelSign_BrownWhite" 375 "U_Unknown" 376 "W_AccidentProne" 377 "W_Animal" 378 "W_BadWeather" 379 "W_Bump" 380 "W_Bumpy" 381 "W_Children" 382 "W_Circle" 383 "W_ContinuousDown" 384 "W_ContinuousTurn" 385 "W_Cross" 386 "W_CrossIntersection" 387 "W_CrossLaneRail" 388 "W_Cycle" 389 "W_DamLeft" 390 "W_DamRight" 391 "W_Danger" 392 "W_DetourAround" 393 "W_DetourLeft" 394 "W_DetourRight" 395 "W_Disabled" 396 "W_Domestic" 397 "W_Down" 398 "W_EmergencyLane" 399 "W_Ferry" 400 "W_Fog" 401 "W_Ford" 402 "W_GuardedRailway" 403 "W_HumpBridge" 404 "W_Ice" 405 "W_KeepDistance" 406 "W_LRNarrow" 407 "W_LRTurn" 408 "W_LeftFalling" 409 "W_LeftNarrow" 410 "W_LeftTurn" 411 "W_LowLying" 412 "W_MergeLeft" 413 "W_MergeRight" 414 "W_MountLeft" 415 "W_MountRight" 416 "W_NarrowBridge" 417 "W_Other" 418 "W_Pedestrian" 419 "W_RLTurn" 420 "W_Railway" 421 "W_Rain" 422 "W_RightFalling" 423 "W_RightNarrow" 424 "W_RightTurn" 425 "W_SideWind" 426 "W_Side_Wind" 427 "W_Slash" 428 "W_Slip" 429 "W_Slow" 430 "W_SlowDown" 431 "W_SplitLeft" 432 "W_SplitRight" 433 "W_TIntersection" 434 "W_TShap" 435 "W_TShapLeft" 436 "W_TShapRight" 437 "W_Tidal" 438 "W_TrafficLight" 439 "W_Tripod" 440 "W_Tshape" 441 "W_Tshaps" 442 "W_Tunnel" 443 "W_TunnelHeadlight" 444 "W_TwoWay" 445 "W_Unknown" 446 "W_Up" 447 "W_VehicleQueue" 448 "W_Village" 449 "W_Working" 450 "W_YBLeft" 451 "W_YBRight" 452 "W_YB_Left" 453 "W_YB_Right" 454 "W_YLeft" 455 "W_YRight" 456 "W_Y_Left" 457 "W_Y_Right" 458 "sign_back" 459 "Other_IndicationsCircle" 460 "Other_IndicationsRectangle" 461 "Other_Circular_Marker" 462 "False_Positive" 463 "FP_Light_Time" 464 "RouteSign_Misc" 465 "Multi_Misc";
VAL_ 1317 TSR_Relevancy_525h 0 "Undefined" 1 "IN_HOSTLANE_SIGN" 2 "NOT_IN_HOSTLANE" 3 "HIGHWAY_EXIT_SIGN (Reserved)" 4 "SIGN_ON_TURN (Reserved)" 5 "FAR_IRRELEVANT_SIGN (Reserved)";
VAL_ 1317 TSR_Filter_Type_525h 0 "Not filtered" 1 "Irrelevant to the host driver" 2 "On vehicle/truck" 3 "Embedded(Reserved)" 4 "RESERVED" 5 "RESERVED" 6 "RESERVED" 7 "RESERVED";
VAL_ 1317 TSR_Approved_Flag_525h 0 "Not Approved" 1 "Approved";
VAL_ 1319 TSRTrafficSignType_527h 0 "C_Other" 1 "C_Unknown" 2 "Construction" 3 "FP_Accessory_Arrow" 4 "FP_Building" 5 "FP_Circular_Marker" 6 "FP_Head" 7 "FP_Light_Arrow" 8 "FP_Light_Circle" 9 "FP_Light_Shell" 10 "FP_Mirror" 11 "FP_Other" 12 "FP_Polygon_Marker" 13 "FP_Route_Number" 14 "FP_Twig" 15 "FP_Unknown" 16 "FP_Vehicle_Wheel" 17 "GSGW_Misc" 18 "GSGW_Other" 19 "GSGW_Unknown" 20 "GSWB_Misc" 21 "GSWB_Other" 22 "GSWB_Unknown" 23 "G_GuideSign_GreenWhite" 24 "G_GuideSign_WhiteBlack" 25 "GuideSign_MultiMisc" 26 "IR_AccidentPronePoint" 27 "IR_Accommodation" 28 "IR_AdministrativeBoundary" 29 "IR_Airport" 30 "IR_Area" 31 "IR_AvoidLine" 32 "IR_BifurcationMark" 33 "IR_BigCarRight" 34 "IR_Blocked" 35 "IR_BusStation" 36 "IR_CarRepair" 37 "IR_CarWash" 38 "IR_CateringServices" 39 "IR_CombinationAuxiliary" 40 "IR_ContinuousDownhill" 41 "IR_CountryRoadNumMark" 42 "IR_CrossIntersection" 43 "IR_CrossingMarking" 44 "IR_DisabledSpecial" 45 "IR_DistanceArea" 46 "IR_Drink" 47 "IR_DrivingDirection" 48 "IR_ETCLanes" 49 "IR_ElectricalETC" 50 "IR_EmergencyShelter" 51 "IR_FamousPlaceName" 52 "IR_Ferry" 53 "IR_FerryPier" 54 "IR_FirstAidStation" 55 "IR_Foggy" 56 "IR_FootBridge" 57 "IR_GasStation" 58 "IR_HighwayCarDistanceConfirmation" 59 "IR_HighwayClimbingLine" 60 "IR_HighwayDirection" 61 "IR_HighwayETCLanes" 62 "IR_HighwayETCTollStationsNotice" 63 "IR_HighwayEmergencyParkingBelt" 64 "IR_HighwayEmergencyPhone" 65 "IR_HighwayEnd" 66 "IR_HighwayEndNotice" 67 "IR_HighwayEntrance" 68 "IR_HighwayEntranceNotice" 69 "IR_HighwayExit" 70 "IR_HighwayExitNotice" 71 "IR_HighwayGasStation" 72 "IR_HighwayHundredCard" 73 "IR_HighwayLocationDirection" 74 "IR_HighwayLocationDistance" 75 "IR_HighwayMileageCard" 76 "IR_HighwayName" 77 "IR_HighwayNextExitNotice" 78 "IR_HighwayOverloadCheck" 79 "IR_HighwayParkinAreaNotice" 80 "IR_HighwayParkingLotNotice" 81 "IR_HighwayRescueCall" 82 "IR_HighwayRoadTrafficInformation" 83 "IR_HighwayServiceNotice" 84 "IR_HighwaySlowDown" 85 "IR_HighwayStart" 86 "IR_HighwayTicket" 87 "IR_HighwayTollStationsNotice" 88 "IR_Interchange" 89 "IR_IntersectionNotice" 90 "IR_LanesDecrease" 91 "IR_LanesIncrease" 92 "IR_Linearguide" 93 "IR_LocationDistance" 94 "IR_LongDistanceBusStation" 95 "IR_MilePost" 96 "IR_MobileConstruction" 97 "IR_Nameplate" 98 "IR_Parking" 99 "IR_ParkingLot" 100 "IR_PassingTime" 101 "IR_PedestrianTunnel" 102 "IR_PedestrianUnderpass" 103 "IR_PlaceName" 104 "IR_Police" 105 "IR_Port" 106 "IR_ProtectAnimals" 107 "IR_Quarantine" 108 "IR_RailwayStation" 109 "IR_Ramp" 110 "IR_RampArrow" 111 "IR_RestArea" 112 "IR_RoadManageBoundary" 113 "IR_RoadStop" 114 "IR_SlowRoad" 115 "IR_Snack" 116 "IR_SoftFoundation" 117 "IR_SteepSlope" 118 "IR_StreetName" 119 "IR_SubwayStation" 120 "IR_Taxi" 121 "IR_Tcorssing" 122 "IR_TouristAreaDirectionDistance" 123 "IR_TrafficSupervisory" 124 "IR_TransferCenter" 125 "IR_TransverseWind" 126 "IR_TravelSymbols" 127 "IR_Tunnel" 128 "IR_TunnelNextExitNotice" 129 "IR_VehicleType" 130 "IR_ViewingPoint" 131 "IR_WarningReason" 132 "IR_WeightCharge" 133 "IR_Ycorssing" 134 "IR_Zones" 135 "IR_ZonesII" 136 "I_AllowUturn" 137 "I_Circle" 138 "I_FastBusLane" 139 "I_Forward" 140 "I_ForwardLane" 141 "I_ForwardLeft" 142 "I_ForwardLeftLane" 143 "I_ForwardLeftStereo" 144 "I_ForwardRight" 145 "I_ForwardRightLane" 146 "I_ForwardRightStereo" 147 "I_Honk" 148 "I_Left" 149 "I_LeftBusLane" 150 "I_LeftLine" 151 "I_LeftRight" 152 "I_LeftTurn" 153 "I_LeftTurnLane" 154 "I_MinSpeedLim100" 155 "I_MinSpeedLim110" 156 "I_MinSpeedLim40" 157 "I_MinSpeedLim50" 158 "I_MinSpeedLim60" 159 "I_MinSpeedLim70" 160 "I_MinSpeedLim80" 161 "I_MinSpeedLim90" 162 "I_Motors" 163 "I_MotorsLane" 164 "I_MultiOccupantMotorsLane" 165 "I_NonMotors" 166 "I_NonMotorsLane" 167 "I_Other_circle" 168 "I_Other_rectangle" 169 "I_ParkingSpace" 170 "I_Passingfirst" 171 "I_PedestrianCross" 172 "I_PriorityIntereesction" 173 "I_Right" 174 "I_RightLine" 175 "I_RightTurn" 176 "I_RightTurnLane" 177 "I_SplitDriveLine" 178 "I_StraightLine" 179 "I_UTurnAndLeftLane" 180 "I_UTurnLane" 181 "I_Unknown_circle" 182 "I_Unknown_rectangle" 183 "I_Uturn" 184 "I_Walk" 185 "MSL_Other" 186 "MSL_Unknown" 187 "MinSpeedLim100" 188 "MinSpeedLim110" 189 "MinSpeedLim50" 190 "MinSpeedLim60" 191 "MinSpeedLim70" 192 "MinSpeedLim80" 193 "MinSpeedLim90" 194 "NoPassingRev" 195 "O_Other" 196 "Other" 197 "Other_Construction_Sign" 198 "Other_Detfp" 199 "Other_Exit" 200 "Other_GuideSign_BlueWhite" 201 "Other_GuideSign_GreenWhite" 202 "Other_GuideSign_WhiteBlack" 203 "Other_Indications" 204 "Other_LightArrow" 205 "Other_Min_Speed" 206 "Other_Mirror" 207 "Other_NoParking" 208 "Other_Prohibit" 209 "Other_RedCircleLight" 210 "Other_RouteID_RedWhite" 211 "Other_RouteID_YellowBlack" 212 "Other_TravelSign_BrownWhite" 213 "Other_Warning" 214 "PR_Other" 215 "PR_Unknown" 216 "PSL_Other" 217 "PSL_Unknown" 218 "P_Custom" 219 "P_GiveWay" 220 "P_HeightLim" 221 "P_MultiVehicle" 222 "P_NoAnimalVehicle" 223 "P_NoBikeDownSlope" 224 "P_NoBikeUpSlope" 225 "P_NoBus" 226 "P_NoCar" 227 "P_NoCargoTricycle" 228 "P_NoDangerous" 229 "P_NoEntry" 230 "P_NoForward" 231 "P_NoForwardLeft" 232 "P_NoForwardRight" 233 "P_NoHorning" 234 "P_NoHuman" 235 "P_NoHumanCargoTriangle" 236 "P_NoHumanPassengerTriangle" 237 "P_NoHumanVehicle" 238 "P_NoLeftRightTurn" 239 "P_NoLeftTurn" 240 "P_NoLongParking" 241 "P_NoLongParkingRev" 242 "P_NoMinibus" 243 "P_NoMotoTricycle" 244 "P_NoMotor" 245 "P_NoMotorcycle" 246 "P_NoNonMotor" 247 "P_NoParking" 248 "P_NoParkingRev" 249 "P_NoPassing" 250 "P_NoPassingRev" 251 "P_NoReturn" 252 "P_NoRightTurn" 253 "P_NoSpecificLeftTurn" 254 "P_NoSpecificRightTurn" 255 "P_NoTractor" 256 "P_NoTrailer" 257 "P_NoTricycle" 258 "P_NoTruck" 259 "P_Noway" 260 "P_Other1" 261 "P_Other_SpeedLimele" 262 "P_ParkingCheck" 263 "P_SlowFor" 264 "P_SpeedLim10" 265 "P_SpeedLim100" 266 "P_SpeedLim100ele" 267 "P_SpeedLim105" 268 "P_SpeedLim110" 269 "P_SpeedLim110ele" 270 "P_SpeedLim115" 271 "P_SpeedLim120" 272 "P_SpeedLim120ele" 273 "P_SpeedLim15" 274 "P_SpeedLim20" 275 "P_SpeedLim20ele" 276 "P_SpeedLim25" 277 "P_SpeedLim30" 278 "P_SpeedLim30ele" 279 "P_SpeedLim35" 280 "P_SpeedLim40" 281 "P_SpeedLim40ele" 282 "P_SpeedLim45" 283 "P_SpeedLim5" 284 "P_SpeedLim50" 285 "P_SpeedLim50ele" 286 "P_SpeedLim55" 287 "P_SpeedLim60" 288 "P_SpeedLim60ele" 289 "P_SpeedLim65" 290 "P_SpeedLim70" 291 "P_SpeedLim70ele" 292 "P_SpeedLim75" 293 "P_SpeedLim80" 294 "P_SpeedLim80ele" 295 "P_SpeedLim85" 296 "P_SpeedLim90" 297 "P_SpeedLim90ele" 298 "P_SpeedLim95" 299 "P_SpeedLimRev" 300 "P_SpeedLimRev10" 301 "P_SpeedLimRev100" 302 "P_SpeedLimRev105" 303 "P_SpeedLimRev110" 304 "P_SpeedLimRev115" 305 "P_SpeedLimRev120" 306 "P_SpeedLimRev15" 307 "P_SpeedLimRev20" 308 "P_SpeedLimRev25" 309 "P_SpeedLimRev30" 310 "P_SpeedLimRev35" 311 "P_SpeedLimRev40" 312 "P_SpeedLimRev45" 313 "P_SpeedLimRev5" 314 "P_SpeedLimRev50" 315 "P_SpeedLimRev55" 316 "P_SpeedLimRev60" 317 "P_SpeedLimRev65" 318 "P_SpeedLimRev70" 319 "P_SpeedLimRev75" 320 "P_SpeedLimRev80" 321 "P_SpeedLimRev85" 322 "P_SpeedLimRev90" 323 "P_SpeedLimRev95" 324 "P_StopFor" 325 "P_Unknow_SpeedLimele" 326 "P_Unknown1" 327 "P_VehicleOther" 328 "P_WeightLim" 329 "P_WeightLimWheel" 330 "P_WidthLim" 331 "RSBW_Misc" 332 "RSBW_Other" 333 "RSBW_Unknown" 334 "R_CircularIntersection" 335 "R_RoadSign_BlueWhite" 336 "RouteID_HighwayMark" 337 "RouteID_Other" 338 "RouteID_RedWhite" 339 "RouteID_TownRoadMark" 340 "RouteID_Unknown" 341 "RouteID_YellowBlack" 342 "SpeedLim10" 343 "SpeedLim100" 344 "SpeedLim100_electric" 345 "SpeedLim110" 346 "SpeedLim110_electric" 347 "SpeedLim120" 348 "SpeedLim120_electric" 349 "SpeedLim15" 350 "SpeedLim20" 351 "SpeedLim25" 352 "SpeedLim30" 353 "SpeedLim30_electric" 354 "SpeedLim35" 355 "SpeedLim40" 356 "SpeedLim40_electric" 357 "SpeedLim5" 358 "SpeedLim50" 359 "SpeedLim50_electric" 360 "SpeedLim55" 361 "SpeedLim5_electric" 362 "SpeedLim60" 363 "SpeedLim60_electric" 364 "SpeedLim65" 365 "SpeedLim70" 366 "SpeedLim70_electric" 367 "SpeedLim80" 368 "SpeedLim80_electric" 369 "SpeedLim90" 370 "SpeedLim90_electric" 371 "SpeedLimRev" 372 "TSBW_Other" 373 "TSBW_Unknown" 374 "T_TravelSign_BrownWhite" 375 "U_Unknown" 376 "W_AccidentProne" 377 "W_Animal" 378 "W_BadWeather" 379 "W_Bump" 380 "W_Bumpy" 381 "W_Children" 382 "W_Circle" 383 "W_ContinuousDown" 384 "W_ContinuousTurn" 385 "W_Cross" 386 "W_CrossIntersection" 387 "W_CrossLaneRail" 388 "W_Cycle" 389 "W_DamLeft" 390 "W_DamRight" 391 "W_Danger" 392 "W_DetourAround" 393 "W_DetourLeft" 394 "W_DetourRight" 395 "W_Disabled" 396 "W_Domestic" 397 "W_Down" 398 "W_EmergencyLane" 399 "W_Ferry" 400 "W_Fog" 401 "W_Ford" 402 "W_GuardedRailway" 403 "W_HumpBridge" 404 "W_Ice" 405 "W_KeepDistance" 406 "W_LRNarrow" 407 "W_LRTurn" 408 "W_LeftFalling" 409 "W_LeftNarrow" 410 "W_LeftTurn" 411 "W_LowLying" 412 "W_MergeLeft" 413 "W_MergeRight" 414 "W_MountLeft" 415 "W_MountRight" 416 "W_NarrowBridge" 417 "W_Other" 418 "W_Pedestrian" 419 "W_RLTurn" 420 "W_Railway" 421 "W_Rain" 422 "W_RightFalling" 423 "W_RightNarrow" 424 "W_RightTurn" 425 "W_SideWind" 426 "W_Side_Wind" 427 "W_Slash" 428 "W_Slip" 429 "W_Slow" 430 "W_SlowDown" 431 "W_SplitLeft" 432 "W_SplitRight" 433 "W_TIntersection" 434 "W_TShap" 435 "W_TShapLeft" 436 "W_TShapRight" 437 "W_Tidal" 438 "W_TrafficLight" 439 "W_Tripod" 440 "W_Tshape" 441 "W_Tshaps" 442 "W_Tunnel" 443 "W_TunnelHeadlight" 444 "W_TwoWay" 445 "W_Unknown" 446 "W_Up" 447 "W_VehicleQueue" 448 "W_Village" 449 "W_Working" 450 "W_YBLeft" 451 "W_YBRight" 452 "W_YB_Left" 453 "W_YB_Right" 454 "W_YLeft" 455 "W_YRight" 456 "W_Y_Left" 457 "W_Y_Right" 458 "sign_back" 459 "Other_IndicationsCircle" 460 "Other_IndicationsRectangle" 461 "Other_Circular_Marker" 462 "False_Positive" 463 "FP_Light_Time" 464 "RouteSign_Misc" 465 "Multi_Misc";
VAL_ 1319 TSR_Relevancy_527h 0 "Undefined" 1 "IN_HOSTLANE_SIGN" 2 "NOT_IN_HOSTLANE" 3 "HIGHWAY_EXIT_SIGN (Reserved)" 4 "SIGN_ON_TURN (Reserved)" 5 "FAR_IRRELEVANT_SIGN (Reserved)";
VAL_ 1319 TSR_Filter_Type_527h 0 "Not filtered" 1 "Irrelevant to the host driver" 2 "On vehicle/truck" 3 "Embedded(Reserved)" 4 "RESERVED" 5 "RESERVED" 6 "RESERVED" 7 "RESERVED";
VAL_ 1319 TSR_Approved_Flag_527h 0 "Not Approved" 1 "Approved";
VAL_ 1321 TSRTrafficSignType_529h 0 "C_Other" 1 "C_Unknown" 2 "Construction" 3 "FP_Accessory_Arrow" 4 "FP_Building" 5 "FP_Circular_Marker" 6 "FP_Head" 7 "FP_Light_Arrow" 8 "FP_Light_Circle" 9 "FP_Light_Shell" 10 "FP_Mirror" 11 "FP_Other" 12 "FP_Polygon_Marker" 13 "FP_Route_Number" 14 "FP_Twig" 15 "FP_Unknown" 16 "FP_Vehicle_Wheel" 17 "GSGW_Misc" 18 "GSGW_Other" 19 "GSGW_Unknown" 20 "GSWB_Misc" 21 "GSWB_Other" 22 "GSWB_Unknown" 23 "G_GuideSign_GreenWhite" 24 "G_GuideSign_WhiteBlack" 25 "GuideSign_MultiMisc" 26 "IR_AccidentPronePoint" 27 "IR_Accommodation" 28 "IR_AdministrativeBoundary" 29 "IR_Airport" 30 "IR_Area" 31 "IR_AvoidLine" 32 "IR_BifurcationMark" 33 "IR_BigCarRight" 34 "IR_Blocked" 35 "IR_BusStation" 36 "IR_CarRepair" 37 "IR_CarWash" 38 "IR_CateringServices" 39 "IR_CombinationAuxiliary" 40 "IR_ContinuousDownhill" 41 "IR_CountryRoadNumMark" 42 "IR_CrossIntersection" 43 "IR_CrossingMarking" 44 "IR_DisabledSpecial" 45 "IR_DistanceArea" 46 "IR_Drink" 47 "IR_DrivingDirection" 48 "IR_ETCLanes" 49 "IR_ElectricalETC" 50 "IR_EmergencyShelter" 51 "IR_FamousPlaceName" 52 "IR_Ferry" 53 "IR_FerryPier" 54 "IR_FirstAidStation" 55 "IR_Foggy" 56 "IR_FootBridge" 57 "IR_GasStation" 58 "IR_HighwayCarDistanceConfirmation" 59 "IR_HighwayClimbingLine" 60 "IR_HighwayDirection" 61 "IR_HighwayETCLanes" 62 "IR_HighwayETCTollStationsNotice" 63 "IR_HighwayEmergencyParkingBelt" 64 "IR_HighwayEmergencyPhone" 65 "IR_HighwayEnd" 66 "IR_HighwayEndNotice" 67 "IR_HighwayEntrance" 68 "IR_HighwayEntranceNotice" 69 "IR_HighwayExit" 70 "IR_HighwayExitNotice" 71 "IR_HighwayGasStation" 72 "IR_HighwayHundredCard" 73 "IR_HighwayLocationDirection" 74 "IR_HighwayLocationDistance" 75 "IR_HighwayMileageCard" 76 "IR_HighwayName" 77 "IR_HighwayNextExitNotice" 78 "IR_HighwayOverloadCheck" 79 "IR_HighwayParkinAreaNotice" 80 "IR_HighwayParkingLotNotice" 81 "IR_HighwayRescueCall" 82 "IR_HighwayRoadTrafficInformation" 83 "IR_HighwayServiceNotice" 84 "IR_HighwaySlowDown" 85 "IR_HighwayStart" 86 "IR_HighwayTicket" 87 "IR_HighwayTollStationsNotice" 88 "IR_Interchange" 89 "IR_IntersectionNotice" 90 "IR_LanesDecrease" 91 "IR_LanesIncrease" 92 "IR_Linearguide" 93 "IR_LocationDistance" 94 "IR_LongDistanceBusStation" 95 "IR_MilePost" 96 "IR_MobileConstruction" 97 "IR_Nameplate" 98 "IR_Parking" 99 "IR_ParkingLot" 100 "IR_PassingTime" 101 "IR_PedestrianTunnel" 102 "IR_PedestrianUnderpass" 103 "IR_PlaceName" 104 "IR_Police" 105 "IR_Port" 106 "IR_ProtectAnimals" 107 "IR_Quarantine" 108 "IR_RailwayStation" 109 "IR_Ramp" 110 "IR_RampArrow" 111 "IR_RestArea" 112 "IR_RoadManageBoundary" 113 "IR_RoadStop" 114 "IR_SlowRoad" 115 "IR_Snack" 116 "IR_SoftFoundation" 117 "IR_SteepSlope" 118 "IR_StreetName" 119 "IR_SubwayStation" 120 "IR_Taxi" 121 "IR_Tcorssing" 122 "IR_TouristAreaDirectionDistance" 123 "IR_TrafficSupervisory" 124 "IR_TransferCenter" 125 "IR_TransverseWind" 126 "IR_TravelSymbols" 127 "IR_Tunnel" 128 "IR_TunnelNextExitNotice" 129 "IR_VehicleType" 130 "IR_ViewingPoint" 131 "IR_WarningReason" 132 "IR_WeightCharge" 133 "IR_Ycorssing" 134 "IR_Zones" 135 "IR_ZonesII" 136 "I_AllowUturn" 137 "I_Circle" 138 "I_FastBusLane" 139 "I_Forward" 140 "I_ForwardLane" 141 "I_ForwardLeft" 142 "I_ForwardLeftLane" 143 "I_ForwardLeftStereo" 144 "I_ForwardRight" 145 "I_ForwardRightLane" 146 "I_ForwardRightStereo" 147 "I_Honk" 148 "I_Left" 149 "I_LeftBusLane" 150 "I_LeftLine" 151 "I_LeftRight" 152 "I_LeftTurn" 153 "I_LeftTurnLane" 154 "I_MinSpeedLim100" 155 "I_MinSpeedLim110" 156 "I_MinSpeedLim40" 157 "I_MinSpeedLim50" 158 "I_MinSpeedLim60" 159 "I_MinSpeedLim70" 160 "I_MinSpeedLim80" 161 "I_MinSpeedLim90" 162 "I_Motors" 163 "I_MotorsLane" 164 "I_MultiOccupantMotorsLane" 165 "I_NonMotors" 166 "I_NonMotorsLane" 167 "I_Other_circle" 168 "I_Other_rectangle" 169 "I_ParkingSpace" 170 "I_Passingfirst" 171 "I_PedestrianCross" 172 "I_PriorityIntereesction" 173 "I_Right" 174 "I_RightLine" 175 "I_RightTurn" 176 "I_RightTurnLane" 177 "I_SplitDriveLine" 178 "I_StraightLine" 179 "I_UTurnAndLeftLane" 180 "I_UTurnLane" 181 "I_Unknown_circle" 182 "I_Unknown_rectangle" 183 "I_Uturn" 184 "I_Walk" 185 "MSL_Other" 186 "MSL_Unknown" 187 "MinSpeedLim100" 188 "MinSpeedLim110" 189 "MinSpeedLim50" 190 "MinSpeedLim60" 191 "MinSpeedLim70" 192 "MinSpeedLim80" 193 "MinSpeedLim90" 194 "NoPassingRev" 195 "O_Other" 196 "Other" 197 "Other_Construction_Sign" 198 "Other_Detfp" 199 "Other_Exit" 200 "Other_GuideSign_BlueWhite" 201 "Other_GuideSign_GreenWhite" 202 "Other_GuideSign_WhiteBlack" 203 "Other_Indications" 204 "Other_LightArrow" 205 "Other_Min_Speed" 206 "Other_Mirror" 207 "Other_NoParking" 208 "Other_Prohibit" 209 "Other_RedCircleLight" 210 "Other_RouteID_RedWhite" 211 "Other_RouteID_YellowBlack" 212 "Other_TravelSign_BrownWhite" 213 "Other_Warning" 214 "PR_Other" 215 "PR_Unknown" 216 "PSL_Other" 217 "PSL_Unknown" 218 "P_Custom" 219 "P_GiveWay" 220 "P_HeightLim" 221 "P_MultiVehicle" 222 "P_NoAnimalVehicle" 223 "P_NoBikeDownSlope" 224 "P_NoBikeUpSlope" 225 "P_NoBus" 226 "P_NoCar" 227 "P_NoCargoTricycle" 228 "P_NoDangerous" 229 "P_NoEntry" 230 "P_NoForward" 231 "P_NoForwardLeft" 232 "P_NoForwardRight" 233 "P_NoHorning" 234 "P_NoHuman" 235 "P_NoHumanCargoTriangle" 236 "P_NoHumanPassengerTriangle" 237 "P_NoHumanVehicle" 238 "P_NoLeftRightTurn" 239 "P_NoLeftTurn" 240 "P_NoLongParking" 241 "P_NoLongParkingRev" 242 "P_NoMinibus" 243 "P_NoMotoTricycle" 244 "P_NoMotor" 245 "P_NoMotorcycle" 246 "P_NoNonMotor" 247 "P_NoParking" 248 "P_NoParkingRev" 249 "P_NoPassing" 250 "P_NoPassingRev" 251 "P_NoReturn" 252 "P_NoRightTurn" 253 "P_NoSpecificLeftTurn" 254 "P_NoSpecificRightTurn" 255 "P_NoTractor" 256 "P_NoTrailer" 257 "P_NoTricycle" 258 "P_NoTruck" 259 "P_Noway" 260 "P_Other1" 261 "P_Other_SpeedLimele" 262 "P_ParkingCheck" 263 "P_SlowFor" 264 "P_SpeedLim10" 265 "P_SpeedLim100" 266 "P_SpeedLim100ele" 267 "P_SpeedLim105" 268 "P_SpeedLim110" 269 "P_SpeedLim110ele" 270 "P_SpeedLim115" 271 "P_SpeedLim120" 272 "P_SpeedLim120ele" 273 "P_SpeedLim15" 274 "P_SpeedLim20" 275 "P_SpeedLim20ele" 276 "P_SpeedLim25" 277 "P_SpeedLim30" 278 "P_SpeedLim30ele" 279 "P_SpeedLim35" 280 "P_SpeedLim40" 281 "P_SpeedLim40ele" 282 "P_SpeedLim45" 283 "P_SpeedLim5" 284 "P_SpeedLim50" 285 "P_SpeedLim50ele" 286 "P_SpeedLim55" 287 "P_SpeedLim60" 288 "P_SpeedLim60ele" 289 "P_SpeedLim65" 290 "P_SpeedLim70" 291 "P_SpeedLim70ele" 292 "P_SpeedLim75" 293 "P_SpeedLim80" 294 "P_SpeedLim80ele" 295 "P_SpeedLim85" 296 "P_SpeedLim90" 297 "P_SpeedLim90ele" 298 "P_SpeedLim95" 299 "P_SpeedLimRev" 300 "P_SpeedLimRev10" 301 "P_SpeedLimRev100" 302 "P_SpeedLimRev105" 303 "P_SpeedLimRev110" 304 "P_SpeedLimRev115" 305 "P_SpeedLimRev120" 306 "P_SpeedLimRev15" 307 "P_SpeedLimRev20" 308 "P_SpeedLimRev25" 309 "P_SpeedLimRev30" 310 "P_SpeedLimRev35" 311 "P_SpeedLimRev40" 312 "P_SpeedLimRev45" 313 "P_SpeedLimRev5" 314 "P_SpeedLimRev50" 315 "P_SpeedLimRev55" 316 "P_SpeedLimRev60" 317 "P_SpeedLimRev65" 318 "P_SpeedLimRev70" 319 "P_SpeedLimRev75" 320 "P_SpeedLimRev80" 321 "P_SpeedLimRev85" 322 "P_SpeedLimRev90" 323 "P_SpeedLimRev95" 324 "P_StopFor" 325 "P_Unknow_SpeedLimele" 326 "P_Unknown1" 327 "P_VehicleOther" 328 "P_WeightLim" 329 "P_WeightLimWheel" 330 "P_WidthLim" 331 "RSBW_Misc" 332 "RSBW_Other" 333 "RSBW_Unknown" 334 "R_CircularIntersection" 335 "R_RoadSign_BlueWhite" 336 "RouteID_HighwayMark" 337 "RouteID_Other" 338 "RouteID_RedWhite" 339 "RouteID_TownRoadMark" 340 "RouteID_Unknown" 341 "RouteID_YellowBlack" 342 "SpeedLim10" 343 "SpeedLim100" 344 "SpeedLim100_electric" 345 "SpeedLim110" 346 "SpeedLim110_electric" 347 "SpeedLim120" 348 "SpeedLim120_electric" 349 "SpeedLim15" 350 "SpeedLim20" 351 "SpeedLim25" 352 "SpeedLim30" 353 "SpeedLim30_electric" 354 "SpeedLim35" 355 "SpeedLim40" 356 "SpeedLim40_electric" 357 "SpeedLim5" 358 "SpeedLim50" 359 "SpeedLim50_electric" 360 "SpeedLim55" 361 "SpeedLim5_electric" 362 "SpeedLim60" 363 "SpeedLim60_electric" 364 "SpeedLim65" 365 "SpeedLim70" 366 "SpeedLim70_electric" 367 "SpeedLim80" 368 "SpeedLim80_electric" 369 "SpeedLim90" 370 "SpeedLim90_electric" 371 "SpeedLimRev" 372 "TSBW_Other" 373 "TSBW_Unknown" 374 "T_TravelSign_BrownWhite" 375 "U_Unknown" 376 "W_AccidentProne" 377 "W_Animal" 378 "W_BadWeather" 379 "W_Bump" 380 "W_Bumpy" 381 "W_Children" 382 "W_Circle" 383 "W_ContinuousDown" 384 "W_ContinuousTurn" 385 "W_Cross" 386 "W_CrossIntersection" 387 "W_CrossLaneRail" 388 "W_Cycle" 389 "W_DamLeft" 390 "W_DamRight" 391 "W_Danger" 392 "W_DetourAround" 393 "W_DetourLeft" 394 "W_DetourRight" 395 "W_Disabled" 396 "W_Domestic" 397 "W_Down" 398 "W_EmergencyLane" 399 "W_Ferry" 400 "W_Fog" 401 "W_Ford" 402 "W_GuardedRailway" 403 "W_HumpBridge" 404 "W_Ice" 405 "W_KeepDistance" 406 "W_LRNarrow" 407 "W_LRTurn" 408 "W_LeftFalling" 409 "W_LeftNarrow" 410 "W_LeftTurn" 411 "W_LowLying" 412 "W_MergeLeft" 413 "W_MergeRight" 414 "W_MountLeft" 415 "W_MountRight" 416 "W_NarrowBridge" 417 "W_Other" 418 "W_Pedestrian" 419 "W_RLTurn" 420 "W_Railway" 421 "W_Rain" 422 "W_RightFalling" 423 "W_RightNarrow" 424 "W_RightTurn" 425 "W_SideWind" 426 "W_Side_Wind" 427 "W_Slash" 428 "W_Slip" 429 "W_Slow" 430 "W_SlowDown" 431 "W_SplitLeft" 432 "W_SplitRight" 433 "W_TIntersection" 434 "W_TShap" 435 "W_TShapLeft" 436 "W_TShapRight" 437 "W_Tidal" 438 "W_TrafficLight" 439 "W_Tripod" 440 "W_Tshape" 441 "W_Tshaps" 442 "W_Tunnel" 443 "W_TunnelHeadlight" 444 "W_TwoWay" 445 "W_Unknown" 446 "W_Up" 447 "W_VehicleQueue" 448 "W_Village" 449 "W_Working" 450 "W_YBLeft" 451 "W_YBRight" 452 "W_YB_Left" 453 "W_YB_Right" 454 "W_YLeft" 455 "W_YRight" 456 "W_Y_Left" 457 "W_Y_Right" 458 "sign_back" 459 "Other_IndicationsCircle" 460 "Other_IndicationsRectangle" 461 "Other_Circular_Marker" 462 "False_Positive" 463 "FP_Light_Time" 464 "RouteSign_Misc" 465 "Multi_Misc";
VAL_ 1321 TSR_Relevancy_529h 0 "Undefined" 1 "IN_HOSTLANE_SIGN" 2 "NOT_IN_HOSTLANE" 3 "HIGHWAY_EXIT_SIGN (Reserved)" 4 "SIGN_ON_TURN (Reserved)" 5 "FAR_IRRELEVANT_SIGN (Reserved)";
VAL_ 1321 TSR_Filter_Type_529h 0 "Not filtered" 1 "Irrelevant to the host driver" 2 "On vehicle/truck" 3 "Embedded(Reserved)" 4 "RESERVED" 5 "RESERVED" 6 "RESERVED" 7 "RESERVED";
VAL_ 1321 TSR_Approved_Flag_529h 0 "Not Approved" 1 "Approved";
VAL_ 1323 TSRTrafficSignType_52Bh 0 "C_Other" 1 "C_Unknown" 2 "Construction" 3 "FP_Accessory_Arrow" 4 "FP_Building" 5 "FP_Circular_Marker" 6 "FP_Head" 7 "FP_Light_Arrow" 8 "FP_Light_Circle" 9 "FP_Light_Shell" 10 "FP_Mirror" 11 "FP_Other" 12 "FP_Polygon_Marker" 13 "FP_Route_Number" 14 "FP_Twig" 15 "FP_Unknown" 16 "FP_Vehicle_Wheel" 17 "GSGW_Misc" 18 "GSGW_Other" 19 "GSGW_Unknown" 20 "GSWB_Misc" 21 "GSWB_Other" 22 "GSWB_Unknown" 23 "G_GuideSign_GreenWhite" 24 "G_GuideSign_WhiteBlack" 25 "GuideSign_MultiMisc" 26 "IR_AccidentPronePoint" 27 "IR_Accommodation" 28 "IR_AdministrativeBoundary" 29 "IR_Airport" 30 "IR_Area" 31 "IR_AvoidLine" 32 "IR_BifurcationMark" 33 "IR_BigCarRight" 34 "IR_Blocked" 35 "IR_BusStation" 36 "IR_CarRepair" 37 "IR_CarWash" 38 "IR_CateringServices" 39 "IR_CombinationAuxiliary" 40 "IR_ContinuousDownhill" 41 "IR_CountryRoadNumMark" 42 "IR_CrossIntersection" 43 "IR_CrossingMarking" 44 "IR_DisabledSpecial" 45 "IR_DistanceArea" 46 "IR_Drink" 47 "IR_DrivingDirection" 48 "IR_ETCLanes" 49 "IR_ElectricalETC" 50 "IR_EmergencyShelter" 51 "IR_FamousPlaceName" 52 "IR_Ferry" 53 "IR_FerryPier" 54 "IR_FirstAidStation" 55 "IR_Foggy" 56 "IR_FootBridge" 57 "IR_GasStation" 58 "IR_HighwayCarDistanceConfirmation" 59 "IR_HighwayClimbingLine" 60 "IR_HighwayDirection" 61 "IR_HighwayETCLanes" 62 "IR_HighwayETCTollStationsNotice" 63 "IR_HighwayEmergencyParkingBelt" 64 "IR_HighwayEmergencyPhone" 65 "IR_HighwayEnd" 66 "IR_HighwayEndNotice" 67 "IR_HighwayEntrance" 68 "IR_HighwayEntranceNotice" 69 "IR_HighwayExit" 70 "IR_HighwayExitNotice" 71 "IR_HighwayGasStation" 72 "IR_HighwayHundredCard" 73 "IR_HighwayLocationDirection" 74 "IR_HighwayLocationDistance" 75 "IR_HighwayMileageCard" 76 "IR_HighwayName" 77 "IR_HighwayNextExitNotice" 78 "IR_HighwayOverloadCheck" 79 "IR_HighwayParkinAreaNotice" 80 "IR_HighwayParkingLotNotice" 81 "IR_HighwayRescueCall" 82 "IR_HighwayRoadTrafficInformation" 83 "IR_HighwayServiceNotice" 84 "IR_HighwaySlowDown" 85 "IR_HighwayStart" 86 "IR_HighwayTicket" 87 "IR_HighwayTollStationsNotice" 88 "IR_Interchange" 89 "IR_IntersectionNotice" 90 "IR_LanesDecrease" 91 "IR_LanesIncrease" 92 "IR_Linearguide" 93 "IR_LocationDistance" 94 "IR_LongDistanceBusStation" 95 "IR_MilePost" 96 "IR_MobileConstruction" 97 "IR_Nameplate" 98 "IR_Parking" 99 "IR_ParkingLot" 100 "IR_PassingTime" 101 "IR_PedestrianTunnel" 102 "IR_PedestrianUnderpass" 103 "IR_PlaceName" 104 "IR_Police" 105 "IR_Port" 106 "IR_ProtectAnimals" 107 "IR_Quarantine" 108 "IR_RailwayStation" 109 "IR_Ramp" 110 "IR_RampArrow" 111 "IR_RestArea" 112 "IR_RoadManageBoundary" 113 "IR_RoadStop" 114 "IR_SlowRoad" 115 "IR_Snack" 116 "IR_SoftFoundation" 117 "IR_SteepSlope" 118 "IR_StreetName" 119 "IR_SubwayStation" 120 "IR_Taxi" 121 "IR_Tcorssing" 122 "IR_TouristAreaDirectionDistance" 123 "IR_TrafficSupervisory" 124 "IR_TransferCenter" 125 "IR_TransverseWind" 126 "IR_TravelSymbols" 127 "IR_Tunnel" 128 "IR_TunnelNextExitNotice" 129 "IR_VehicleType" 130 "IR_ViewingPoint" 131 "IR_WarningReason" 132 "IR_WeightCharge" 133 "IR_Ycorssing" 134 "IR_Zones" 135 "IR_ZonesII" 136 "I_AllowUturn" 137 "I_Circle" 138 "I_FastBusLane" 139 "I_Forward" 140 "I_ForwardLane" 141 "I_ForwardLeft" 142 "I_ForwardLeftLane" 143 "I_ForwardLeftStereo" 144 "I_ForwardRight" 145 "I_ForwardRightLane" 146 "I_ForwardRightStereo" 147 "I_Honk" 148 "I_Left" 149 "I_LeftBusLane" 150 "I_LeftLine" 151 "I_LeftRight" 152 "I_LeftTurn" 153 "I_LeftTurnLane" 154 "I_MinSpeedLim100" 155 "I_MinSpeedLim110" 156 "I_MinSpeedLim40" 157 "I_MinSpeedLim50" 158 "I_MinSpeedLim60" 159 "I_MinSpeedLim70" 160 "I_MinSpeedLim80" 161 "I_MinSpeedLim90" 162 "I_Motors" 163 "I_MotorsLane" 164 "I_MultiOccupantMotorsLane" 165 "I_NonMotors" 166 "I_NonMotorsLane" 167 "I_Other_circle" 168 "I_Other_rectangle" 169 "I_ParkingSpace" 170 "I_Passingfirst" 171 "I_PedestrianCross" 172 "I_PriorityIntereesction" 173 "I_Right" 174 "I_RightLine" 175 "I_RightTurn" 176 "I_RightTurnLane" 177 "I_SplitDriveLine" 178 "I_StraightLine" 179 "I_UTurnAndLeftLane" 180 "I_UTurnLane" 181 "I_Unknown_circle" 182 "I_Unknown_rectangle" 183 "I_Uturn" 184 "I_Walk" 185 "MSL_Other" 186 "MSL_Unknown" 187 "MinSpeedLim100" 188 "MinSpeedLim110" 189 "MinSpeedLim50" 190 "MinSpeedLim60" 191 "MinSpeedLim70" 192 "MinSpeedLim80" 193 "MinSpeedLim90" 194 "NoPassingRev" 195 "O_Other" 196 "Other" 197 "Other_Construction_Sign" 198 "Other_Detfp" 199 "Other_Exit" 200 "Other_GuideSign_BlueWhite" 201 "Other_GuideSign_GreenWhite" 202 "Other_GuideSign_WhiteBlack" 203 "Other_Indications" 204 "Other_LightArrow" 205 "Other_Min_Speed" 206 "Other_Mirror" 207 "Other_NoParking" 208 "Other_Prohibit" 209 "Other_RedCircleLight" 210 "Other_RouteID_RedWhite" 211 "Other_RouteID_YellowBlack" 212 "Other_TravelSign_BrownWhite" 213 "Other_Warning" 214 "PR_Other" 215 "PR_Unknown" 216 "PSL_Other" 217 "PSL_Unknown" 218 "P_Custom" 219 "P_GiveWay" 220 "P_HeightLim" 221 "P_MultiVehicle" 222 "P_NoAnimalVehicle" 223 "P_NoBikeDownSlope" 224 "P_NoBikeUpSlope" 225 "P_NoBus" 226 "P_NoCar" 227 "P_NoCargoTricycle" 228 "P_NoDangerous" 229 "P_NoEntry" 230 "P_NoForward" 231 "P_NoForwardLeft" 232 "P_NoForwardRight" 233 "P_NoHorning" 234 "P_NoHuman" 235 "P_NoHumanCargoTriangle" 236 "P_NoHumanPassengerTriangle" 237 "P_NoHumanVehicle" 238 "P_NoLeftRightTurn" 239 "P_NoLeftTurn" 240 "P_NoLongParking" 241 "P_NoLongParkingRev" 242 "P_NoMinibus" 243 "P_NoMotoTricycle" 244 "P_NoMotor" 245 "P_NoMotorcycle" 246 "P_NoNonMotor" 247 "P_NoParking" 248 "P_NoParkingRev" 249 "P_NoPassing" 250 "P_NoPassingRev" 251 "P_NoReturn" 252 "P_NoRightTurn" 253 "P_NoSpecificLeftTurn" 254 "P_NoSpecificRightTurn" 255 "P_NoTractor" 256 "P_NoTrailer" 257 "P_NoTricycle" 258 "P_NoTruck" 259 "P_Noway" 260 "P_Other1" 261 "P_Other_SpeedLimele" 262 "P_ParkingCheck" 263 "P_SlowFor" 264 "P_SpeedLim10" 265 "P_SpeedLim100" 266 "P_SpeedLim100ele" 267 "P_SpeedLim105" 268 "P_SpeedLim110" 269 "P_SpeedLim110ele" 270 "P_SpeedLim115" 271 "P_SpeedLim120" 272 "P_SpeedLim120ele" 273 "P_SpeedLim15" 274 "P_SpeedLim20" 275 "P_SpeedLim20ele" 276 "P_SpeedLim25" 277 "P_SpeedLim30" 278 "P_SpeedLim30ele" 279 "P_SpeedLim35" 280 "P_SpeedLim40" 281 "P_SpeedLim40ele" 282 "P_SpeedLim45" 283 "P_SpeedLim5" 284 "P_SpeedLim50" 285 "P_SpeedLim50ele" 286 "P_SpeedLim55" 287 "P_SpeedLim60" 288 "P_SpeedLim60ele" 289 "P_SpeedLim65" 290 "P_SpeedLim70" 291 "P_SpeedLim70ele" 292 "P_SpeedLim75" 293 "P_SpeedLim80" 294 "P_SpeedLim80ele" 295 "P_SpeedLim85" 296 "P_SpeedLim90" 297 "P_SpeedLim90ele" 298 "P_SpeedLim95" 299 "P_SpeedLimRev" 300 "P_SpeedLimRev10" 301 "P_SpeedLimRev100" 302 "P_SpeedLimRev105" 303 "P_SpeedLimRev110" 304 "P_SpeedLimRev115" 305 "P_SpeedLimRev120" 306 "P_SpeedLimRev15" 307 "P_SpeedLimRev20" 308 "P_SpeedLimRev25" 309 "P_SpeedLimRev30" 310 "P_SpeedLimRev35" 311 "P_SpeedLimRev40" 312 "P_SpeedLimRev45" 313 "P_SpeedLimRev5" 314 "P_SpeedLimRev50" 315 "P_SpeedLimRev55" 316 "P_SpeedLimRev60" 317 "P_SpeedLimRev65" 318 "P_SpeedLimRev70" 319 "P_SpeedLimRev75" 320 "P_SpeedLimRev80" 321 "P_SpeedLimRev85" 322 "P_SpeedLimRev90" 323 "P_SpeedLimRev95" 324 "P_StopFor" 325 "P_Unknow_SpeedLimele" 326 "P_Unknown1" 327 "P_VehicleOther" 328 "P_WeightLim" 329 "P_WeightLimWheel" 330 "P_WidthLim" 331 "RSBW_Misc" 332 "RSBW_Other" 333 "RSBW_Unknown" 334 "R_CircularIntersection" 335 "R_RoadSign_BlueWhite" 336 "RouteID_HighwayMark" 337 "RouteID_Other" 338 "RouteID_RedWhite" 339 "RouteID_TownRoadMark" 340 "RouteID_Unknown" 341 "RouteID_YellowBlack" 342 "SpeedLim10" 343 "SpeedLim100" 344 "SpeedLim100_electric" 345 "SpeedLim110" 346 "SpeedLim110_electric" 347 "SpeedLim120" 348 "SpeedLim120_electric" 349 "SpeedLim15" 350 "SpeedLim20" 351 "SpeedLim25" 352 "SpeedLim30" 353 "SpeedLim30_electric" 354 "SpeedLim35" 355 "SpeedLim40" 356 "SpeedLim40_electric" 357 "SpeedLim5" 358 "SpeedLim50" 359 "SpeedLim50_electric" 360 "SpeedLim55" 361 "SpeedLim5_electric" 362 "SpeedLim60" 363 "SpeedLim60_electric" 364 "SpeedLim65" 365 "SpeedLim70" 366 "SpeedLim70_electric" 367 "SpeedLim80" 368 "SpeedLim80_electric" 369 "SpeedLim90" 370 "SpeedLim90_electric" 371 "SpeedLimRev" 372 "TSBW_Other" 373 "TSBW_Unknown" 374 "T_TravelSign_BrownWhite" 375 "U_Unknown" 376 "W_AccidentProne" 377 "W_Animal" 378 "W_BadWeather" 379 "W_Bump" 380 "W_Bumpy" 381 "W_Children" 382 "W_Circle" 383 "W_ContinuousDown" 384 "W_ContinuousTurn" 385 "W_Cross" 386 "W_CrossIntersection" 387 "W_CrossLaneRail" 388 "W_Cycle" 389 "W_DamLeft" 390 "W_DamRight" 391 "W_Danger" 392 "W_DetourAround" 393 "W_DetourLeft" 394 "W_DetourRight" 395 "W_Disabled" 396 "W_Domestic" 397 "W_Down" 398 "W_EmergencyLane" 399 "W_Ferry" 400 "W_Fog" 401 "W_Ford" 402 "W_GuardedRailway" 403 "W_HumpBridge" 404 "W_Ice" 405 "W_KeepDistance" 406 "W_LRNarrow" 407 "W_LRTurn" 408 "W_LeftFalling" 409 "W_LeftNarrow" 410 "W_LeftTurn" 411 "W_LowLying" 412 "W_MergeLeft" 413 "W_MergeRight" 414 "W_MountLeft" 415 "W_MountRight" 416 "W_NarrowBridge" 417 "W_Other" 418 "W_Pedestrian" 419 "W_RLTurn" 420 "W_Railway" 421 "W_Rain" 422 "W_RightFalling" 423 "W_RightNarrow" 424 "W_RightTurn" 425 "W_SideWind" 426 "W_Side_Wind" 427 "W_Slash" 428 "W_Slip" 429 "W_Slow" 430 "W_SlowDown" 431 "W_SplitLeft" 432 "W_SplitRight" 433 "W_TIntersection" 434 "W_TShap" 435 "W_TShapLeft" 436 "W_TShapRight" 437 "W_Tidal" 438 "W_TrafficLight" 439 "W_Tripod" 440 "W_Tshape" 441 "W_Tshaps" 442 "W_Tunnel" 443 "W_TunnelHeadlight" 444 "W_TwoWay" 445 "W_Unknown" 446 "W_Up" 447 "W_VehicleQueue" 448 "W_Village" 449 "W_Working" 450 "W_YBLeft" 451 "W_YBRight" 452 "W_YB_Left" 453 "W_YB_Right" 454 "W_YLeft" 455 "W_YRight" 456 "W_Y_Left" 457 "W_Y_Right" 458 "sign_back" 459 "Other_IndicationsCircle" 460 "Other_IndicationsRectangle" 461 "Other_Circular_Marker" 462 "False_Positive" 463 "FP_Light_Time" 464 "RouteSign_Misc" 465 "Multi_Misc";
VAL_ 1323 TSR_Relevancy_52Bh 0 "Undefined" 1 "IN_HOSTLANE_SIGN" 2 "NOT_IN_HOSTLANE" 3 "HIGHWAY_EXIT_SIGN (Reserved)" 4 "SIGN_ON_TURN (Reserved)" 5 "FAR_IRRELEVANT_SIGN (Reserved)";
VAL_ 1323 TSR_Filter_Type_52Bh 0 "Not filtered" 1 "Irrelevant to the host driver" 2 "On vehicle/truck" 3 "Embedded(Reserved)" 4 "RESERVED" 5 "RESERVED" 6 "RESERVED" 7 "RESERVED";
VAL_ 1323 TSR_Approved_Flag_52Bh 0 "Not Approved" 1 "Approved";
VAL_ 1325 TSRTrafficSignType_52Dh 0 "C_Other" 1 "C_Unknown" 2 "Construction" 3 "FP_Accessory_Arrow" 4 "FP_Building" 5 "FP_Circular_Marker" 6 "FP_Head" 7 "FP_Light_Arrow" 8 "FP_Light_Circle" 9 "FP_Light_Shell" 10 "FP_Mirror" 11 "FP_Other" 12 "FP_Polygon_Marker" 13 "FP_Route_Number" 14 "FP_Twig" 15 "FP_Unknown" 16 "FP_Vehicle_Wheel" 17 "GSGW_Misc" 18 "GSGW_Other" 19 "GSGW_Unknown" 20 "GSWB_Misc" 21 "GSWB_Other" 22 "GSWB_Unknown" 23 "G_GuideSign_GreenWhite" 24 "G_GuideSign_WhiteBlack" 25 "GuideSign_MultiMisc" 26 "IR_AccidentPronePoint" 27 "IR_Accommodation" 28 "IR_AdministrativeBoundary" 29 "IR_Airport" 30 "IR_Area" 31 "IR_AvoidLine" 32 "IR_BifurcationMark" 33 "IR_BigCarRight" 34 "IR_Blocked" 35 "IR_BusStation" 36 "IR_CarRepair" 37 "IR_CarWash" 38 "IR_CateringServices" 39 "IR_CombinationAuxiliary" 40 "IR_ContinuousDownhill" 41 "IR_CountryRoadNumMark" 42 "IR_CrossIntersection" 43 "IR_CrossingMarking" 44 "IR_DisabledSpecial" 45 "IR_DistanceArea" 46 "IR_Drink" 47 "IR_DrivingDirection" 48 "IR_ETCLanes" 49 "IR_ElectricalETC" 50 "IR_EmergencyShelter" 51 "IR_FamousPlaceName" 52 "IR_Ferry" 53 "IR_FerryPier" 54 "IR_FirstAidStation" 55 "IR_Foggy" 56 "IR_FootBridge" 57 "IR_GasStation" 58 "IR_HighwayCarDistanceConfirmation" 59 "IR_HighwayClimbingLine" 60 "IR_HighwayDirection" 61 "IR_HighwayETCLanes" 62 "IR_HighwayETCTollStationsNotice" 63 "IR_HighwayEmergencyParkingBelt" 64 "IR_HighwayEmergencyPhone" 65 "IR_HighwayEnd" 66 "IR_HighwayEndNotice" 67 "IR_HighwayEntrance" 68 "IR_HighwayEntranceNotice" 69 "IR_HighwayExit" 70 "IR_HighwayExitNotice" 71 "IR_HighwayGasStation" 72 "IR_HighwayHundredCard" 73 "IR_HighwayLocationDirection" 74 "IR_HighwayLocationDistance" 75 "IR_HighwayMileageCard" 76 "IR_HighwayName" 77 "IR_HighwayNextExitNotice" 78 "IR_HighwayOverloadCheck" 79 "IR_HighwayParkinAreaNotice" 80 "IR_HighwayParkingLotNotice" 81 "IR_HighwayRescueCall" 82 "IR_HighwayRoadTrafficInformation" 83 "IR_HighwayServiceNotice" 84 "IR_HighwaySlowDown" 85 "IR_HighwayStart" 86 "IR_HighwayTicket" 87 "IR_HighwayTollStationsNotice" 88 "IR_Interchange" 89 "IR_IntersectionNotice" 90 "IR_LanesDecrease" 91 "IR_LanesIncrease" 92 "IR_Linearguide" 93 "IR_LocationDistance" 94 "IR_LongDistanceBusStation" 95 "IR_MilePost" 96 "IR_MobileConstruction" 97 "IR_Nameplate" 98 "IR_Parking" 99 "IR_ParkingLot" 100 "IR_PassingTime" 101 "IR_PedestrianTunnel" 102 "IR_PedestrianUnderpass" 103 "IR_PlaceName" 104 "IR_Police" 105 "IR_Port" 106 "IR_ProtectAnimals" 107 "IR_Quarantine" 108 "IR_RailwayStation" 109 "IR_Ramp" 110 "IR_RampArrow" 111 "IR_RestArea" 112 "IR_RoadManageBoundary" 113 "IR_RoadStop" 114 "IR_SlowRoad" 115 "IR_Snack" 116 "IR_SoftFoundation" 117 "IR_SteepSlope" 118 "IR_StreetName" 119 "IR_SubwayStation" 120 "IR_Taxi" 121 "IR_Tcorssing" 122 "IR_TouristAreaDirectionDistance" 123 "IR_TrafficSupervisory" 124 "IR_TransferCenter" 125 "IR_TransverseWind" 126 "IR_TravelSymbols" 127 "IR_Tunnel" 128 "IR_TunnelNextExitNotice" 129 "IR_VehicleType" 130 "IR_ViewingPoint" 131 "IR_WarningReason" 132 "IR_WeightCharge" 133 "IR_Ycorssing" 134 "IR_Zones" 135 "IR_ZonesII" 136 "I_AllowUturn" 137 "I_Circle" 138 "I_FastBusLane" 139 "I_Forward" 140 "I_ForwardLane" 141 "I_ForwardLeft" 142 "I_ForwardLeftLane" 143 "I_ForwardLeftStereo" 144 "I_ForwardRight" 145 "I_ForwardRightLane" 146 "I_ForwardRightStereo" 147 "I_Honk" 148 "I_Left" 149 "I_LeftBusLane" 150 "I_LeftLine" 151 "I_LeftRight" 152 "I_LeftTurn" 153 "I_LeftTurnLane" 154 "I_MinSpeedLim100" 155 "I_MinSpeedLim110" 156 "I_MinSpeedLim40" 157 "I_MinSpeedLim50" 158 "I_MinSpeedLim60" 159 "I_MinSpeedLim70" 160 "I_MinSpeedLim80" 161 "I_MinSpeedLim90" 162 "I_Motors" 163 "I_MotorsLane" 164 "I_MultiOccupantMotorsLane" 165 "I_NonMotors" 166 "I_NonMotorsLane" 167 "I_Other_circle" 168 "I_Other_rectangle" 169 "I_ParkingSpace" 170 "I_Passingfirst" 171 "I_PedestrianCross" 172 "I_PriorityIntereesction" 173 "I_Right" 174 "I_RightLine" 175 "I_RightTurn" 176 "I_RightTurnLane" 177 "I_SplitDriveLine" 178 "I_StraightLine" 179 "I_UTurnAndLeftLane" 180 "I_UTurnLane" 181 "I_Unknown_circle" 182 "I_Unknown_rectangle" 183 "I_Uturn" 184 "I_Walk" 185 "MSL_Other" 186 "MSL_Unknown" 187 "MinSpeedLim100" 188 "MinSpeedLim110" 189 "MinSpeedLim50" 190 "MinSpeedLim60" 191 "MinSpeedLim70" 192 "MinSpeedLim80" 193 "MinSpeedLim90" 194 "NoPassingRev" 195 "O_Other" 196 "Other" 197 "Other_Construction_Sign" 198 "Other_Detfp" 199 "Other_Exit" 200 "Other_GuideSign_BlueWhite" 201 "Other_GuideSign_GreenWhite" 202 "Other_GuideSign_WhiteBlack" 203 "Other_Indications" 204 "Other_LightArrow" 205 "Other_Min_Speed" 206 "Other_Mirror" 207 "Other_NoParking" 208 "Other_Prohibit" 209 "Other_RedCircleLight" 210 "Other_RouteID_RedWhite" 211 "Other_RouteID_YellowBlack" 212 "Other_TravelSign_BrownWhite" 213 "Other_Warning" 214 "PR_Other" 215 "PR_Unknown" 216 "PSL_Other" 217 "PSL_Unknown" 218 "P_Custom" 219 "P_GiveWay" 220 "P_HeightLim" 221 "P_MultiVehicle" 222 "P_NoAnimalVehicle" 223 "P_NoBikeDownSlope" 224 "P_NoBikeUpSlope" 225 "P_NoBus" 226 "P_NoCar" 227 "P_NoCargoTricycle" 228 "P_NoDangerous" 229 "P_NoEntry" 230 "P_NoForward" 231 "P_NoForwardLeft" 232 "P_NoForwardRight" 233 "P_NoHorning" 234 "P_NoHuman" 235 "P_NoHumanCargoTriangle" 236 "P_NoHumanPassengerTriangle" 237 "P_NoHumanVehicle" 238 "P_NoLeftRightTurn" 239 "P_NoLeftTurn" 240 "P_NoLongParking" 241 "P_NoLongParkingRev" 242 "P_NoMinibus" 243 "P_NoMotoTricycle" 244 "P_NoMotor" 245 "P_NoMotorcycle" 246 "P_NoNonMotor" 247 "P_NoParking" 248 "P_NoParkingRev" 249 "P_NoPassing" 250 "P_NoPassingRev" 251 "P_NoReturn" 252 "P_NoRightTurn" 253 "P_NoSpecificLeftTurn" 254 "P_NoSpecificRightTurn" 255 "P_NoTractor" 256 "P_NoTrailer" 257 "P_NoTricycle" 258 "P_NoTruck" 259 "P_Noway" 260 "P_Other1" 261 "P_Other_SpeedLimele" 262 "P_ParkingCheck" 263 "P_SlowFor" 264 "P_SpeedLim10" 265 "P_SpeedLim100" 266 "P_SpeedLim100ele" 267 "P_SpeedLim105" 268 "P_SpeedLim110" 269 "P_SpeedLim110ele" 270 "P_SpeedLim115" 271 "P_SpeedLim120" 272 "P_SpeedLim120ele" 273 "P_SpeedLim15" 274 "P_SpeedLim20" 275 "P_SpeedLim20ele" 276 "P_SpeedLim25" 277 "P_SpeedLim30" 278 "P_SpeedLim30ele" 279 "P_SpeedLim35" 280 "P_SpeedLim40" 281 "P_SpeedLim40ele" 282 "P_SpeedLim45" 283 "P_SpeedLim5" 284 "P_SpeedLim50" 285 "P_SpeedLim50ele" 286 "P_SpeedLim55" 287 "P_SpeedLim60" 288 "P_SpeedLim60ele" 289 "P_SpeedLim65" 290 "P_SpeedLim70" 291 "P_SpeedLim70ele" 292 "P_SpeedLim75" 293 "P_SpeedLim80" 294 "P_SpeedLim80ele" 295 "P_SpeedLim85" 296 "P_SpeedLim90" 297 "P_SpeedLim90ele" 298 "P_SpeedLim95" 299 "P_SpeedLimRev" 300 "P_SpeedLimRev10" 301 "P_SpeedLimRev100" 302 "P_SpeedLimRev105" 303 "P_SpeedLimRev110" 304 "P_SpeedLimRev115" 305 "P_SpeedLimRev120" 306 "P_SpeedLimRev15" 307 "P_SpeedLimRev20" 308 "P_SpeedLimRev25" 309 "P_SpeedLimRev30" 310 "P_SpeedLimRev35" 311 "P_SpeedLimRev40" 312 "P_SpeedLimRev45" 313 "P_SpeedLimRev5" 314 "P_SpeedLimRev50" 315 "P_SpeedLimRev55" 316 "P_SpeedLimRev60" 317 "P_SpeedLimRev65" 318 "P_SpeedLimRev70" 319 "P_SpeedLimRev75" 320 "P_SpeedLimRev80" 321 "P_SpeedLimRev85" 322 "P_SpeedLimRev90" 323 "P_SpeedLimRev95" 324 "P_StopFor" 325 "P_Unknow_SpeedLimele" 326 "P_Unknown1" 327 "P_VehicleOther" 328 "P_WeightLim" 329 "P_WeightLimWheel" 330 "P_WidthLim" 331 "RSBW_Misc" 332 "RSBW_Other" 333 "RSBW_Unknown" 334 "R_CircularIntersection" 335 "R_RoadSign_BlueWhite" 336 "RouteID_HighwayMark" 337 "RouteID_Other" 338 "RouteID_RedWhite" 339 "RouteID_TownRoadMark" 340 "RouteID_Unknown" 341 "RouteID_YellowBlack" 342 "SpeedLim10" 343 "SpeedLim100" 344 "SpeedLim100_electric" 345 "SpeedLim110" 346 "SpeedLim110_electric" 347 "SpeedLim120" 348 "SpeedLim120_electric" 349 "SpeedLim15" 350 "SpeedLim20" 351 "SpeedLim25" 352 "SpeedLim30" 353 "SpeedLim30_electric" 354 "SpeedLim35" 355 "SpeedLim40" 356 "SpeedLim40_electric" 357 "SpeedLim5" 358 "SpeedLim50" 359 "SpeedLim50_electric" 360 "SpeedLim55" 361 "SpeedLim5_electric" 362 "SpeedLim60" 363 "SpeedLim60_electric" 364 "SpeedLim65" 365 "SpeedLim70" 366 "SpeedLim70_electric" 367 "SpeedLim80" 368 "SpeedLim80_electric" 369 "SpeedLim90" 370 "SpeedLim90_electric" 371 "SpeedLimRev" 372 "TSBW_Other" 373 "TSBW_Unknown" 374 "T_TravelSign_BrownWhite" 375 "U_Unknown" 376 "W_AccidentProne" 377 "W_Animal" 378 "W_BadWeather" 379 "W_Bump" 380 "W_Bumpy" 381 "W_Children" 382 "W_Circle" 383 "W_ContinuousDown" 384 "W_ContinuousTurn" 385 "W_Cross" 386 "W_CrossIntersection" 387 "W_CrossLaneRail" 388 "W_Cycle" 389 "W_DamLeft" 390 "W_DamRight" 391 "W_Danger" 392 "W_DetourAround" 393 "W_DetourLeft" 394 "W_DetourRight" 395 "W_Disabled" 396 "W_Domestic" 397 "W_Down" 398 "W_EmergencyLane" 399 "W_Ferry" 400 "W_Fog" 401 "W_Ford" 402 "W_GuardedRailway" 403 "W_HumpBridge" 404 "W_Ice" 405 "W_KeepDistance" 406 "W_LRNarrow" 407 "W_LRTurn" 408 "W_LeftFalling" 409 "W_LeftNarrow" 410 "W_LeftTurn" 411 "W_LowLying" 412 "W_MergeLeft" 413 "W_MergeRight" 414 "W_MountLeft" 415 "W_MountRight" 416 "W_NarrowBridge" 417 "W_Other" 418 "W_Pedestrian" 419 "W_RLTurn" 420 "W_Railway" 421 "W_Rain" 422 "W_RightFalling" 423 "W_RightNarrow" 424 "W_RightTurn" 425 "W_SideWind" 426 "W_Side_Wind" 427 "W_Slash" 428 "W_Slip" 429 "W_Slow" 430 "W_SlowDown" 431 "W_SplitLeft" 432 "W_SplitRight" 433 "W_TIntersection" 434 "W_TShap" 435 "W_TShapLeft" 436 "W_TShapRight" 437 "W_Tidal" 438 "W_TrafficLight" 439 "W_Tripod" 440 "W_Tshape" 441 "W_Tshaps" 442 "W_Tunnel" 443 "W_TunnelHeadlight" 444 "W_TwoWay" 445 "W_Unknown" 446 "W_Up" 447 "W_VehicleQueue" 448 "W_Village" 449 "W_Working" 450 "W_YBLeft" 451 "W_YBRight" 452 "W_YB_Left" 453 "W_YB_Right" 454 "W_YLeft" 455 "W_YRight" 456 "W_Y_Left" 457 "W_Y_Right" 458 "sign_back" 459 "Other_IndicationsCircle" 460 "Other_IndicationsRectangle" 461 "Other_Circular_Marker" 462 "False_Positive" 463 "FP_Light_Time" 464 "RouteSign_Misc" 465 "Multi_Misc";
VAL_ 1325 TSR_Relevancy_52Dh 0 "Undefined" 1 "IN_HOSTLANE_SIGN" 2 "NOT_IN_HOSTLANE" 3 "HIGHWAY_EXIT_SIGN (Reserved)" 4 "SIGN_ON_TURN (Reserved)" 5 "FAR_IRRELEVANT_SIGN (Reserved)";
VAL_ 1325 TSR_Filter_Type_52Dh 0 "Not filtered" 1 "Irrelevant to the host driver" 2 "On vehicle/truck" 3 "Embedded(Reserved)" 4 "RESERVED" 5 "RESERVED" 6 "RESERVED" 7 "RESERVED";
VAL_ 1325 TSR_Approved_Flag_52Dh 0 "Not Approved" 1 "Approved";
VAL_ 1327 TSRTrafficSignType_52Fh 0 "C_Other" 1 "C_Unknown" 2 "Construction" 3 "FP_Accessory_Arrow" 4 "FP_Building" 5 "FP_Circular_Marker" 6 "FP_Head" 7 "FP_Light_Arrow" 8 "FP_Light_Circle" 9 "FP_Light_Shell" 10 "FP_Mirror" 11 "FP_Other" 12 "FP_Polygon_Marker" 13 "FP_Route_Number" 14 "FP_Twig" 15 "FP_Unknown" 16 "FP_Vehicle_Wheel" 17 "GSGW_Misc" 18 "GSGW_Other" 19 "GSGW_Unknown" 20 "GSWB_Misc" 21 "GSWB_Other" 22 "GSWB_Unknown" 23 "G_GuideSign_GreenWhite" 24 "G_GuideSign_WhiteBlack" 25 "GuideSign_MultiMisc" 26 "IR_AccidentPronePoint" 27 "IR_Accommodation" 28 "IR_AdministrativeBoundary" 29 "IR_Airport" 30 "IR_Area" 31 "IR_AvoidLine" 32 "IR_BifurcationMark" 33 "IR_BigCarRight" 34 "IR_Blocked" 35 "IR_BusStation" 36 "IR_CarRepair" 37 "IR_CarWash" 38 "IR_CateringServices" 39 "IR_CombinationAuxiliary" 40 "IR_ContinuousDownhill" 41 "IR_CountryRoadNumMark" 42 "IR_CrossIntersection" 43 "IR_CrossingMarking" 44 "IR_DisabledSpecial" 45 "IR_DistanceArea" 46 "IR_Drink" 47 "IR_DrivingDirection" 48 "IR_ETCLanes" 49 "IR_ElectricalETC" 50 "IR_EmergencyShelter" 51 "IR_FamousPlaceName" 52 "IR_Ferry" 53 "IR_FerryPier" 54 "IR_FirstAidStation" 55 "IR_Foggy" 56 "IR_FootBridge" 57 "IR_GasStation" 58 "IR_HighwayCarDistanceConfirmation" 59 "IR_HighwayClimbingLine" 60 "IR_HighwayDirection" 61 "IR_HighwayETCLanes" 62 "IR_HighwayETCTollStationsNotice" 63 "IR_HighwayEmergencyParkingBelt" 64 "IR_HighwayEmergencyPhone" 65 "IR_HighwayEnd" 66 "IR_HighwayEndNotice" 67 "IR_HighwayEntrance" 68 "IR_HighwayEntranceNotice" 69 "IR_HighwayExit" 70 "IR_HighwayExitNotice" 71 "IR_HighwayGasStation" 72 "IR_HighwayHundredCard" 73 "IR_HighwayLocationDirection" 74 "IR_HighwayLocationDistance" 75 "IR_HighwayMileageCard" 76 "IR_HighwayName" 77 "IR_HighwayNextExitNotice" 78 "IR_HighwayOverloadCheck" 79 "IR_HighwayParkinAreaNotice" 80 "IR_HighwayParkingLotNotice" 81 "IR_HighwayRescueCall" 82 "IR_HighwayRoadTrafficInformation" 83 "IR_HighwayServiceNotice" 84 "IR_HighwaySlowDown" 85 "IR_HighwayStart" 86 "IR_HighwayTicket" 87 "IR_HighwayTollStationsNotice" 88 "IR_Interchange" 89 "IR_IntersectionNotice" 90 "IR_LanesDecrease" 91 "IR_LanesIncrease" 92 "IR_Linearguide" 93 "IR_LocationDistance" 94 "IR_LongDistanceBusStation" 95 "IR_MilePost" 96 "IR_MobileConstruction" 97 "IR_Nameplate" 98 "IR_Parking" 99 "IR_ParkingLot" 100 "IR_PassingTime" 101 "IR_PedestrianTunnel" 102 "IR_PedestrianUnderpass" 103 "IR_PlaceName" 104 "IR_Police" 105 "IR_Port" 106 "IR_ProtectAnimals" 107 "IR_Quarantine" 108 "IR_RailwayStation" 109 "IR_Ramp" 110 "IR_RampArrow" 111 "IR_RestArea" 112 "IR_RoadManageBoundary" 113 "IR_RoadStop" 114 "IR_SlowRoad" 115 "IR_Snack" 116 "IR_SoftFoundation" 117 "IR_SteepSlope" 118 "IR_StreetName" 119 "IR_SubwayStation" 120 "IR_Taxi" 121 "IR_Tcorssing" 122 "IR_TouristAreaDirectionDistance" 123 "IR_TrafficSupervisory" 124 "IR_TransferCenter" 125 "IR_TransverseWind" 126 "IR_TravelSymbols" 127 "IR_Tunnel" 128 "IR_TunnelNextExitNotice" 129 "IR_VehicleType" 130 "IR_ViewingPoint" 131 "IR_WarningReason" 132 "IR_WeightCharge" 133 "IR_Ycorssing" 134 "IR_Zones" 135 "IR_ZonesII" 136 "I_AllowUturn" 137 "I_Circle" 138 "I_FastBusLane" 139 "I_Forward" 140 "I_ForwardLane" 141 "I_ForwardLeft" 142 "I_ForwardLeftLane" 143 "I_ForwardLeftStereo" 144 "I_ForwardRight" 145 "I_ForwardRightLane" 146 "I_ForwardRightStereo" 147 "I_Honk" 148 "I_Left" 149 "I_LeftBusLane" 150 "I_LeftLine" 151 "I_LeftRight" 152 "I_LeftTurn" 153 "I_LeftTurnLane" 154 "I_MinSpeedLim100" 155 "I_MinSpeedLim110" 156 "I_MinSpeedLim40" 157 "I_MinSpeedLim50" 158 "I_MinSpeedLim60" 159 "I_MinSpeedLim70" 160 "I_MinSpeedLim80" 161 "I_MinSpeedLim90" 162 "I_Motors" 163 "I_MotorsLane" 164 "I_MultiOccupantMotorsLane" 165 "I_NonMotors" 166 "I_NonMotorsLane" 167 "I_Other_circle" 168 "I_Other_rectangle" 169 "I_ParkingSpace" 170 "I_Passingfirst" 171 "I_PedestrianCross" 172 "I_PriorityIntereesction" 173 "I_Right" 174 "I_RightLine" 175 "I_RightTurn" 176 "I_RightTurnLane" 177 "I_SplitDriveLine" 178 "I_StraightLine" 179 "I_UTurnAndLeftLane" 180 "I_UTurnLane" 181 "I_Unknown_circle" 182 "I_Unknown_rectangle" 183 "I_Uturn" 184 "I_Walk" 185 "MSL_Other" 186 "MSL_Unknown" 187 "MinSpeedLim100" 188 "MinSpeedLim110" 189 "MinSpeedLim50" 190 "MinSpeedLim60" 191 "MinSpeedLim70" 192 "MinSpeedLim80" 193 "MinSpeedLim90" 194 "NoPassingRev" 195 "O_Other" 196 "Other" 197 "Other_Construction_Sign" 198 "Other_Detfp" 199 "Other_Exit" 200 "Other_GuideSign_BlueWhite" 201 "Other_GuideSign_GreenWhite" 202 "Other_GuideSign_WhiteBlack" 203 "Other_Indications" 204 "Other_LightArrow" 205 "Other_Min_Speed" 206 "Other_Mirror" 207 "Other_NoParking" 208 "Other_Prohibit" 209 "Other_RedCircleLight" 210 "Other_RouteID_RedWhite" 211 "Other_RouteID_YellowBlack" 212 "Other_TravelSign_BrownWhite" 213 "Other_Warning" 214 "PR_Other" 215 "PR_Unknown" 216 "PSL_Other" 217 "PSL_Unknown" 218 "P_Custom" 219 "P_GiveWay" 220 "P_HeightLim" 221 "P_MultiVehicle" 222 "P_NoAnimalVehicle" 223 "P_NoBikeDownSlope" 224 "P_NoBikeUpSlope" 225 "P_NoBus" 226 "P_NoCar" 227 "P_NoCargoTricycle" 228 "P_NoDangerous" 229 "P_NoEntry" 230 "P_NoForward" 231 "P_NoForwardLeft" 232 "P_NoForwardRight" 233 "P_NoHorning" 234 "P_NoHuman" 235 "P_NoHumanCargoTriangle" 236 "P_NoHumanPassengerTriangle" 237 "P_NoHumanVehicle" 238 "P_NoLeftRightTurn" 239 "P_NoLeftTurn" 240 "P_NoLongParking" 241 "P_NoLongParkingRev" 242 "P_NoMinibus" 243 "P_NoMotoTricycle" 244 "P_NoMotor" 245 "P_NoMotorcycle" 246 "P_NoNonMotor" 247 "P_NoParking" 248 "P_NoParkingRev" 249 "P_NoPassing" 250 "P_NoPassingRev" 251 "P_NoReturn" 252 "P_NoRightTurn" 253 "P_NoSpecificLeftTurn" 254 "P_NoSpecificRightTurn" 255 "P_NoTractor" 256 "P_NoTrailer" 257 "P_NoTricycle" 258 "P_NoTruck" 259 "P_Noway" 260 "P_Other1" 261 "P_Other_SpeedLimele" 262 "P_ParkingCheck" 263 "P_SlowFor" 264 "P_SpeedLim10" 265 "P_SpeedLim100" 266 "P_SpeedLim100ele" 267 "P_SpeedLim105" 268 "P_SpeedLim110" 269 "P_SpeedLim110ele" 270 "P_SpeedLim115" 271 "P_SpeedLim120" 272 "P_SpeedLim120ele" 273 "P_SpeedLim15" 274 "P_SpeedLim20" 275 "P_SpeedLim20ele" 276 "P_SpeedLim25" 277 "P_SpeedLim30" 278 "P_SpeedLim30ele" 279 "P_SpeedLim35" 280 "P_SpeedLim40" 281 "P_SpeedLim40ele" 282 "P_SpeedLim45" 283 "P_SpeedLim5" 284 "P_SpeedLim50" 285 "P_SpeedLim50ele" 286 "P_SpeedLim55" 287 "P_SpeedLim60" 288 "P_SpeedLim60ele" 289 "P_SpeedLim65" 290 "P_SpeedLim70" 291 "P_SpeedLim70ele" 292 "P_SpeedLim75" 293 "P_SpeedLim80" 294 "P_SpeedLim80ele" 295 "P_SpeedLim85" 296 "P_SpeedLim90" 297 "P_SpeedLim90ele" 298 "P_SpeedLim95" 299 "P_SpeedLimRev" 300 "P_SpeedLimRev10" 301 "P_SpeedLimRev100" 302 "P_SpeedLimRev105" 303 "P_SpeedLimRev110" 304 "P_SpeedLimRev115" 305 "P_SpeedLimRev120" 306 "P_SpeedLimRev15" 307 "P_SpeedLimRev20" 308 "P_SpeedLimRev25" 309 "P_SpeedLimRev30" 310 "P_SpeedLimRev35" 311 "P_SpeedLimRev40" 312 "P_SpeedLimRev45" 313 "P_SpeedLimRev5" 314 "P_SpeedLimRev50" 315 "P_SpeedLimRev55" 316 "P_SpeedLimRev60" 317 "P_SpeedLimRev65" 318 "P_SpeedLimRev70" 319 "P_SpeedLimRev75" 320 "P_SpeedLimRev80" 321 "P_SpeedLimRev85" 322 "P_SpeedLimRev90" 323 "P_SpeedLimRev95" 324 "P_StopFor" 325 "P_Unknow_SpeedLimele" 326 "P_Unknown1" 327 "P_VehicleOther" 328 "P_WeightLim" 329 "P_WeightLimWheel" 330 "P_WidthLim" 331 "RSBW_Misc" 332 "RSBW_Other" 333 "RSBW_Unknown" 334 "R_CircularIntersection" 335 "R_RoadSign_BlueWhite" 336 "RouteID_HighwayMark" 337 "RouteID_Other" 338 "RouteID_RedWhite" 339 "RouteID_TownRoadMark" 340 "RouteID_Unknown" 341 "RouteID_YellowBlack" 342 "SpeedLim10" 343 "SpeedLim100" 344 "SpeedLim100_electric" 345 "SpeedLim110" 346 "SpeedLim110_electric" 347 "SpeedLim120" 348 "SpeedLim120_electric" 349 "SpeedLim15" 350 "SpeedLim20" 351 "SpeedLim25" 352 "SpeedLim30" 353 "SpeedLim30_electric" 354 "SpeedLim35" 355 "SpeedLim40" 356 "SpeedLim40_electric" 357 "SpeedLim5" 358 "SpeedLim50" 359 "SpeedLim50_electric" 360 "SpeedLim55" 361 "SpeedLim5_electric" 362 "SpeedLim60" 363 "SpeedLim60_electric" 364 "SpeedLim65" 365 "SpeedLim70" 366 "SpeedLim70_electric" 367 "SpeedLim80" 368 "SpeedLim80_electric" 369 "SpeedLim90" 370 "SpeedLim90_electric" 371 "SpeedLimRev" 372 "TSBW_Other" 373 "TSBW_Unknown" 374 "T_TravelSign_BrownWhite" 375 "U_Unknown" 376 "W_AccidentProne" 377 "W_Animal" 378 "W_BadWeather" 379 "W_Bump" 380 "W_Bumpy" 381 "W_Children" 382 "W_Circle" 383 "W_ContinuousDown" 384 "W_ContinuousTurn" 385 "W_Cross" 386 "W_CrossIntersection" 387 "W_CrossLaneRail" 388 "W_Cycle" 389 "W_DamLeft" 390 "W_DamRight" 391 "W_Danger" 392 "W_DetourAround" 393 "W_DetourLeft" 394 "W_DetourRight" 395 "W_Disabled" 396 "W_Domestic" 397 "W_Down" 398 "W_EmergencyLane" 399 "W_Ferry" 400 "W_Fog" 401 "W_Ford" 402 "W_GuardedRailway" 403 "W_HumpBridge" 404 "W_Ice" 405 "W_KeepDistance" 406 "W_LRNarrow" 407 "W_LRTurn" 408 "W_LeftFalling" 409 "W_LeftNarrow" 410 "W_LeftTurn" 411 "W_LowLying" 412 "W_MergeLeft" 413 "W_MergeRight" 414 "W_MountLeft" 415 "W_MountRight" 416 "W_NarrowBridge" 417 "W_Other" 418 "W_Pedestrian" 419 "W_RLTurn" 420 "W_Railway" 421 "W_Rain" 422 "W_RightFalling" 423 "W_RightNarrow" 424 "W_RightTurn" 425 "W_SideWind" 426 "W_Side_Wind" 427 "W_Slash" 428 "W_Slip" 429 "W_Slow" 430 "W_SlowDown" 431 "W_SplitLeft" 432 "W_SplitRight" 433 "W_TIntersection" 434 "W_TShap" 435 "W_TShapLeft" 436 "W_TShapRight" 437 "W_Tidal" 438 "W_TrafficLight" 439 "W_Tripod" 440 "W_Tshape" 441 "W_Tshaps" 442 "W_Tunnel" 443 "W_TunnelHeadlight" 444 "W_TwoWay" 445 "W_Unknown" 446 "W_Up" 447 "W_VehicleQueue" 448 "W_Village" 449 "W_Working" 450 "W_YBLeft" 451 "W_YBRight" 452 "W_YB_Left" 453 "W_YB_Right" 454 "W_YLeft" 455 "W_YRight" 456 "W_Y_Left" 457 "W_Y_Right" 458 "sign_back" 459 "Other_IndicationsCircle" 460 "Other_IndicationsRectangle" 461 "Other_Circular_Marker" 462 "False_Positive" 463 "FP_Light_Time" 464 "RouteSign_Misc" 465 "Multi_Misc";
VAL_ 1327 TSR_Relevancy_52Fh 0 "Undefined" 1 "IN_HOSTLANE_SIGN" 2 "NOT_IN_HOSTLANE" 3 "HIGHWAY_EXIT_SIGN (Reserved)" 4 "SIGN_ON_TURN (Reserved)" 5 "FAR_IRRELEVANT_SIGN (Reserved)";
VAL_ 1327 TSR_Filter_Type_52Fh 0 "Not filtered" 1 "Irrelevant to the host driver" 2 "On vehicle/truck" 3 "Embedded(Reserved)" 4 "RESERVED" 5 "RESERVED" 6 "RESERVED" 7 "RESERVED";
VAL_ 1327 TSR_Approved_Flag_52Fh 0 "Not Approved" 1 "Approved";
VAL_ 1330 TFL_Color_532h 0 "Unknown" 1 "Red" 2 "Green" 3 "Yellow" 4 "Other" 5 "Off";
VAL_ 1330 TFL_ShapeType_532h 0 "Unknown/Unsupported" 1 "Vertical 3-light" 2 "Horizontal 3-light";
VAL_ 1330 TFL_ClassificationType_532h 0 "Unknown" 1 "L_Circle" 2 "L_Forward" 3 "L_Left" 4 "L_Right" 5 "L_Return" 6 "L_Pedestrian" 7 "L_Non_Motor" 8 "L_Time" 9 "L_Other (Reserved)" 10 "L_left_and_return" 11 "L_Forward_and_Left" 12 "L_Forward_and_Right" 13 "L_No_Drive_into" 14 "L_Allow_Drive_into" 15 "text_of_allow_ped (Reserved)" 16 "sign_of_allow_ped (Reserved)" 17 "text_of_forbid_ped (Reserved)" 18 "sign_of_forbid_ped (Reserved)";
VAL_ 1330 is_TFL_Blinking_532h 0 "No_Blinking" 1 "Blinking";
VAL_ 1331 TFL_Color_533h 0 "Unknown" 1 "Red" 2 "Green" 3 "Yellow" 4 "Other" 5 "Off";
VAL_ 1331 TFL_ShapeType_533h 0 "Unknown/Unsupported" 1 "Vertical 3-light" 2 "Horizontal 3-light";
VAL_ 1331 TFL_ClassificationType_533h 0 "Unknown" 1 "L_Circle" 2 "L_Forward" 3 "L_Left" 4 "L_Right" 5 "L_Return" 6 "L_Pedestrian" 7 "L_Non_Motor" 8 "L_Time" 9 "L_Other (Reserved)" 10 "L_left_and_return" 11 "L_Forward_and_Left" 12 "L_Forward_and_Right" 13 "L_No_Drive_into" 14 "L_Allow_Drive_into" 15 "text_of_allow_ped (Reserved)" 16 "sign_of_allow_ped (Reserved)" 17 "text_of_forbid_ped (Reserved)" 18 "sign_of_forbid_ped (Reserved)";
VAL_ 1331 is_TFL_Blinking_533h 0 "No_Blinking" 1 "Blinking";
VAL_ 1332 TFL_Color_534h 0 "Unknown" 1 "Red" 2 "Green" 3 "Yellow" 4 "Other" 5 "Off";
VAL_ 1332 TFL_ShapeType_534h 0 "Unknown/Unsupported" 1 "Vertical 3-light" 2 "Horizontal 3-light";
VAL_ 1332 TFL_ClassificationType_534h 0 "Unknown" 1 "L_Circle" 2 "L_Forward" 3 "L_Left" 4 "L_Right" 5 "L_Return" 6 "L_Pedestrian" 7 "L_Non_Motor" 8 "L_Time" 9 "L_Other (Reserved)" 10 "L_left_and_return" 11 "L_Forward_and_Left" 12 "L_Forward_and_Right" 13 "L_No_Drive_into" 14 "L_Allow_Drive_into" 15 "text_of_allow_ped (Reserved)" 16 "sign_of_allow_ped (Reserved)" 17 "text_of_forbid_ped (Reserved)" 18 "sign_of_forbid_ped (Reserved)";
VAL_ 1332 is_TFL_Blinking_534h 0 "Not Blinking" 1 "Blinking";
VAL_ 1333 TFL_Color_535h 0 "Unknown" 1 "Red" 2 "Green" 3 "Yellow" 4 "Other" 5 "Off";
VAL_ 1333 TFL_ShapeType_535h 0 "Unknown/Unsupported" 1 "Vertical 3-light" 2 "Horizontal 3-light";
VAL_ 1333 TFL_ClassificationType_535h 0 "Unknown" 1 "L_Circle" 2 "L_Forward" 3 "L_Left" 4 "L_Right" 5 "L_Return" 6 "L_Pedestrian" 7 "L_Non_Motor" 8 "L_Time" 9 "L_Other (Reserved)" 10 "L_left_and_return" 11 "L_Forward_and_Left" 12 "L_Forward_and_Right" 13 "L_No_Drive_into" 14 "L_Allow_Drive_into" 15 "text_of_allow_ped (Reserved)" 16 "sign_of_allow_ped (Reserved)" 17 "text_of_forbid_ped (Reserved)" 18 "sign_of_forbid_ped (Reserved)";
VAL_ 1333 is_TFL_Blinking_535h 0 "No_Blinking" 1 "Blinking";
VAL_ 1334 TFL_Color_536h 0 "Unknown" 1 "Red" 2 "Green" 3 "Yellow" 4 "Other" 5 "Off";
VAL_ 1334 TFL_ShapeType_536h 0 "Unknown/Unsupported" 1 "Vertical 3-light" 2 "Horizontal 3-light";
VAL_ 1334 TFL_ClassificationType_536h 0 "Unknown" 1 "L_Circle" 2 "L_Forward" 3 "L_Left" 4 "L_Right" 5 "L_Return" 6 "L_Pedestrian" 7 "L_Non_Motor" 8 "L_Time" 9 "L_Other (Reserved)" 10 "L_left_and_return" 11 "L_Forward_and_Left" 12 "L_Forward_and_Right" 13 "L_No_Drive_into" 14 "L_Allow_Drive_into" 15 "text_of_allow_ped (Reserved)" 16 "sign_of_allow_ped (Reserved)" 17 "text_of_forbid_ped (Reserved)" 18 "sign_of_forbid_ped (Reserved)";
VAL_ 1334 is_TFL_Blinking_536h 0 "No_Blinking" 1 "Blinking";
VAL_ 1335 TFL_Color_537h 0 "Unknown" 1 "Red" 2 "Green" 3 "Yellow" 4 "Other" 5 "Off";
VAL_ 1335 TFL_ShapeType_537h 0 "Unknown/Unsupported" 1 "Vertical 3-light" 2 "Horizontal 3-light";
VAL_ 1335 TFL_ClassificationType_537h 0 "Unknown" 1 "L_Circle" 2 "L_Forward" 3 "L_Left" 4 "L_Right" 5 "L_Return" 6 "L_Pedestrian" 7 "L_Non_Motor" 8 "L_Time" 9 "L_Other (Reserved)" 10 "L_left_and_return" 11 "L_Forward_and_Left" 12 "L_Forward_and_Right" 13 "L_No_Drive_into" 14 "L_Allow_Drive_into" 15 "text_of_allow_ped (Reserved)" 16 "sign_of_allow_ped (Reserved)" 17 "text_of_forbid_ped (Reserved)" 18 "sign_of_forbid_ped (Reserved)";
VAL_ 1335 is_TFL_Blinking_537h 0 "No_Blinking" 1 "Blinking";
VAL_ 1336 TFL_Color_538h 0 "Unknown" 1 "Red" 2 "Green" 3 "Yellow" 4 "Other" 5 "Off";
VAL_ 1336 TFL_ShapeType_538h 0 "Unknown/Unsupported" 1 "Vertical 3-light" 2 "Horizontal 3-light";
VAL_ 1336 TFL_ClassificationType_538h 0 "Unknown" 1 "L_Circle" 2 "L_Forward" 3 "L_Left" 4 "L_Right" 5 "L_Return" 6 "L_Pedestrian" 7 "L_Non_Motor" 8 "L_Time" 9 "L_Other (Reserved)" 10 "L_left_and_return" 11 "L_Forward_and_Left" 12 "L_Forward_and_Right" 13 "L_No_Drive_into" 14 "L_Allow_Drive_into" 15 "text_of_allow_ped (Reserved)" 16 "sign_of_allow_ped (Reserved)" 17 "text_of_forbid_ped (Reserved)" 18 "sign_of_forbid_ped (Reserved)";
VAL_ 1336 is_TFL_Blinking_538h 0 "No_Blinking" 1 "Blinking";
VAL_ 1337 TFL_Color_539h 0 "Unknown" 1 "Red" 2 "Green" 3 "Yellow" 4 "Other" 5 "Off";
VAL_ 1337 TFL_ShapeType_539h 0 "Unknown/Unsupported" 1 "Vertical 3-light" 2 "Horizontal 3-light";
VAL_ 1337 TFL_ClassificationType_539h 0 "Unknown" 1 "L_Circle" 2 "L_Forward" 3 "L_Left" 4 "L_Right" 5 "L_Return" 6 "L_Pedestrian" 7 "L_Non_Motor" 8 "L_Time" 9 "L_Other (Reserved)" 10 "L_left_and_return" 11 "L_Forward_and_Left" 12 "L_Forward_and_Right" 13 "L_No_Drive_into" 14 "L_Allow_Drive_into" 15 "text_of_allow_ped (Reserved)" 16 "sign_of_allow_ped (Reserved)" 17 "text_of_forbid_ped (Reserved)" 18 "sign_of_forbid_ped (Reserved)";
VAL_ 1337 is_TFL_Blinking_539h 0 "No_Blinking" 1 "Blinking";
